VERSION ""

NS_ :

BS_:

BU_: Turbocharger OnBoardDataLogger OffBoardDiagnosticTool2 OffBoardDiagnosticTool1 FileServer ParkingBrakeController SeatControl2 FanDriveController SteeringColumnUnit CommunicationUnitRadio CommunicationUnitSatellite CommunicationUnitCellular PropulsionBatteryCharger ChassisController2 ChassisController1 EngineValveControl AuxiliaryHeater2 AuxiliaryHeater1 ClutchUnit RampControl InformationSystem1 SuspensionSystemController2 OilSensor VehicleDynamicStability ExhaustEmissionController TransmissionDisplay2 TransmissionDisplay1 ClimateControl2 WaterPumpController RearAxleSteeringController LightingOperatorControl SeatController1 IgnitionController2 IgnitionController1 TirePressureController CabController2 CabController1 PneumaticSystemController SuspensionSystemController1 HydraulicPumpController EnduranceBrakingSystem RetarderExhaustEngine2 OnBoardDiagnosticUnit HeadwayController RetarderExhaustEngine1 CabDisplay1 ManagementComputer VirtualTerminal OffVehicleGateway PowerTakeOffFront HitchControl AuxiliaryValveControl BodyController TractorTrailerBridge1 StarterSystem ElectricalSystem VehicleSecurity VehicleNavigation AerodynamicControl ElectricalChargingSystem ClimateControl1 TripRecorder InstrumentCluster SuspensionDriveAxle2 SuspensionDriveAxle1 SuspensionSteerAxle SteeringController FuelSystem CruiseControl RetarderDriveline RetarderEngine BrakesDriveAxle2 BrakesDriveAxle1 BrakesSystemController BrakesSteerAxle AxleDrive2 AxleDrive1 AxleSteering PowerTakeOff ShiftConsoleSecondary ShiftConsolePrimary Transmission2 Transmission1 Engine2 Engine1

BO_ 2365473278 LC: 8 Vector__XXX
 SG_ ImplementRearWorkLightCmd : 62|2@1+ (1,0) [0|3] "" Vector__XXX
 SG_ ImplementLeftForwardWorkLightCmd : 60|2@1+ (1,0) [0|3] "" Vector__XXX
 SG_ ImplmentRightForwardWorkLightCmd : 58|2@1+ (1,0) [0|3] "" Vector__XXX
 SG_ LightingDataRqCmd : 56|2@1+ (1,0) [0|3] "" Vector__XXX
 SG_ ImplementLeftFacingWorkLightCmd : 54|2@1+ (1,0) [0|3] "" Vector__XXX
 SG_ ImplementRightFacingWorkLightCmd : 52|2@1+ (1,0) [0|3] "" Vector__XXX
 SG_ ImplementOEMOption1LightCmd : 50|2@1+ (1,0) [0|3] "" Vector__XXX
 SG_ ImplementOEMOption2LightCmd : 48|2@1+ (1,0) [0|3] "" Vector__XXX
 SG_ TrctrFrntHghMountedWorkLightsCmd : 46|2@1+ (1,0) [0|3] "" Vector__XXX
 SG_ TrctrFrntLowMountedWorkLightsCmd : 44|2@1+ (1,0) [0|3] "" Vector__XXX
 SG_ TrctrSdeHighMountedWorkLightsCmd : 42|2@1+ (1,0) [0|3] "" Vector__XXX
 SG_ TrctrSideLowMountedWorkLightsCmd : 40|2@1+ (1,0) [0|3] "" Vector__XXX
 SG_ TrctrRarHighMountedWorkLightsCmd : 38|2@1+ (1,0) [0|3] "" Vector__XXX
 SG_ TrctrRearLowMountedWorkLightsCmd : 36|2@1+ (1,0) [0|3] "" Vector__XXX
 SG_ TrctrUndrsdeMountedWorkLightsCmd : 34|2@1+ (1,0) [0|3] "" Vector__XXX
 SG_ RearFogLightCmd : 32|2@1+ (1,0) [0|3] "" Vector__XXX
 SG_ TractorMarkerLightCmd : 30|2@1+ (1,0) [0|3] "" Vector__XXX
 SG_ ImplementMarkerLightCmd : 28|2@1+ (1,0) [0|3] "" Vector__XXX
 SG_ TractorClearanceLightCmd : 26|2@1+ (1,0) [0|3] "" Vector__XXX
 SG_ ImplementClearanceLightCmd : 24|2@1+ (1,0) [0|3] "" Vector__XXX
 SG_ LeftStopLightCmd : 22|2@1+ (1,0) [0|3] "" Vector__XXX
 SG_ RightStopLightCmd : 20|2@1+ (1,0) [0|3] "" Vector__XXX
 SG_ CenterStopLightCmd : 18|2@1+ (1,0) [0|3] "" Vector__XXX
 SG_ BackUpLightAndAlarmHornCmd : 16|2@1+ (1,0) [0|3] "" Vector__XXX
 SG_ LeftTurnSignalLightsCmd : 14|2@1+ (1,0) [0|3] "" Vector__XXX
 SG_ RightTurnSignalLightsCmd : 12|2@1+ (1,0) [0|3] "" Vector__XXX
 SG_ RotatingBeaconLightCmd : 10|2@1+ (1,0) [0|3] "" Vector__XXX
 SG_ TractorFrontFogLightsCmd : 8|2@1+ (1,0) [0|3] "" Vector__XXX
 SG_ HighBeamHeadLightCmd : 6|2@1+ (1,0) [0|3] "" Vector__XXX
 SG_ LowBeamHeadLightCmd : 4|2@1+ (1,0) [0|3] "" Vector__XXX
 SG_ AltBeamHeadLightCmd : 2|2@1+ (1,0) [0|3] "" Vector__XXX
 SG_ RunningLightCmd : 0|2@1+ (1,0) [0|3] "" Vector__XXX

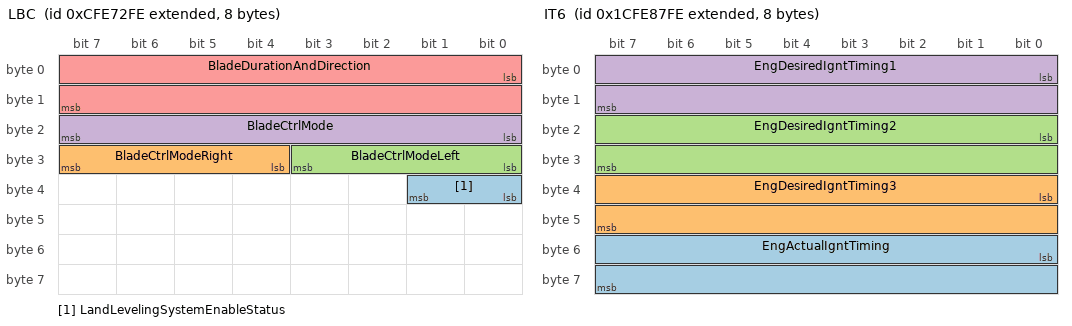
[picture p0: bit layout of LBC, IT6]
BO_ 2365485822 LBC: 8 Vector__XXX
 SG_ LandLevelingSystemEnableStatus : 32|2@1+ (1,0) [0|3] "" Vector__XXX
 SG_ BladeCtrlModeRight : 28|4@1+ (1,0) [0|15] "" Vector__XXX
 SG_ BladeCtrlModeLeft : 24|4@1+ (1,0) [0|15] "" Vector__XXX
 SG_ BladeCtrlMode : 16|8@1+ (1,0) [0|255] "" Vector__XXX
 SG_ BladeDurationAndDirection : 0|16@1+ (1,-3276.8) [-3276.8|3148.7] "sec" Vector__XXX

BO_ 2633926654 IT6: 8 Vector__XXX
 SG_ EngActualIgntTiming : 48|16@1+ (1,-200) [-200|301.99] "deg" Vector__XXX
 SG_ EngDesiredIgntTiming3 : 32|16@1+ (1,-200) [-200|301.99] "deg" Vector__XXX
 SG_ EngDesiredIgntTiming2 : 16|16@1+ (1,-200) [-200|301.99] "deg" Vector__XXX
 SG_ EngDesiredIgntTiming1 : 0|16@1+ (1,-200) [-200|301.99] "deg" Vector__XXX

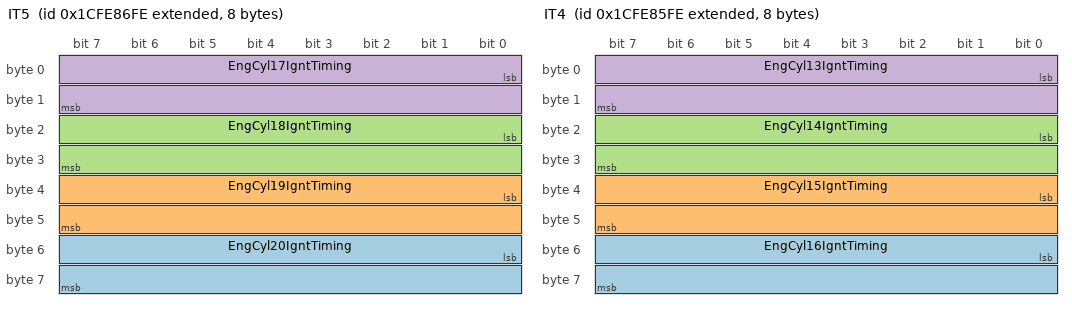
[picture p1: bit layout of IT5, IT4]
BO_ 2633926398 IT5: 8 Vector__XXX
 SG_ EngCyl20IgntTiming : 48|16@1+ (1,-200) [-200|301.99] "deg" Vector__XXX
 SG_ EngCyl19IgntTiming : 32|16@1+ (1,-200) [-200|301.99] "deg" Vector__XXX
 SG_ EngCyl18IgntTiming : 16|16@1+ (1,-200) [-200|301.99] "deg" Vector__XXX
 SG_ EngCyl17IgntTiming : 0|16@1+ (1,-200) [-200|301.99] "deg" Vector__XXX

BO_ 2633926142 IT4: 8 Vector__XXX
 SG_ EngCyl16IgntTiming : 48|16@1+ (1,-200) [-200|301.99] "deg" Vector__XXX
 SG_ EngCyl15IgntTiming : 32|16@1+ (1,-200) [-200|301.99] "deg" Vector__XXX
 SG_ EngCyl14IgntTiming : 16|16@1+ (1,-200) [-200|301.99] "deg" Vector__XXX
 SG_ EngCyl13IgntTiming : 0|16@1+ (1,-200) [-200|301.99] "deg" Vector__XXX

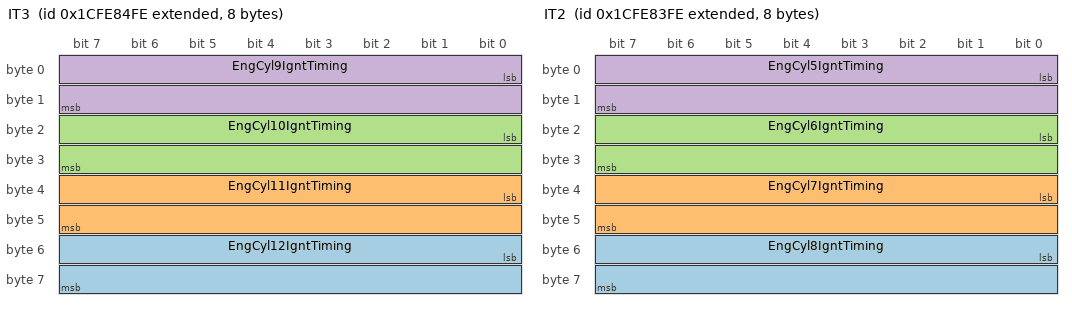
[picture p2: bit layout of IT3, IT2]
BO_ 2633925886 IT3: 8 Vector__XXX
 SG_ EngCyl12IgntTiming : 48|16@1+ (1,-200) [-200|301.99] "deg" Vector__XXX
 SG_ EngCyl11IgntTiming : 32|16@1+ (1,-200) [-200|301.99] "deg" Vector__XXX
 SG_ EngCyl10IgntTiming : 16|16@1+ (1,-200) [-200|301.99] "deg" Vector__XXX
 SG_ EngCyl9IgntTiming : 0|16@1+ (1,-200) [-200|301.99] "deg" Vector__XXX

BO_ 2633925630 IT2: 8 Vector__XXX
 SG_ EngCyl8IgntTiming : 48|16@1+ (1,-200) [-200|301.99] "deg" Vector__XXX
 SG_ EngCyl7IgntTiming : 32|16@1+ (1,-200) [-200|301.99] "deg" Vector__XXX
 SG_ EngCyl6IgntTiming : 16|16@1+ (1,-200) [-200|301.99] "deg" Vector__XXX
 SG_ EngCyl5IgntTiming : 0|16@1+ (1,-200) [-200|301.99] "deg" Vector__XXX

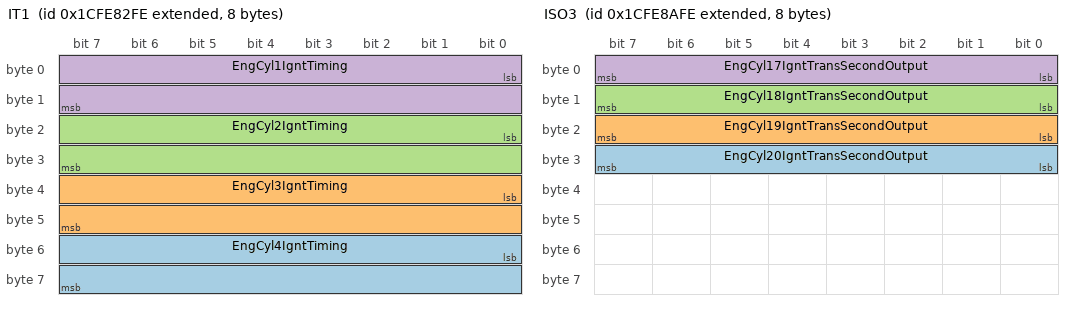
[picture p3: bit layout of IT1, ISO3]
BO_ 2633925374 IT1: 8 Vector__XXX
 SG_ EngCyl4IgntTiming : 48|16@1+ (1,-200) [-200|301.99] "deg" Vector__XXX
 SG_ EngCyl3IgntTiming : 32|16@1+ (1,-200) [-200|301.99] "deg" Vector__XXX
 SG_ EngCyl2IgntTiming : 16|16@1+ (1,-200) [-200|301.99] "deg" Vector__XXX
 SG_ EngCyl1IgntTiming : 0|16@1+ (1,-200) [-200|301.99] "deg" Vector__XXX

BO_ 2633927422 ISO3: 8 Vector__XXX
 SG_ EngCyl20IgntTransSecondOutput : 24|8@1+ (1,-125) [-125|125] "%" Vector__XXX
 SG_ EngCyl19IgntTransSecondOutput : 16|8@1+ (1,-125) [-125|125] "%" Vector__XXX
 SG_ EngCyl18IgntTransSecondOutput : 8|8@1+ (1,-125) [-125|125] "%" Vector__XXX
 SG_ EngCyl17IgntTransSecondOutput : 0|8@1+ (1,-125) [-125|125] "%" Vector__XXX

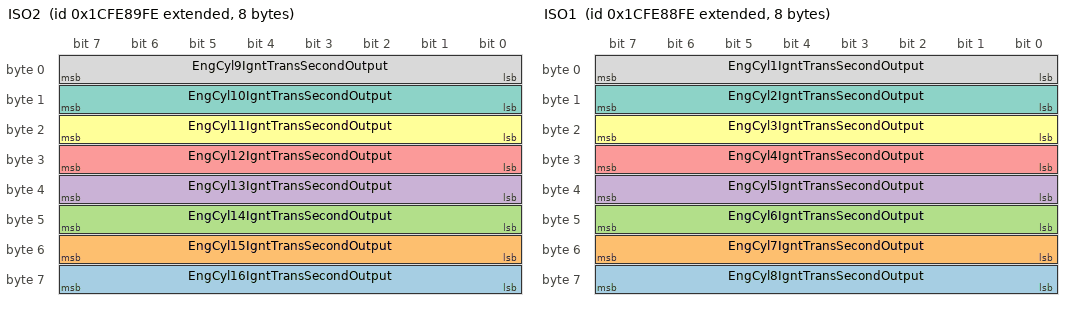
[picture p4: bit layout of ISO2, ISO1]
BO_ 2633927166 ISO2: 8 Vector__XXX
 SG_ EngCyl16IgntTransSecondOutput : 56|8@1+ (1,-125) [-125|125] "%" Vector__XXX
 SG_ EngCyl15IgntTransSecondOutput : 48|8@1+ (1,-125) [-125|125] "%" Vector__XXX
 SG_ EngCyl14IgntTransSecondOutput : 40|8@1+ (1,-125) [-125|125] "%" Vector__XXX
 SG_ EngCyl13IgntTransSecondOutput : 32|8@1+ (1,-125) [-125|125] "%" Vector__XXX
 SG_ EngCyl12IgntTransSecondOutput : 24|8@1+ (1,-125) [-125|125] "%" Vector__XXX
 SG_ EngCyl11IgntTransSecondOutput : 16|8@1+ (1,-125) [-125|125] "%" Vector__XXX
 SG_ EngCyl10IgntTransSecondOutput : 8|8@1+ (1,-125) [-125|125] "%" Vector__XXX
 SG_ EngCyl9IgntTransSecondOutput : 0|8@1+ (1,-125) [-125|125] "%" Vector__XXX

BO_ 2633926910 ISO1: 8 Vector__XXX
 SG_ EngCyl8IgntTransSecondOutput : 56|8@1+ (1,-125) [-125|125] "%" Vector__XXX
 SG_ EngCyl7IgntTransSecondOutput : 48|8@1+ (1,-125) [-125|125] "%" Vector__XXX
 SG_ EngCyl6IgntTransSecondOutput : 40|8@1+ (1,-125) [-125|125] "%" Vector__XXX
 SG_ EngCyl5IgntTransSecondOutput : 32|8@1+ (1,-125) [-125|125] "%" Vector__XXX
 SG_ EngCyl4IgntTransSecondOutput : 24|8@1+ (1,-125) [-125|125] "%" Vector__XXX
 SG_ EngCyl3IgntTransSecondOutput : 16|8@1+ (1,-125) [-125|125] "%" Vector__XXX
 SG_ EngCyl2IgntTransSecondOutput : 8|8@1+ (1,-125) [-125|125] "%" Vector__XXX
 SG_ EngCyl1IgntTransSecondOutput : 0|8@1+ (1,-125) [-125|125] "%" Vector__XXX

BO_ 2566768894 ISCS: 8 Vector__XXX
 SG_ EngOprtrPrmryIntrmdtSpdSlctState : 0|4@1+ (1,0) [0|15] "" Vector__XXX

BO_ 2566769406 ISC: 8 Vector__XXX
 SG_ EngOprtrPrmryIntrmdteSpeedSelect : 0|4@1+ (1,0) [0|15] "" Vector__XXX

BO_ 2566839550 IO: 8 Vector__XXX
 SG_ EngTotalIdleHours : 32|32@1+ (0.05,0) [0|210554060.75] "hr" Vector__XXX
 SG_ EngTotalIdleFuelUsed : 0|32@1+ (0.5,0) [0|2105540607.5] "L" Vector__XXX

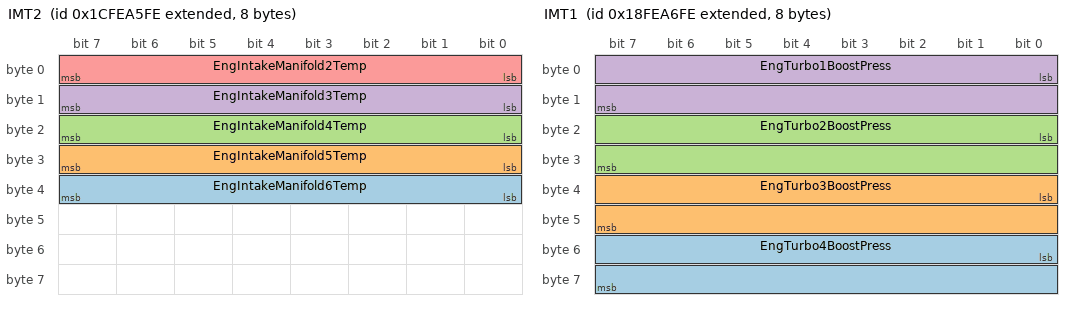
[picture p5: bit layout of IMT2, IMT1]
BO_ 2633934334 IMT2: 8 Vector__XXX
 SG_ EngIntakeManifold6Temp : 32|8@1+ (1,-40) [-40|210] "deg C" Vector__XXX
 SG_ EngIntakeManifold5Temp : 24|8@1+ (1,-40) [-40|210] "deg C" Vector__XXX
 SG_ EngIntakeManifold4Temp : 16|8@1+ (1,-40) [-40|210] "deg C" Vector__XXX
 SG_ EngIntakeManifold3Temp : 8|8@1+ (1,-40) [-40|210] "deg C" Vector__XXX
 SG_ EngIntakeManifold2Temp : 0|8@1+ (1,-40) [-40|210] "deg C" Vector__XXX

BO_ 2566825726 IMT1: 8 Vector__XXX
 SG_ EngTurbo4BoostPress : 48|16@1+ (0.125,0) [0|8031.875] "kPa" Vector__XXX
 SG_ EngTurbo3BoostPress : 32|16@1+ (0.125,0) [0|8031.875] "kPa" Vector__XXX
 SG_ EngTurbo2BoostPress : 16|16@1+ (0.125,0) [0|8031.875] "kPa" Vector__XXX
 SG_ EngTurbo1BoostPress : 0|16@1+ (0.125,0) [0|8031.875] "kPa" Vector__XXX

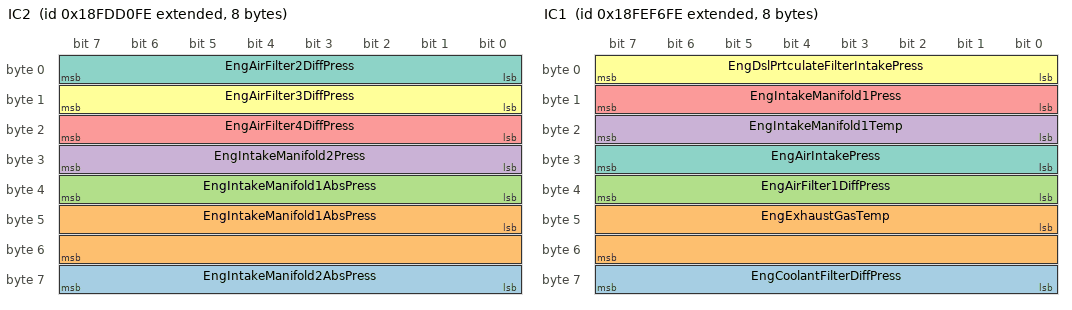
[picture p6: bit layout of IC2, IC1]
BO_ 2566770942 IC2: 8 Vector__XXX
 SG_ EngIntakeManifold2AbsPress : 56|8@1+ (2,0) [0|500] "kPa" Vector__XXX
 SG_ EngIntakeManifold1AbsPress : 40|16@1+ (0.1,0) [0|6425.5] "kPa" Vector__XXX
 SG_ EngIntakeManifold1AbsPress : 32|8@1+ (2,0) [0|500] "kPa" Vector__XXX
 SG_ EngIntakeManifold2Press : 24|8@1+ (2,0) [0|500] "kPa" Vector__XXX
 SG_ EngAirFilter4DiffPress : 16|8@1+ (0.05,0) [0|12.5] "kPa" Vector__XXX
 SG_ EngAirFilter3DiffPress : 8|8@1+ (0.05,0) [0|12.5] "kPa" Vector__XXX
 SG_ EngAirFilter2DiffPress : 0|8@1+ (0.05,0) [0|12.5] "kPa" Vector__XXX

BO_ 2566846206 IC1: 8 Vector__XXX
 SG_ EngCoolantFilterDiffPress : 56|8@1+ (0.5,0) [0|125] "kPa" Vector__XXX
 SG_ EngExhaustGasTemp : 40|16@1+ (0.03125,-273) [-273|1734.96875] "deg C" Vector__XXX
 SG_ EngAirFilter1DiffPress : 32|8@1+ (0.05,0) [0|12.5] "kPa" Vector__XXX
 SG_ EngIntakeManifold1Temp : 16|8@1+ (1,-40) [-40|210] "deg C" Vector__XXX
 SG_ EngIntakeManifold1Press : 8|8@1+ (2,0) [0|500] "kPa" Vector__XXX
 SG_ EngDslPrtculateFilterIntakePress : 0|8@1+ (0.5,0) [0|125] "kPa" Vector__XXX
 SG_ EngAirIntakePress : 24|8@1+ (2,0) [0|500] "kPa" Vector__XXX

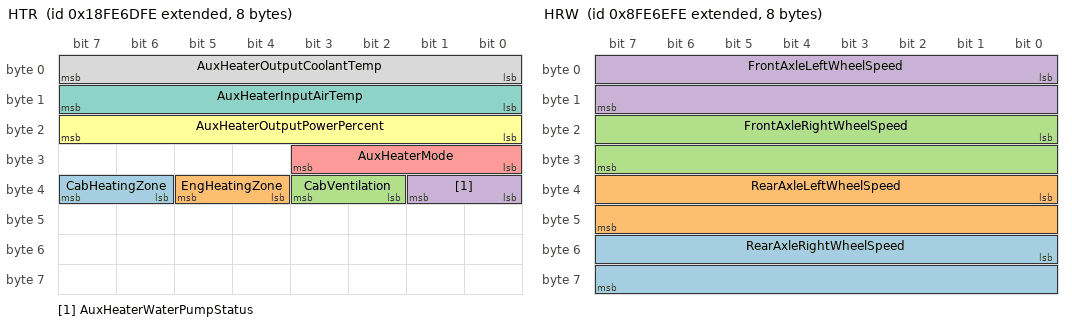
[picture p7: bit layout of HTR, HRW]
BO_ 2566811134 HTR: 8 Vector__XXX
 SG_ CabHeatingZone : 38|2@1+ (1,0) [0|3] "" Vector__XXX
 SG_ EngHeatingZone : 36|2@1+ (1,0) [0|3] "" Vector__XXX
 SG_ CabVentilation : 34|2@1+ (1,0) [0|3] "" Vector__XXX
 SG_ AuxHeaterWaterPumpStatus : 32|2@1+ (1,0) [0|3] "" Vector__XXX
 SG_ AuxHeaterMode : 24|4@1+ (1,0) [0|15] "" Vector__XXX
 SG_ AuxHeaterOutputPowerPercent : 16|8@1+ (0.4,0) [0|100] "%" Vector__XXX
 SG_ AuxHeaterInputAirTemp : 8|8@1+ (1,-40) [-40|210] "deg C" Vector__XXX
 SG_ AuxHeaterOutputCoolantTemp : 0|8@1+ (1,-40) [-40|210] "deg C" Vector__XXX

BO_ 2298375934 HRW: 8 Vector__XXX
 SG_ RearAxleRightWheelSpeed : 48|16@1+ (0.0039062485409696,0) [0|250.996] "km/h" Vector__XXX
 SG_ RearAxleLeftWheelSpeed : 32|16@1+ (0.0039062485409696,0) [0|250.996] "km/h" Vector__XXX
 SG_ FrontAxleRightWheelSpeed : 16|16@1+ (0.0039062485409696,0) [0|250.996] "km/h" Vector__XXX
 SG_ FrontAxleLeftWheelSpeed : 0|16@1+ (0.0039062485409696,0) [0|250.996] "km/h" Vector__XXX

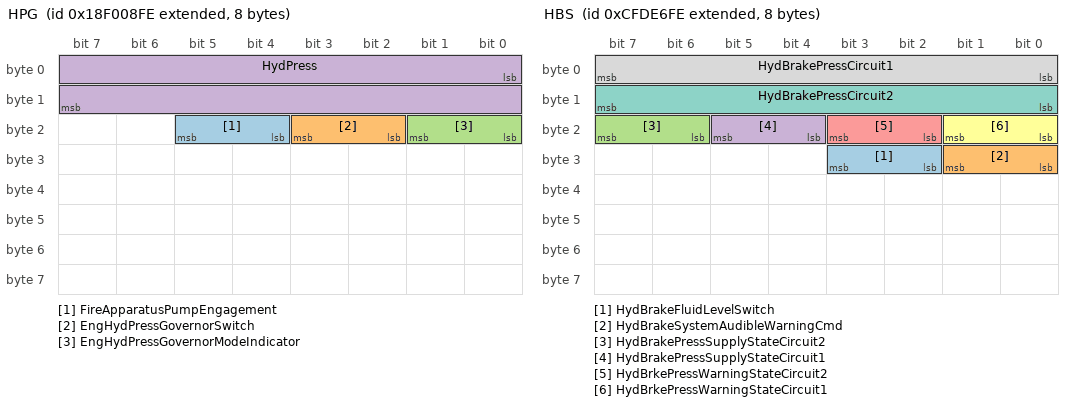
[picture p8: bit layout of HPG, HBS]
BO_ 2565867774 HPG: 8 Vector__XXX
 SG_ FireApparatusPumpEngagement : 20|2@1+ (1,0) [0|3] "" Vector__XXX
 SG_ EngHydPressGovernorSwitch : 18|2@1+ (1,0) [0|3] "" Vector__XXX
 SG_ EngHydPressGovernorModeIndicator : 16|2@1+ (1,0) [0|3] "" Vector__XXX
 SG_ HydPress : 0|16@1+ (2,0) [0|128510] "kPa" Vector__XXX

BO_ 2566841854 HOURS: 8 Vector__XXX
 SG_ EngTotalRevolutions : 32|32@1+ (1000,0) [0|4211081215000] "r" Vector__XXX
 SG_ EngTotalHoursOfOperation : 0|32@1+ (0.05,0) [0|210554060.75] "hr" Vector__XXX

BO_ 2365449982 HBS: 8 Vector__XXX
 SG_ HydBrakeFluidLevelSwitch : 26|2@1+ (1,0) [0|3] "" Vector__XXX
 SG_ HydBrakeSystemAudibleWarningCmd : 24|2@1+ (1,0) [0|3] "" Vector__XXX
 SG_ HydBrakePressSupplyStateCircuit2 : 22|2@1+ (1,0) [0|3] "" Vector__XXX
 SG_ HydBrakePressSupplyStateCircuit1 : 20|2@1+ (1,0) [0|3] "" Vector__XXX
 SG_ HydBrkePressWarningStateCircuit2 : 18|2@1+ (1,0) [0|3] "" Vector__XXX
 SG_ HydBrkePressWarningStateCircuit1 : 16|2@1+ (1,0) [0|3] "" Vector__XXX
 SG_ HydBrakePressCircuit2 : 8|8@1+ (0.1,0) [0|25] "MPa" Vector__XXX
 SG_ HydBrakePressCircuit1 : 0|8@1+ (0.1,0) [0|25] "MPa" Vector__XXX

BO_ 2633939198 GTFI: 22 Vector__XXX
 SG_ TripDriveFuelEconomy : 160|16@1+ (0.0019531553964672,0) [0|125.5] "km/kg" Vector__XXX
 SG_ TripCruiseFuelUsed : 128|32@1+ (0.5,0) [0|2105540607.5] "kg" Vector__XXX
 SG_ TripVehicleIdleFuelUsed : 96|32@1+ (0.5,0) [0|2105540607.5] "kg" Vector__XXX
 SG_ TripPTOGovernorNonmovingFuelUsed : 64|32@1+ (0.5,0) [0|2105540607.5] "kg" Vector__XXX
 SG_ TripPTOGovernorMovingFuelUsed : 32|32@1+ (0.5,0) [0|2105540607.5] "kg" Vector__XXX
 SG_ TripDriveFuelUsed : 0|32@1+ (0.5,0) [0|2105540607.5] "kg" Vector__XXX

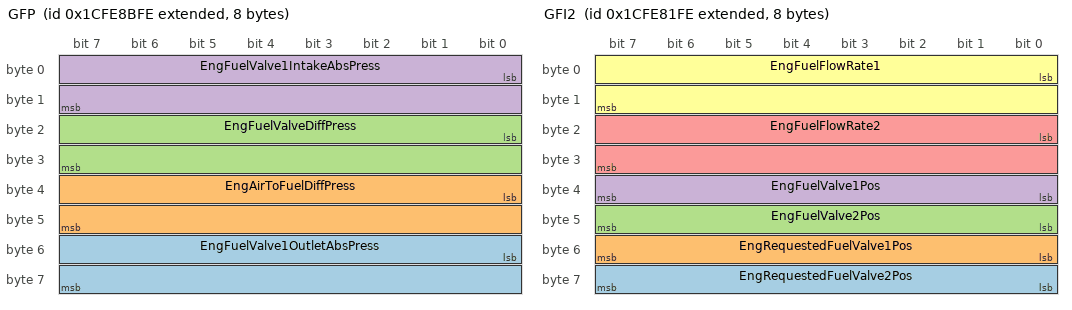
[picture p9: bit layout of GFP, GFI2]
BO_ 2633927678 GFP: 8 Vector__XXX
 SG_ EngFuelValve1OutletAbsPress : 48|16@1+ (0.1,0) [0|6425.5] "kPa" Vector__XXX
 SG_ EngAirToFuelDiffPress : 32|16@1+ (0.1,0) [0|6425.5] "kPa" Vector__XXX
 SG_ EngFuelValveDiffPress : 16|16@1+ (0.1,0) [0|6425.5] "kPa" Vector__XXX
 SG_ EngFuelValve1IntakeAbsPress : 0|16@1+ (0.1,0) [0|6425.5] "kPa" Vector__XXX

BO_ 2633925118 GFI2: 8 Vector__XXX
 SG_ EngRequestedFuelValve2Pos : 56|8@1+ (1,0) [0|100] "%" Vector__XXX
 SG_ EngRequestedFuelValve1Pos : 48|8@1+ (1,0) [0|100] "%" Vector__XXX
 SG_ EngFuelValve2Pos : 40|8@1+ (0.4,0) [0|100] "%" Vector__XXX
 SG_ EngFuelValve1Pos : 32|8@1+ (0.4,0) [0|100] "%" Vector__XXX
 SG_ EngFuelFlowRate2 : 16|16@1+ (0.1,0) [0|6425.5] "m^3/h" Vector__XXX
 SG_ EngFuelFlowRate1 : 0|16@1+ (0.1,0) [0|6425.5] "m^3/h" Vector__XXX

BO_ 2633937662 GFI1: 8 Vector__XXX
 SG_ EngFuelSpecificGravity : 48|16@1+ (1,0) [0|6.4255] "" Vector__XXX
 SG_ TripAverageFuelRate : 32|16@1+ (0.05,0) [0|3212.75] "kg/h" Vector__XXX
 SG_ TotalEngPTOGovernorFuelUsed : 0|32@1+ (0.5,0) [0|2105540607.5] "kg" Vector__XXX

BO_ 2566804990 GFD: 8 Vector__XXX
 SG_ SpecificHeatRatio : 0|16@1+ (1,0) [0|64.255] "" Vector__XXX

BO_ 2633936894 GFC: 8 Vector__XXX
 SG_ TotalFuelUsed : 32|32@1+ (0.5,0) [0|2105540607.5] "kg" Vector__XXX
 SG_ TripFuel : 0|32@1+ (0.5,0) [0|2105540607.5] "kg" Vector__XXX

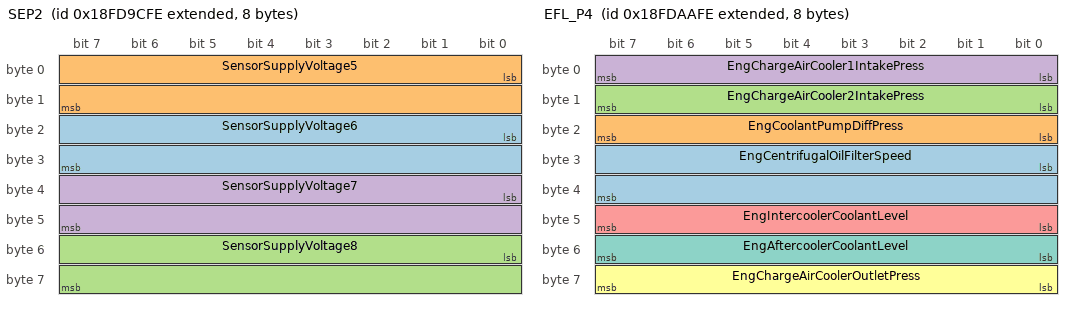
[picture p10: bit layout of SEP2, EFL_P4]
BO_ 2566757630 SEP2: 8 Vector__XXX
 SG_ SensorSupplyVoltage6 : 16|16@1+ (0.05,0) [0|3212.75] "V" Vector__XXX
 SG_ SensorSupplyVoltage5 : 0|16@1+ (0.05,0) [0|3212.75] "V" Vector__XXX
 SG_ SensorSupplyVoltage8 : 48|16@1+ (0.05,0) [0|3212.75] "V" Vector__XXX
 SG_ SensorSupplyVoltage7 : 32|16@1+ (0.05,0) [0|3212.75] "V" Vector__XXX

BO_ 2566757886 SEP1: 8 Vector__XXX
 SG_ SensorSupplyVoltage4 : 48|16@1+ (0.05,0) [0|3212.75] "V" Vector__XXX
 SG_ SensorSupplyVoltage3 : 32|16@1+ (0.05,0) [0|3212.75] "V" Vector__XXX
 SG_ SensorSupplyVoltage2 : 16|16@1+ (0.05,0) [0|3212.75] "V" Vector__XXX
 SG_ SensorSupplyVoltage1 : 0|16@1+ (0.05,0) [0|3212.75] "V" Vector__XXX

BO_ 2566759678 PTODE: 8 Vector__XXX
 SG_ AtLeastOnePTOEngaged : 48|2@1+ (1,0) [0|3] "" Vector__XXX
 SG_ EnggmntSttsPTOEngAccessoryDrive2 : 44|2@1+ (1,0) [0|3] "" Vector__XXX
 SG_ EnggmntSttsPTOEngAccessoryDrive1 : 42|2@1+ (1,0) [0|3] "" Vector__XXX
 SG_ EngagementStatusPTOEngFlywheel : 40|2@1+ (1,0) [0|3] "" Vector__XXX
 SG_ EnggmntStatusTransInputShaftPTO1 : 38|2@1+ (1,0) [0|3] "" Vector__XXX
 SG_ EnggmntStatusTransInputShaftPTO2 : 36|2@1+ (1,0) [0|3] "" Vector__XXX
 SG_ EnggmntStatusTransOutputShaftPTO : 34|2@1+ (1,0) [0|3] "" Vector__XXX
 SG_ EnggmntSttsTrnsfrCsOtputShaftPTO : 32|2@1+ (1,0) [0|3] "" Vector__XXX
 SG_ EnggmntCnsntPTOEngAccssoryDrive2 : 28|2@1+ (1,0) [0|3] "" Vector__XXX
 SG_ EnggmntCnsntPTOEngAccssoryDrive1 : 26|2@1+ (1,0) [0|3] "" Vector__XXX
 SG_ EngagementConsentPTOEngFlywheel : 24|2@1+ (1,0) [0|3] "" Vector__XXX
 SG_ EnggmntCnsentTransInputShaftPTO1 : 22|2@1+ (1,0) [0|3] "" Vector__XXX
 SG_ EnggmntCnsentTransInputShaftPTO2 : 20|2@1+ (1,0) [0|3] "" Vector__XXX
 SG_ EnggmntCnsentTransOutputShaftPTO : 18|2@1+ (1,0) [0|3] "" Vector__XXX
 SG_ EnggmntCnsntTrnsfrCsOtptShaftPTO : 16|2@1+ (1,0) [0|3] "" Vector__XXX
 SG_ EnbleSwitchPTOEngAccessoryDrive2 : 12|2@1+ (1,0) [0|3] "" Vector__XXX
 SG_ EnbleSwitchPTOEngAccessoryDrive1 : 10|2@1+ (1,0) [0|3] "" Vector__XXX
 SG_ EnableSwitchPTOEngFlywheel : 8|2@1+ (1,0) [0|3] "" Vector__XXX
 SG_ EnableSwitchTransInputShaftPTO1 : 6|2@1+ (1,0) [0|3] "" Vector__XXX
 SG_ EnableSwitchTransInputShaftPTO2 : 4|2@1+ (1,0) [0|3] "" Vector__XXX
 SG_ EnableSwitchTransOutputShaftPTO : 2|2@1+ (1,0) [0|3] "" Vector__XXX
 SG_ EnblSwtchTrnsfrCseOutputShaftPTO : 0|2@1+ (1,0) [0|3] "" Vector__XXX

BO_ 2432541438 GFI3: 8 Vector__XXX
 SG_ EngFuelValve2OutletAbsPress : 48|16@1+ (0.1,0) [0|6425.5] "kPa" Vector__XXX
 SG_ EngFuelTemp2 : 32|8@1+ (1,-40) [-40|210] "deg C" Vector__XXX
 SG_ EngGas2MassFlowRate : 16|16@1+ (0.05,0) [0|3212.75] "kg/h" Vector__XXX
 SG_ EngFuelValve2IntakeAbsPress : 0|16@1+ (0.1,0) [0|6425.5] "kPa" Vector__XXX

BO_ 2566761214 EFL_P4: 8 Vector__XXX
 SG_ EngCentrifugalOilFilterSpeed : 24|16@1+ (4,0) [0|257020] "rpm" Vector__XXX
 SG_ EngCoolantPumpDiffPress : 16|8@1+ (1.64,-7) [-7|403] "kPa" Vector__XXX
 SG_ EngChargeAirCooler2IntakePress : 8|8@1+ (2,0) [0|500] "kPa" Vector__XXX
 SG_ EngChargeAirCooler1IntakePress : 0|8@1+ (2,0) [0|500] "kPa" Vector__XXX
 SG_ EngIntercoolerCoolantLevel : 40|8@1+ (0.4,0) [0|100] "%" Vector__XXX
 SG_ EngChargeAirCoolerOutletPress : 56|8@1+ (2,0) [0|500] "kPa" Vector__XXX
 SG_ EngAftercoolerCoolantLevel : 48|8@1+ (0.4,0) [0|100] "%" Vector__XXX

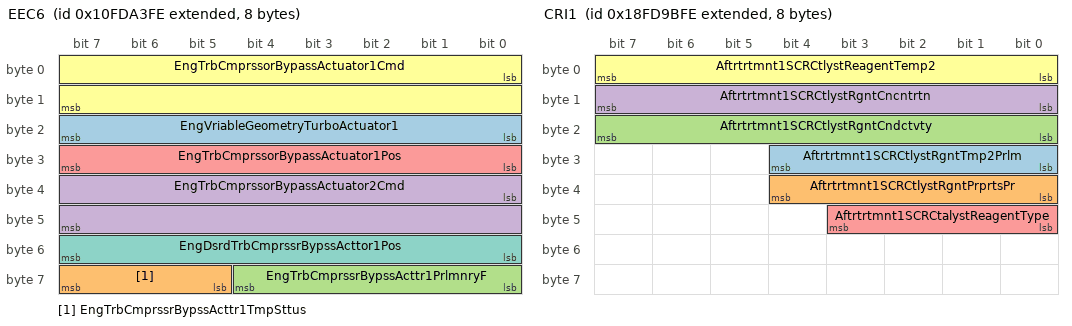
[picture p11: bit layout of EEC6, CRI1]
BO_ 2432541694 EEC6: 8 Vector__XXX
 SG_ EngVriableGeometryTurboActuator1 : 16|8@1+ (1,0) [0|100] "%" Vector__XXX
 SG_ EngTrbCmprssrBypssActtr1TmpSttus : 61|3@1+ (1,0) [0|7] "" Vector__XXX
 SG_ EngTrbCmprssrBypssActtr1PrlmnryF : 56|5@1+ (1,0) [0|31] "" Vector__XXX
 SG_ EngTrbCmprssorBypassActuator2Cmd : 32|16@1+ (1,0) [0|160.6375] "%" Vector__XXX
 SG_ EngTrbCmprssorBypassActuator1Pos : 24|8@1+ (0.4,0) [0|100] "%" Vector__XXX
 SG_ EngTrbCmprssorBypassActuator1Cmd : 0|16@1+ (1,0) [0|160.6375] "%" Vector__XXX
 SG_ EngDsrdTrbCmprssrBypssActtor1Pos : 48|8@1+ (0.4,0) [0|100] "%" Vector__XXX

BO_ 2566759934 DC2: 8 Vector__XXX
 SG_ EnableStatusOfDoor10 : 58|2@1+ (1,0) [0|3] "" Vector__XXX
 SG_ OpenStatusOfDoor10 : 56|2@1+ (1,0) [0|3] "" Vector__XXX
 SG_ LockStatusOfDoor10 : 54|2@1+ (1,0) [0|3] "" Vector__XXX
 SG_ EnableStatusOfDoor9 : 52|2@1+ (1,0) [0|3] "" Vector__XXX
 SG_ OpenStatusOfDoor9 : 50|2@1+ (1,0) [0|3] "" Vector__XXX
 SG_ LockStatusOfDoor9 : 48|2@1+ (1,0) [0|3] "" Vector__XXX
 SG_ EnableStatusOfDoor8 : 46|2@1+ (1,0) [0|3] "" Vector__XXX
 SG_ OpenStatusOfDoor8 : 44|2@1+ (1,0) [0|3] "" Vector__XXX
 SG_ LockStatusOfDoor8 : 42|2@1+ (1,0) [0|3] "" Vector__XXX
 SG_ EnableStatusOfDoor7 : 40|2@1+ (1,0) [0|3] "" Vector__XXX
 SG_ OpenStatusOfDoor7 : 38|2@1+ (1,0) [0|3] "" Vector__XXX
 SG_ LockStatusOfDoor7 : 36|2@1+ (1,0) [0|3] "" Vector__XXX
 SG_ EnableStatusOfDoor6 : 34|2@1+ (1,0) [0|3] "" Vector__XXX
 SG_ OpenStatusOfDoor6 : 32|2@1+ (1,0) [0|3] "" Vector__XXX
 SG_ LockStatusOfDoor6 : 30|2@1+ (1,0) [0|3] "" Vector__XXX
 SG_ EnableStatusOfDoor5 : 28|2@1+ (1,0) [0|3] "" Vector__XXX
 SG_ OpenStatusOfDoor5 : 26|2@1+ (1,0) [0|3] "" Vector__XXX
 SG_ LockStatusOfDoor5 : 24|2@1+ (1,0) [0|3] "" Vector__XXX
 SG_ EnableStatusOfDoor4 : 22|2@1+ (1,0) [0|3] "" Vector__XXX
 SG_ OpenStatusOfDoor4 : 20|2@1+ (1,0) [0|3] "" Vector__XXX
 SG_ LockStatusOfDoor4 : 18|2@1+ (1,0) [0|3] "" Vector__XXX
 SG_ EnableStatusOfDoor3 : 16|2@1+ (1,0) [0|3] "" Vector__XXX
 SG_ OpenStatusOfDoor3 : 14|2@1+ (1,0) [0|3] "" Vector__XXX
 SG_ LockStatusOfDoor3 : 12|2@1+ (1,0) [0|3] "" Vector__XXX
 SG_ EnableStatusOfDoor2 : 10|2@1+ (1,0) [0|3] "" Vector__XXX
 SG_ OpenStatusOfDoor2 : 8|2@1+ (1,0) [0|3] "" Vector__XXX
 SG_ LockStatusOfDoor2 : 6|2@1+ (1,0) [0|3] "" Vector__XXX
 SG_ EnableStatusOfDoor1 : 4|2@1+ (1,0) [0|3] "" Vector__XXX
 SG_ OpenStatusOfDoor1 : 2|2@1+ (1,0) [0|3] "" Vector__XXX
 SG_ LockStatusOfDoor1 : 0|2@1+ (1,0) [0|3] "" Vector__XXX

BO_ 2566757374 CRI1: 8 Vector__XXX
 SG_ Aftrtrtmnt1SCRCtlystRgntTmp2Prlm : 24|5@1+ (1,0) [0|31] "" Vector__XXX
 SG_ Aftrtrtmnt1SCRCtlystRgntPrprtsPr : 32|5@1+ (1,0) [0|31] "" Vector__XXX
 SG_ Aftrtrtmnt1SCRCtlystRgntCndctvty : 16|8@1+ (5,0) [0|1250] "microSiemens/mm" Vector__XXX
 SG_ Aftrtrtmnt1SCRCtlystRgntCncntrtn : 8|8@1+ (0.25,0) [0|62.5] "%" Vector__XXX
 SG_ Aftrtrtmnt1SCRCtalystReagentType : 40|4@1+ (1,0) [0|15] "" Vector__XXX
 SG_ Aftrtrtmnt1SCRCtlystReagentTemp2 : 0|8@1+ (1,-40) [-40|210] "deg C" Vector__XXX

BO_ 2364546302 RGAAQ: 8 Vector__XXX
 SG_ RqdGnrtrAvrgLneLineACRMSVoltage : 0|32@1+ (0.0078125,0) [0|32899071] "V" Vector__XXX

BO_ 2431654654 TFAC: 8 Vector__XXX
 SG_ EngFuelActuator2CtrlCmd : 48|16@1+ (1,0) [0|160.6375] "%" Vector__XXX
 SG_ EngFuelActuator1CtrlCmd : 32|16@1+ (1,0) [0|160.6375] "%" Vector__XXX
 SG_ EngThrottleActuator2CtrlCmd : 16|16@1+ (1,0) [0|160.6375] "%" Vector__XXX
 SG_ EngThrottleActuator1CtrlCmd : 0|16@1+ (1,0) [0|160.6375] "%" Vector__XXX

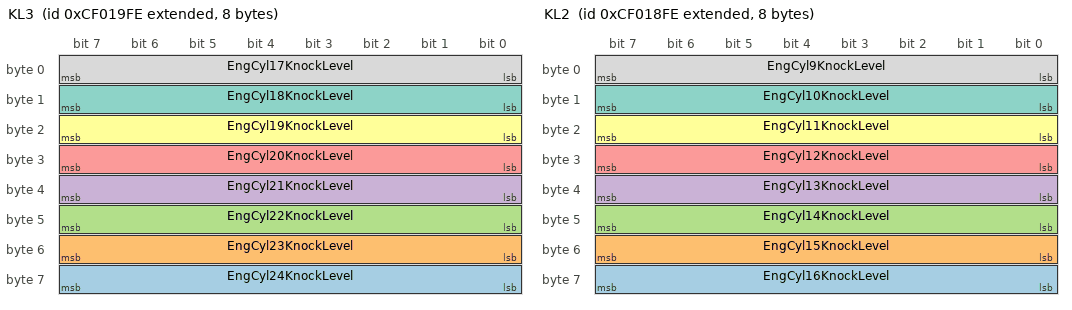
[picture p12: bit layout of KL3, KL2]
BO_ 2364545534 KL3: 8 Vector__XXX
 SG_ EngCyl24KnockLevel : 56|8@1+ (1,0) [0|250] "%" Vector__XXX
 SG_ EngCyl23KnockLevel : 48|8@1+ (1,0) [0|250] "%" Vector__XXX
 SG_ EngCyl22KnockLevel : 40|8@1+ (1,0) [0|250] "%" Vector__XXX
 SG_ EngCyl21KnockLevel : 32|8@1+ (1,0) [0|250] "%" Vector__XXX
 SG_ EngCyl20KnockLevel : 24|8@1+ (1,0) [0|250] "%" Vector__XXX
 SG_ EngCyl19KnockLevel : 16|8@1+ (1,0) [0|250] "%" Vector__XXX
 SG_ EngCyl18KnockLevel : 8|8@1+ (1,0) [0|250] "%" Vector__XXX
 SG_ EngCyl17KnockLevel : 0|8@1+ (1,0) [0|250] "%" Vector__XXX

BO_ 2364545278 KL2: 8 Vector__XXX
 SG_ EngCyl16KnockLevel : 56|8@1+ (1,0) [0|250] "%" Vector__XXX
 SG_ EngCyl15KnockLevel : 48|8@1+ (1,0) [0|250] "%" Vector__XXX
 SG_ EngCyl14KnockLevel : 40|8@1+ (1,0) [0|250] "%" Vector__XXX
 SG_ EngCyl13KnockLevel : 32|8@1+ (1,0) [0|250] "%" Vector__XXX
 SG_ EngCyl12KnockLevel : 24|8@1+ (1,0) [0|250] "%" Vector__XXX
 SG_ EngCyl11KnockLevel : 16|8@1+ (1,0) [0|250] "%" Vector__XXX
 SG_ EngCyl10KnockLevel : 8|8@1+ (1,0) [0|250] "%" Vector__XXX
 SG_ EngCyl9KnockLevel : 0|8@1+ (1,0) [0|250] "%" Vector__XXX

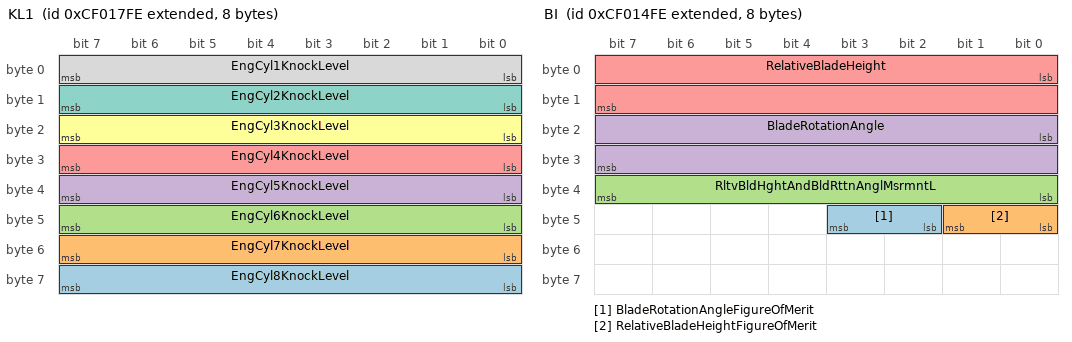
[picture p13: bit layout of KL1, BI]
BO_ 2364545022 KL1: 8 Vector__XXX
 SG_ EngCyl8KnockLevel : 56|8@1+ (1,0) [0|250] "%" Vector__XXX
 SG_ EngCyl7KnockLevel : 48|8@1+ (1,0) [0|250] "%" Vector__XXX
 SG_ EngCyl6KnockLevel : 40|8@1+ (1,0) [0|250] "%" Vector__XXX
 SG_ EngCyl5KnockLevel : 32|8@1+ (1,0) [0|250] "%" Vector__XXX
 SG_ EngCyl4KnockLevel : 24|8@1+ (1,0) [0|250] "%" Vector__XXX
 SG_ EngCyl3KnockLevel : 16|8@1+ (1,0) [0|250] "%" Vector__XXX
 SG_ EngCyl2KnockLevel : 8|8@1+ (1,0) [0|250] "%" Vector__XXX
 SG_ EngCyl1KnockLevel : 0|8@1+ (1,0) [0|250] "%" Vector__XXX

BO_ 2364544766 CCS: 8 Vector__XXX
 SG_ EngCyl24CombustionStatus : 46|2@1+ (1,0) [0|3] "" Vector__XXX
 SG_ EngCyl23CombustionStatus : 44|2@1+ (1,0) [0|3] "" Vector__XXX
 SG_ EngCyl22CombustionStatus : 42|2@1+ (1,0) [0|3] "" Vector__XXX
 SG_ EngCyl21CombustionStatus : 40|2@1+ (1,0) [0|3] "" Vector__XXX
 SG_ EngCyl20CombustionStatus : 38|2@1+ (1,0) [0|3] "" Vector__XXX
 SG_ EngCyl19CombustionStatus : 36|2@1+ (1,0) [0|3] "" Vector__XXX
 SG_ EngCyl18CombustionStatus : 34|2@1+ (1,0) [0|3] "" Vector__XXX
 SG_ EngCyl17CombustionStatus : 32|2@1+ (1,0) [0|3] "" Vector__XXX
 SG_ EngCyl16CombustionStatus : 30|2@1+ (1,0) [0|3] "" Vector__XXX
 SG_ EngCyl15CombustionStatus : 28|2@1+ (1,0) [0|3] "" Vector__XXX
 SG_ EngCyl14CombustionStatus : 26|2@1+ (1,0) [0|3] "" Vector__XXX
 SG_ EngCyl13CombustionStatus : 24|2@1+ (1,0) [0|3] "" Vector__XXX
 SG_ EngCyl12CombustionStatus : 22|2@1+ (1,0) [0|3] "" Vector__XXX
 SG_ EngCyl11CombustionStatus : 20|2@1+ (1,0) [0|3] "" Vector__XXX
 SG_ EngCyl10CombustionStatus : 18|2@1+ (1,0) [0|3] "" Vector__XXX
 SG_ EngCyl9CombustionStatus : 16|2@1+ (1,0) [0|3] "" Vector__XXX
 SG_ EngCyl8CombustionStatus : 14|2@1+ (1,0) [0|3] "" Vector__XXX
 SG_ EngCyl7CombustionStatus : 12|2@1+ (1,0) [0|3] "" Vector__XXX
 SG_ EngCyl6CombustionStatus : 10|2@1+ (1,0) [0|3] "" Vector__XXX
 SG_ EngCyl5CombustionStatus : 8|2@1+ (1,0) [0|3] "" Vector__XXX
 SG_ EngCyl4CombustionStatus : 6|2@1+ (1,0) [0|3] "" Vector__XXX
 SG_ EngCyl3CombustionStatus : 4|2@1+ (1,0) [0|3] "" Vector__XXX
 SG_ EngCyl2CombustionStatus : 2|2@1+ (1,0) [0|3] "" Vector__XXX
 SG_ EngCyl1CombustionStatus : 0|2@1+ (1,0) [0|3] "" Vector__XXX

BO_ 2364544510 RGTARP: 8 Vector__XXX
 SG_ RqGenOverallPowerFactorLagging : 48|2@1+ (1,0) [0|4] "" Vector__XXX
 SG_ RqGeneratorOverallPowerFactor : 32|16@1+ (6.103515625E-005,-1) [-1|2.921814] "" Vector__XXX
 SG_ RqGeneratorTotalACReactivePower : 0|32@1+ (1,-2000000000) [-2000000000|2000000000] "VA" Vector__XXX

BO_ 2364544254 BI: 8 Vector__XXX
 SG_ BladeRotationAngleFigureOfMerit : 42|2@1+ (1,0) [0|3] "" Vector__XXX
 SG_ RelativeBladeHeightFigureOfMerit : 40|2@1+ (1,0) [0|3] "" Vector__XXX
 SG_ RltvBldHghtAndBldRttnAnglMsrmntL : 32|8@1+ (0.5,0) [0|125] "ms" Vector__XXX
 SG_ BladeRotationAngle : 16|16@1+ (0.0078124659559567,-200) [-200|301.99] "deg" Vector__XXX
 SG_ RelativeBladeHeight : 0|16@1+ (0.1,-3200) [-3200|3225.5] "mm" Vector__XXX

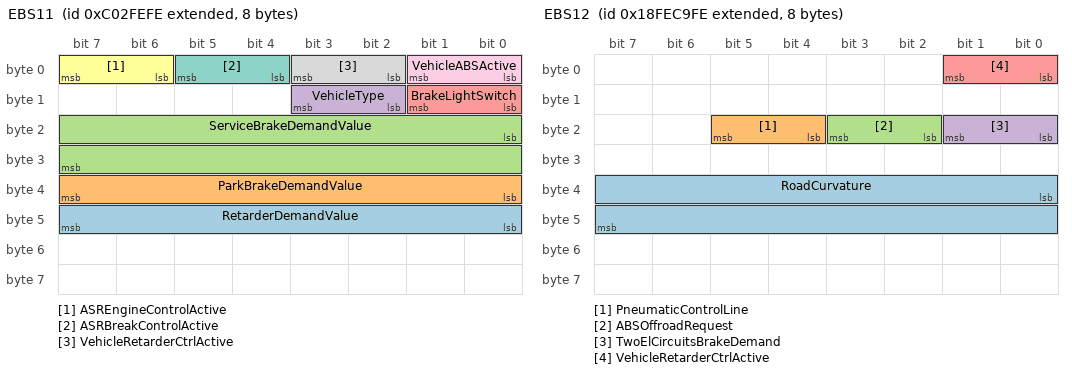
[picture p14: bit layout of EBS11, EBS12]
BO_ 2349006590 EBS11: 8 Vector__XXX
 SG_ RetarderDemandValue : 40|8@1+ (1,-125) [-125|125] "%" Vector__XXX
 SG_ ParkBrakeDemandValue : 32|8@1+ (0.4,0) [0|100] "%" Vector__XXX
 SG_ ServiceBrakeDemandValue : 16|16@1+ (0.01953125,0) [0|1255] "kPa" Vector__XXX
 SG_ VehicleType : 10|2@1+ (1,0) [0|3] "" Vector__XXX
 SG_ BrakeLightSwitch : 8|2@1+ (1,0) [0|3] "" Vector__XXX
 SG_ ASREngineControlActive : 6|2@1+ (1,0) [0|3] "" Vector__XXX
 SG_ ASRBreakControlActive : 4|2@1+ (1,0) [0|3] "" Vector__XXX
 SG_ VehicleRetarderCtrlActive : 2|2@1+ (1,0) [0|3] "" Vector__XXX
 SG_ VehicleABSActive : 0|2@1+ (1,0) [0|1] "" Vector__XXX

BO_ 2566834686 EBS12: 8 Vector__XXX
 SG_ RoadCurvature : 32|16@1+ (1,-250) [-250|251.992] "1/km" Vector__XXX
 SG_ PneumaticControlLine : 20|2@1+ (1,0) [0|1] "" Vector__XXX
 SG_ ABSOffroadRequest : 18|2@1+ (1,0) [0|1] "" Vector__XXX
 SG_ TwoElCircuitsBrakeDemand : 16|2@1+ (1,0) [0|1] "" Vector__XXX
 SG_ VehicleRetarderCtrlActive : 0|2@1+ (1,0) [0|3] "" Vector__XXX

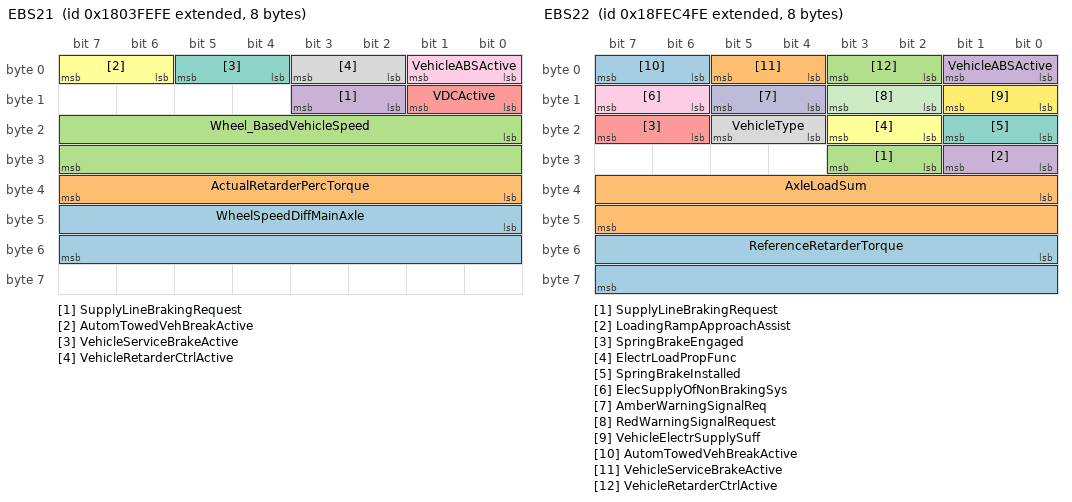
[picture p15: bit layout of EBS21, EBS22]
BO_ 2550398718 EBS21: 8 Vector__XXX
 SG_ WheelSpeedDiffMainAxle : 40|16@1+ (0.00390625,-125) [-125|125] "km/hr" Vector__XXX
 SG_ ActualRetarderPercTorque : 32|8@1+ (1,-125) [-125|125] "%" Vector__XXX
 SG_ Wheel_BasedVehicleSpeed : 16|16@1+ (0.00390625,0) [0|251] "km/hr" Vector__XXX
 SG_ SupplyLineBrakingRequest : 10|2@1+ (1,0) [0|1] "" Vector__XXX
 SG_ VDCActive : 8|2@1+ (1,0) [0|1] "" Vector__XXX
 SG_ AutomTowedVehBreakActive : 6|2@1+ (1,0) [0|1] "" Vector__XXX
 SG_ VehicleServiceBrakeActive : 4|2@1+ (1,0) [0|1] "" Vector__XXX
 SG_ VehicleRetarderCtrlActive : 2|2@1+ (1,0) [0|3] "" Vector__XXX
 SG_ VehicleABSActive : 0|2@1+ (1,0) [0|1] "" Vector__XXX

BO_ 2566833406 EBS22: 8 Vector__XXX
 SG_ ReferenceRetarderTorque : 48|16@1+ (1,0) [0|64255] "Nm" Vector__XXX
 SG_ AxleLoadSum : 32|16@1+ (2,0) [0|128510] "kg" Vector__XXX
 SG_ SupplyLineBrakingRequest : 26|2@1+ (1,0) [0|1] "" Vector__XXX
 SG_ LoadingRampApproachAssist : 24|2@1+ (1,0) [0|1] "" Vector__XXX
 SG_ SpringBrakeEngaged : 22|2@1+ (1,0) [0|1] "" Vector__XXX
 SG_ ElectrLoadPropFunc : 18|2@1+ (1,0) [0|1] "" Vector__XXX
 SG_ SpringBrakeInstalled : 16|2@1+ (1,0) [0|1] "" Vector__XXX
 SG_ VehicleType : 20|2@1+ (1,0) [0|3] "" Vector__XXX
 SG_ ElecSupplyOfNonBrakingSys : 14|2@1+ (1,0) [0|1] "" Vector__XXX
 SG_ AmberWarningSignalReq : 12|2@1+ (1,0) [0|1] "" Vector__XXX
 SG_ RedWarningSignalRequest : 10|2@1+ (1,0) [0|1] "" Vector__XXX
 SG_ VehicleElectrSupplySuff : 8|2@1+ (1,0) [0|1] "" Vector__XXX
 SG_ AutomTowedVehBreakActive : 6|2@1+ (1,0) [0|1] "" Vector__XXX
 SG_ VehicleServiceBrakeActive : 4|2@1+ (1,0) [0|1] "" Vector__XXX
 SG_ VehicleRetarderCtrlActive : 2|2@1+ (1,0) [0|3] "" Vector__XXX
 SG_ VehicleABSActive : 0|2@1+ (1,0) [0|1] "" Vector__XXX

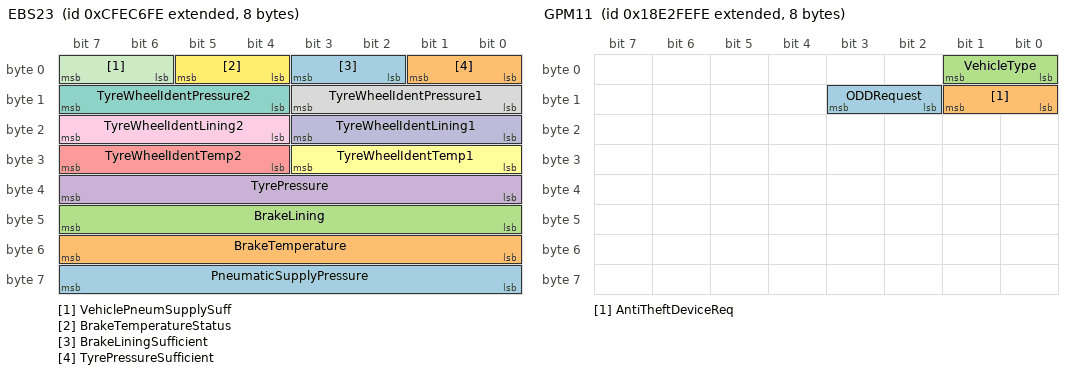
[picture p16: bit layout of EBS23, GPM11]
BO_ 2365507326 EBS23: 8 Vector__XXX
 SG_ PneumaticSupplyPressure : 56|8@1+ (5,0) [0|1250] "kPa" Vector__XXX
 SG_ BrakeTemperature : 48|8@1+ (10,0) [0|2500] "°C" Vector__XXX
 SG_ BrakeLining : 40|8@1+ (0.4,0) [0|100] "%" Vector__XXX
 SG_ TyrePressure : 32|8@1+ (10,0) [0|2500] "kPa" Vector__XXX
 SG_ TyreWheelIdentTemp2 : 28|4@1+ (1,0) [0|15] "" Vector__XXX
 SG_ TyreWheelIdentTemp1 : 24|4@1+ (1,0) [0|15] "" Vector__XXX
 SG_ TyreWheelIdentPressure2 : 12|4@1+ (1,0) [0|15] "" Vector__XXX
 SG_ TyreWheelIdentPressure1 : 8|4@1+ (1,0) [0|15] "" Vector__XXX
 SG_ TyreWheelIdentLining2 : 20|4@1+ (1,0) [0|15] "" Vector__XXX
 SG_ TyreWheelIdentLining1 : 16|4@1+ (1,0) [0|15] "" Vector__XXX
 SG_ VehiclePneumSupplySuff : 6|2@1+ (1,0) [0|1] "" Vector__XXX
 SG_ BrakeTemperatureStatus : 4|2@1+ (1,0) [0|1] "" Vector__XXX
 SG_ BrakeLiningSufficient : 2|2@1+ (1,0) [0|1] "" Vector__XXX
 SG_ TyrePressureSufficient : 0|2@1+ (1,0) [0|1] "" Vector__XXX

BO_ 2565013246 GPM11: 8 Vector__XXX
 SG_ ODDRequest : 10|2@1+ (1,0) [0|3] "" Vector__XXX
 SG_ AntiTheftDeviceReq : 8|2@1+ (1,0) [0|3] "" Vector__XXX
 SG_ VehicleType : 0|2@1+ (1,0) [0|3] "" Vector__XXX

BO_ 2566807038 GPM12: 8 Vector__XXX
 SG_ MaxVehicleSpeedLimit : 32|8@1+ (1,0) [0|250] "km/h" Vector__XXX
 SG_ EngineSpeedUpperLimit : 0|16@1+ (0.125,0) [0|8031.875] "rpm" Vector__XXX
 SG_ EngineSpeedLowerLimit : 16|16@1+ (0.125,0) [0|8191.875] "rpm" Vector__XXX

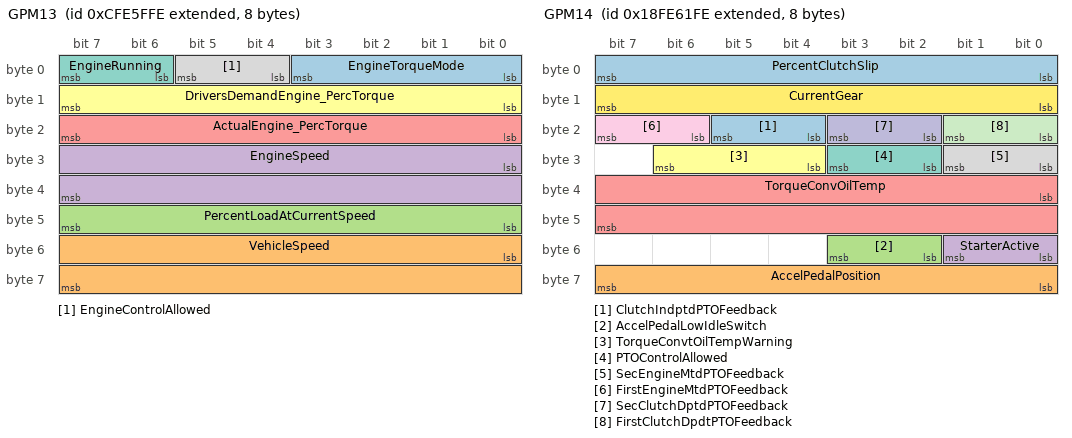
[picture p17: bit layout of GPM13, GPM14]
BO_ 2365480958 GPM13: 8 Vector__XXX
 SG_ EngineTorqueMode : 0|4@1+ (1,0) [0|15] "" Vector__XXX
 SG_ VehicleSpeed : 48|16@1+ (0.00390625,0) [0|250.996] "km/hr" Vector__XXX
 SG_ PercentLoadAtCurrentSpeed : 40|8@1+ (1,0) [0|125] "%" Vector__XXX
 SG_ EngineSpeed : 24|16@1+ (0.125,0) [0|8031.88] "rpm" Vector__XXX
 SG_ ActualEngine_PercTorque : 16|8@1+ (1,-125) [-125|125] "%" Vector__XXX
 SG_ DriversDemandEngine_PercTorque : 8|8@1+ (1,-125) [-125|125] "%" Vector__XXX
 SG_ EngineRunning : 6|2@1+ (1,0) [0|1] "" Vector__XXX
 SG_ EngineControlAllowed : 4|2@1+ (1,0) [0|1] "" Vector__XXX

BO_ 2566808062 GPM14: 8 Vector__XXX
 SG_ ClutchIndptdPTOFeedback : 20|2@1+ (1,0) [0|1] "" Vector__XXX
 SG_ AccelPedalPosition : 56|8@1+ (0.4,0) [0|100] "%" Vector__XXX
 SG_ AccelPedalLowIdleSwitch : 50|2@1+ (1,0) [0|1] "" Vector__XXX
 SG_ StarterActive : 48|2@1+ (1,0) [0|1] "" Vector__XXX
 SG_ TorqueConvOilTemp : 32|16@1+ (0.03125,-273) [-273|1735] "°C" Vector__XXX
 SG_ TorqueConvtOilTempWarning : 28|3@1+ (1,0) [0|2] "" Vector__XXX
 SG_ PTOControlAllowed : 26|2@1+ (1,0) [0|1] "" Vector__XXX
 SG_ SecEngineMtdPTOFeedback : 24|2@1+ (1,0) [0|1] "" Vector__XXX
 SG_ FirstEngineMtdPTOFeedback : 22|2@1+ (1,0) [0|1] "" Vector__XXX
 SG_ SecClutchDptdPTOFeedback : 18|2@1+ (1,0) [0|1] "" Vector__XXX
 SG_ FirstClutchDpdtPTOFeedback : 16|2@1+ (1,0) [0|1] "" Vector__XXX
 SG_ CurrentGear : 8|8@1+ (1,-125) [-125|125] "" Vector__XXX
 SG_ PercentClutchSlip : 0|8@1+ (0.4,0) [0|100] "%" Vector__XXX

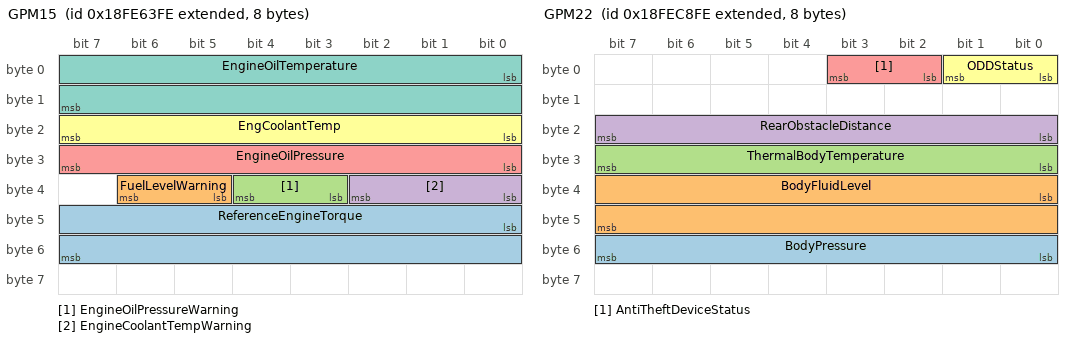
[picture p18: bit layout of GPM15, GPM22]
BO_ 2566808574 GPM15: 8 Vector__XXX
 SG_ ReferenceEngineTorque : 40|16@1+ (1,0) [0|64255] "Nm" Vector__XXX
 SG_ FuelLevelWarning : 37|2@1+ (1,0) [0|1] "" Vector__XXX
 SG_ EngineOilPressureWarning : 35|2@1+ (1,0) [0|1] "" Vector__XXX
 SG_ EngineCoolantTempWarning : 32|3@1+ (1,0) [0|2] "" Vector__XXX
 SG_ EngineOilPressure : 24|8@1+ (4,0) [0|1000] "kPa" Vector__XXX
 SG_ EngCoolantTemp : 16|8@1+ (1,-40) [-40|210] "deg C" Vector__XXX
 SG_ EngineOilTemperature : 0|16@1+ (0.03125,-273) [-273|1735] "°C" Vector__XXX

BO_ 2566809086 GPM16: 8 Vector__XXX
 SG_ AmbientAirTemperature : 0|16@1+ (0.03125,-273) [-273|1735] "°C" Vector__XXX

BO_ 2564947710 GPM21: 8 Vector__XXX
 SG_ VehicleType : 0|2@1+ (1,0) [0|3] "" Vector__XXX

BO_ 2566834430 GPM22: 8 Vector__XXX
 SG_ BodyPressure : 48|8@1+ (0.1,0) [0|25] "bar" Vector__XXX
 SG_ BodyFluidLevel : 32|16@1+ (2,0) [0|128510] "L" Vector__XXX
 SG_ ThermalBodyTemperature : 24|8@1+ (1,-125) [-125|125] "°C" Vector__XXX
 SG_ RearObstacleDistance : 16|8@1+ (2,0) [0|500] "cm" Vector__XXX
 SG_ AntiTheftDeviceStatus : 2|2@1+ (1,0) [0|1] "" Vector__XXX
 SG_ ODDStatus : 0|2@1+ (1,0) [0|1] "" Vector__XXX

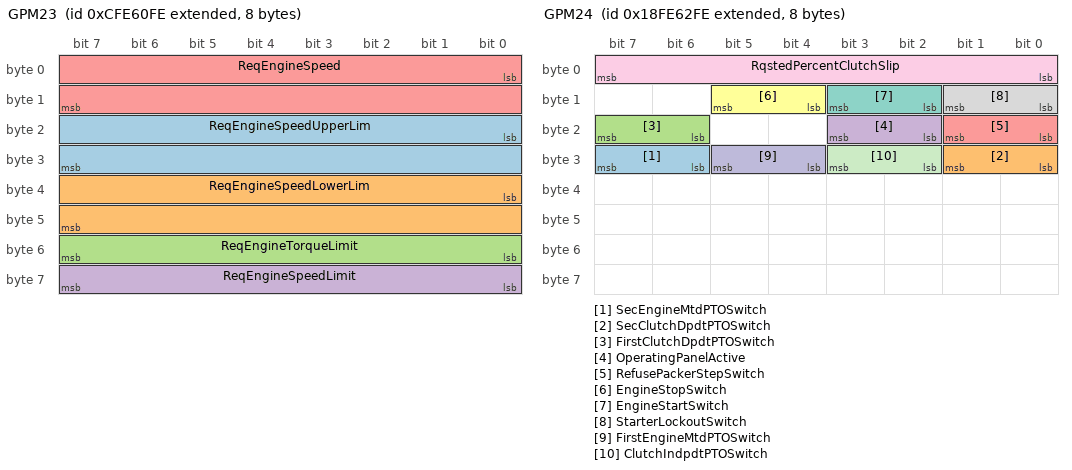
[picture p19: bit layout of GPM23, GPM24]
BO_ 2365481214 GPM23: 8 Vector__XXX
 SG_ ReqEngineSpeedUpperLim : 16|16@1+ (0.125,0) [0|8031.875] "rpm" Vector__XXX
 SG_ ReqEngineSpeedLowerLim : 32|16@1+ (0.125,0) [0|8031.875] "rpm" Vector__XXX
 SG_ ReqEngineTorqueLimit : 48|8@1+ (1,-125) [-125|125] "%" Vector__XXX
 SG_ ReqEngineSpeedLimit : 56|8@1+ (1,0) [0|250] "km/hr" Vector__XXX
 SG_ ReqEngineSpeed : 0|16@1+ (0.125,0) [0|8031.875] "rpm" Vector__XXX

BO_ 2566808318 GPM24: 8 Vector__XXX
 SG_ SecEngineMtdPTOSwitch : 30|2@1+ (1,0) [0|1] "" Vector__XXX
 SG_ SecClutchDpdtPTOSwitch : 24|2@1+ (1,0) [0|1] "" Vector__XXX
 SG_ FirstClutchDpdtPTOSwitch : 22|2@1+ (1,0) [0|1] "" Vector__XXX
 SG_ OperatingPanelActive : 18|2@1+ (1,0) [0|1] "" Vector__XXX
 SG_ RefusePackerStepSwitch : 16|2@1+ (1,0) [0|1] "" Vector__XXX
 SG_ EngineStopSwitch : 12|2@1+ (1,0) [0|1] "" Vector__XXX
 SG_ EngineStartSwitch : 10|2@1+ (1,0) [0|3] "" Vector__XXX
 SG_ StarterLockoutSwitch : 8|2@1+ (1,0) [0|1] "" Vector__XXX
 SG_ RqstedPercentClutchSlip : 0|8@1+ (0.4,0) [0|100] "%" Vector__XXX
 SG_ FirstEngineMtdPTOSwitch : 28|2@1+ (1,0) [0|1] "" Vector__XXX
 SG_ ClutchIndpdtPTOSwitch : 26|2@1+ (1,0) [0|1] "" Vector__XXX

BO_ 2566808830 GPM25: 8 Vector__XXX
 SG_ TrailerLeftSideMarkerLight : 20|2@1+ (1,0) [0|3] "" Vector__XXX
 SG_ TrailerLeftReversingLight : 16|2@1+ (1,0) [0|3] "" Vector__XXX
 SG_ TrailerLeftRearWidIndLight : 24|2@1+ (1,0) [0|3] "" Vector__XXX
 SG_ TrailerLeftRearRegPltLight : 32|2@1+ (1,0) [0|3] "" Vector__XXX
 SG_ TrailerLeftRearLight : 8|2@1+ (1,0) [0|3] "" Vector__XXX
 SG_ TrailerLeftRearFogLight : 12|2@1+ (1,0) [0|3] "" Vector__XXX
 SG_ TrailerLeftDirIndLight : 4|2@1+ (1,0) [0|3] "" Vector__XXX
 SG_ TrailerLeftCrnMarkerLight : 28|2@1+ (1,0) [0|3] "" Vector__XXX
 SG_ TrailerInteriorLight : 40|2@1+ (1,0) [0|3] "" Vector__XXX
 SG_ TrailerWorkLamp : 42|2@1+ (1,0) [0|3] "" Vector__XXX
 SG_ TrailerRotatingIdentLight : 38|2@1+ (1,0) [0|3] "" Vector__XXX
 SG_ TrailerRightStopLight : 2|2@1+ (1,0) [0|3] "" Vector__XXX
 SG_ TrailerRightSideMrkLight : 22|2@1+ (1,0) [0|3] "" Vector__XXX
 SG_ TrailerRightReversingLight : 18|2@1+ (1,0) [0|3] "" Vector__XXX
 SG_ TrailRightRearWidIndLight : 26|2@1+ (1,0) [0|3] "" Vector__XXX
 SG_ TrailerRightRearRegPltLight : 34|2@1+ (1,0) [0|3] "" Vector__XXX
 SG_ TrailerRightRearLight : 10|2@1+ (1,0) [0|3] "" Vector__XXX
 SG_ TrailerRightRearFogLight : 14|2@1+ (1,0) [0|3] "" Vector__XXX
 SG_ TrailerRightDirIndLight : 6|2@1+ (1,0) [0|3] "" Vector__XXX
 SG_ TrailerRightCrnMarkerLight : 30|2@1+ (1,0) [0|3] "" Vector__XXX
 SG_ TrailerRearWarningLight : 36|2@1+ (1,0) [0|3] "" Vector__XXX
 SG_ TrailerLeftStopLight : 0|2@1+ (1,0) [0|3] "" Vector__XXX

BO_ 2564554494 ISO15765_Funct: 8 Vector__XXX
 SG_ SN m2 : 0|4@1+ (1,0) [0|15] "" Vector__XXX
 SG_ SeparationTime m3 : 16|8@1+ (1,0) [0|255] "ms" Vector__XXX
 SG_ BlockSize m3 : 8|8@1+ (1,0) [0|255] "" Vector__XXX
 SG_ FlowStatus m3 : 0|4@1+ (1,0) [0|3] "" Vector__XXX
 SG_ FirstFrameDataLength m1 : 3|12@0+ (1,0) [0|4095] "Byte" Vector__XXX
 SG_ SingleFrameDataLength m0 : 0|4@1+ (1,0) [0|7] "Byte" Vector__XXX
 SG_ ProtocolCtrlInformation M : 4|4@1+ (1,0) [0|3] "" Vector__XXX

BO_ 2564488958 ISO15765_Phys: 8 Vector__XXX
 SG_ SN m2 : 0|4@1+ (1,0) [0|15] "" Vector__XXX
 SG_ SeparationTime m3 : 16|8@1+ (1,0) [0|255] "ms" Vector__XXX
 SG_ BlockSize m3 : 8|8@1+ (1,0) [0|255] "" Vector__XXX
 SG_ FlowStatus m3 : 0|4@1+ (1,0) [0|3] "" Vector__XXX
 SG_ FirstFrameDataLength m1 : 3|12@0+ (1,0) [0|4095] "Byte" Vector__XXX
 SG_ SingleFrameDataLength m0 : 0|4@1+ (1,0) [0|7] "Byte" Vector__XXX
 SG_ ProtocolCtrlInformation M : 4|4@1+ (1,0) [0|3] "" Vector__XXX

CM_ BO_ 2365473278 "The lighting command message has been defined as a global message from the tractor to all lighting controllers on the";
CM_ SG_ 2365473278 ImplementRearWorkLightCmd "Command to activate or de-activate implement rear work lights. (This is also the same as Reversing Lights for truck";
CM_ SG_ 2365473278 ImplementLeftForwardWorkLightCmd "Command to activate or de-activate the forward facing work lights toward the left end of the implement.";
CM_ SG_ 2365473278 ImplmentRightForwardWorkLightCmd "Command to activate or de-activate the forward facing work lights toward the right end of the implement.";
CM_ SG_ 2365473278 LightingDataRqCmd "Command to provide a response of the light state";
CM_ SG_ 2365473278 ImplementLeftFacingWorkLightCmd "Command to activate or de-activate work lights mounted on an implement to illuminate beyond left end of the implement.";
CM_ SG_ 2365473278 ImplementRightFacingWorkLightCmd "Command to activate or de-activate work lights mounted on an implement to illuminate beyond right end of the implement.";
CM_ SG_ 2365473278 ImplementOEMOption1LightCmd "Command to activate or de-activate an implement OEM option 1 light. This is provided to meet special needs on";
CM_ SG_ 2365473278 ImplementOEMOption2LightCmd "Command to activate or de-activate an implement OEM option 2 light. This is provided to meet special needs on";
CM_ SG_ 2365473278 TrctrFrntHghMountedWorkLightsCmd "Command to activate or de-activate the tractor front high mounted work lights.";
CM_ SG_ 2365473278 TrctrFrntLowMountedWorkLightsCmd "Command to activate or de-activate the tractor front low mounted work lights.";
CM_ SG_ 2365473278 TrctrSdeHighMountedWorkLightsCmd "Command to activate or de-activate the tractor side high mounted work lights.";
CM_ SG_ 2365473278 TrctrSideLowMountedWorkLightsCmd "Command to activate or de-activate the tractor side low mounted work lights.";
CM_ SG_ 2365473278 TrctrRarHighMountedWorkLightsCmd "Command to activate or de-activate the tractor rear high mounted work lights.";
CM_ SG_ 2365473278 TrctrRearLowMountedWorkLightsCmd "Command to activate or de-activate the tractor rear low mounted work lights.";
CM_ SG_ 2365473278 TrctrUndrsdeMountedWorkLightsCmd "Command to activate or de-activate the tractor underside mounted work lights.";
CM_ SG_ 2365473278 RearFogLightCmd "Command to activate or de-activate tractor or implement rear fog lights.";
CM_ SG_ 2365473278 TractorMarkerLightCmd "Command to activate or de-activate tractor and implement front position lights, rear red tail lights, side amber running";
CM_ SG_ 2365473278 ImplementMarkerLightCmd "Command to activate or de-activate implement front position lights, rear red tail lights, side amber running lights, license";
CM_ SG_ 2365473278 TractorClearanceLightCmd "Command to activate or de-activate the tractor high mounted clearance and center ID lights";
CM_ SG_ 2365473278 ImplementClearanceLightCmd "Command to activate or de-activate the implement high mounted clearance and lights.";
CM_ SG_ 2365473278 LeftStopLightCmd "Command to activate or de-activate the tractor and implement left stop lights";
CM_ SG_ 2365473278 RightStopLightCmd "Command to activate or de-activate the tractor and implement right stop light";
CM_ SG_ 2365473278 CenterStopLightCmd "Command to activate or de-activate the tractor and implement center stop light";
CM_ SG_ 2365473278 BackUpLightAndAlarmHornCmd "Command to activate or de-activate the back up lights and/ or associated alarm if required";
CM_ SG_ 2365473278 LeftTurnSignalLightsCmd "Command to activate or de-activate left turn signal lights on the tractor and all connected implements";
CM_ SG_ 2365473278 RightTurnSignalLightsCmd "Command to activate or de-activate right turn signal lights on the tractor and all connected implements";
CM_ SG_ 2365473278 RotatingBeaconLightCmd "Command to activate or de-activate slow moving vehicle indicator lights on tractor and/or implements. Activation of the";
CM_ SG_ 2365473278 TractorFrontFogLightsCmd "Command to activate or de-activate tractor front fog lights.";
CM_ SG_ 2365473278 HighBeamHeadLightCmd "Command to activate or de-activate the tractor high beam head light lamps.";
CM_ SG_ 2365473278 LowBeamHeadLightCmd "Command to activate or de-activate the tractor low beam head light lamps.";
CM_ SG_ 2365473278 AltBeamHeadLightCmd "Command to activate or de-activate the tractor alternate head lights (only low beam is available on alternate head lights).";
CM_ SG_ 2365473278 RunningLightCmd "Command to activate or de-activate the tractor or powered vehicle running lights. Usually only used for on road vehicles.";
CM_ SG_ 2365485822 LandLevelingSystemEnableStatus "Communicate the enable/disable status of the Land Leveling System.";
CM_ SG_ 2365485822 BladeCtrlModeRight "Indicate if the land leveling system's automatic control is active or inactive for the elevation sensor on the right side of the";
CM_ SG_ 2365485822 BladeCtrlModeLeft "Indicate if the land leveling system's automatic control is active or inactive for the elevation sensor on the left side of the";
CM_ SG_ 2365485822 BladeCtrlMode "Allows the user to select the type of blade control for the land leveling system.";
CM_ SG_ 2365485822 BladeDurationAndDirection "Used to indicate the duration and direction that the land leveling system blade moves.";
CM_ BO_ 2633926654 "Ignition Timing 6";
CM_ SG_ 2633926654 EngActualIgntTiming "The actual ignition timing at the current engine conditions. This parameter may or may not be equal to one of the desired";
CM_ SG_ 2633926654 EngDesiredIgntTiming3 "A programmable timing value specific to the engine’s application. Factors affecting this value include both fuel type and";
CM_ SG_ 2633926654 EngDesiredIgntTiming2 "A programmable timing value specific to the engine’s application. Factors affecting this value include both fuel type and";
CM_ SG_ 2633926654 EngDesiredIgntTiming1 "A programmable timing value specific to the engine’s application. Factors affecting this value include both fuel type and";
CM_ BO_ 2633926398 "Ignition Timing 5";
CM_ SG_ 2633926398 EngCyl20IgntTiming "The ignition timing of the cylinder.";
CM_ SG_ 2633926398 EngCyl19IgntTiming "The ignition timing of the cylinder.";
CM_ SG_ 2633926398 EngCyl18IgntTiming "The ignition timing of the cylinder.";
CM_ SG_ 2633926398 EngCyl17IgntTiming "The ignition timing of the cylinder.";
CM_ BO_ 2633926142 "Ignition Timing 4";
CM_ SG_ 2633926142 EngCyl16IgntTiming "The ignition timing of the cylinder.";
CM_ SG_ 2633926142 EngCyl15IgntTiming "The ignition timing of the cylinder.";
CM_ SG_ 2633926142 EngCyl14IgntTiming "The ignition timing of the cylinder.";
CM_ SG_ 2633926142 EngCyl13IgntTiming "The ignition timing of the cylinder.";
CM_ BO_ 2633925886 "Ignition Timing 3";
CM_ SG_ 2633925886 EngCyl12IgntTiming "The ignition timing of the cylinder.";
CM_ SG_ 2633925886 EngCyl11IgntTiming "The ignition timing of the cylinder.";
CM_ SG_ 2633925886 EngCyl10IgntTiming "The ignition timing of the cylinder.";
CM_ SG_ 2633925886 EngCyl9IgntTiming "The ignition timing of the cylinder.";
CM_ BO_ 2633925630 "Ignition Timing 2";
CM_ SG_ 2633925630 EngCyl8IgntTiming "The ignition timing of the cylinder.";
CM_ SG_ 2633925630 EngCyl7IgntTiming "The ignition timing of the cylinder.";
CM_ SG_ 2633925630 EngCyl6IgntTiming "The ignition timing of the cylinder.";
CM_ SG_ 2633925630 EngCyl5IgntTiming "The ignition timing of the cylinder.";
CM_ SG_ 2633925374 EngCyl4IgntTiming "The ignition timing of the cylinder.";
CM_ SG_ 2633925374 EngCyl3IgntTiming "The ignition timing of the cylinder.";
CM_ SG_ 2633925374 EngCyl2IgntTiming "The ignition timing of the cylinder.";
CM_ SG_ 2633925374 EngCyl1IgntTiming "The ignition timing of the cylinder.";
CM_ SG_ 2633927422 EngCyl20IgntTransSecondOutput "This parameter indicates the relative intensity of the secondary output voltage of the ignition transformer.";
CM_ SG_ 2633927422 EngCyl19IgntTransSecondOutput "This parameter indicates the relative intensity of the secondary output voltage of the ignition transformer.";
CM_ SG_ 2633927422 EngCyl18IgntTransSecondOutput "This parameter indicates the relative intensity of the secondary output voltage of the ignition transformer.";
CM_ SG_ 2633927422 EngCyl17IgntTransSecondOutput "This parameter indicates the relative intensity of the secondary output voltage of the ignition transformer.";
CM_ SG_ 2633927166 EngCyl16IgntTransSecondOutput "This parameter indicates the relative intensity of the secondary output voltage of the ignition transformer.";
CM_ SG_ 2633927166 EngCyl15IgntTransSecondOutput "This parameter indicates the relative intensity of the secondary output voltage of the ignition transformer.";
CM_ SG_ 2633927166 EngCyl14IgntTransSecondOutput "This parameter indicates the relative intensity of the secondary output voltage of the ignition transformer.";
CM_ SG_ 2633927166 EngCyl13IgntTransSecondOutput "This parameter indicates the relative intensity of the secondary output voltage of the ignition transformer.";
CM_ SG_ 2633927166 EngCyl12IgntTransSecondOutput "This parameter indicates the relative intensity of the secondary output voltage of the ignition transformer.";
CM_ SG_ 2633927166 EngCyl11IgntTransSecondOutput "This parameter indicates the relative intensity of the secondary output voltage of the ignition transformer.";
CM_ SG_ 2633927166 EngCyl10IgntTransSecondOutput "This parameter indicates the relative intensity of the secondary output voltage of the ignition transformer.";
CM_ SG_ 2633927166 EngCyl9IgntTransSecondOutput "This parameter indicates the relative intensity of the secondary output voltage of the ignition transformer.";
CM_ BO_ 2633926910 "Ignition Transformer Secondary Output 1";
CM_ SG_ 2633926910 EngCyl8IgntTransSecondOutput "This parameter indicates the relative intensity of the secondary output voltage of the ignition transformer.";
CM_ SG_ 2633926910 EngCyl7IgntTransSecondOutput "This parameter indicates the relative intensity of the secondary output voltage of the ignition transformer.";
CM_ SG_ 2633926910 EngCyl6IgntTransSecondOutput "This parameter indicates the relative intensity of the secondary output voltage of the ignition transformer.";
CM_ SG_ 2633926910 EngCyl5IgntTransSecondOutput "This parameter indicates the relative intensity of the secondary output voltage of the ignition transformer.";
CM_ SG_ 2633926910 EngCyl4IgntTransSecondOutput "This parameter indicates the relative intensity of the secondary output voltage of the ignition transformer.";
CM_ SG_ 2633926910 EngCyl3IgntTransSecondOutput "This parameter indicates the relative intensity of the secondary output voltage of the ignition transformer.";
CM_ SG_ 2633926910 EngCyl2IgntTransSecondOutput "This parameter indicates the relative intensity of the secondary output voltage of the ignition transformer.";
CM_ SG_ 2633926910 EngCyl1IgntTransSecondOutput "This parameter indicates the relative intensity of the secondary output voltage of the ignition transformer.";
CM_ BO_ 2566768894 "Operator Primary Intermediate Speed Control state";
CM_ SG_ 2566768894 EngOprtrPrmryIntrmdtSpdSlctState "13 preprogrammed intermediate speed control settings are available for the controlling ECM to select. If no speed setting";
CM_ BO_ 2566769406 "The Intermediate Speed Control is widely used in the Industrial application to control the engine to an intermediate speed";
CM_ SG_ 2566769406 EngOprtrPrmryIntrmdteSpeedSelect "Allows the operator to select one of 13 preprogrammed Intermediate Speed Control settings. If no speed setting is";
CM_ BO_ 2566839550 "Idle Operation";
CM_ SG_ 2566839550 EngTotalIdleHours "Accumulated time of operation of the engine while under idle conditions.";
CM_ SG_ 2566839550 EngTotalIdleFuelUsed "Accumulated amount of fuel used during vehicle operation while under idle conditions.";
CM_ BO_ 2633934334 "Intake Manifold Information 2";
CM_ SG_ 2633934334 EngIntakeManifold6Temp "Temperature of pre-combustion air found in intake manifold number 6 of engine air supply system.";
CM_ SG_ 2633934334 EngIntakeManifold5Temp "Temperature of pre-combustion air found in intake manifold number 5 of engine air supply system.";
CM_ SG_ 2633934334 EngIntakeManifold4Temp "Temperature of pre-combustion air found in intake manifold of engine air supply system.";
CM_ SG_ 2633934334 EngIntakeManifold3Temp "Temperature of pre-combustion air found in intake manifold of engine air supply system.";
CM_ SG_ 2633934334 EngIntakeManifold2Temp "Temperature of pre-combustion air found in intake manifold of engine air supply system.";
CM_ BO_ 2566825726 "Intake Manifold Information 1";
CM_ SG_ 2566825726 EngTurbo4BoostPress "Gage pressure of air measured downstream of the compressor discharge side of the turbocharger. See also SPN 102";
CM_ SG_ 2566825726 EngTurbo3BoostPress "Gage pressure of air measured downstream of the compressor discharge side of the turbocharger. See also SPN 102";
CM_ SG_ 2566825726 EngTurbo2BoostPress "Gage pressure of air measured downstream of the compressor discharge side of the turbocharger. See also SPN 102";
CM_ SG_ 2566825726 EngTurbo1BoostPress "Gage pressure of air measured downstream of the compressor discharge side of the turbocharger. See also SPN 102";
CM_ BO_ 2566770942 "Intake/Exhaust Conditions 2 is a second PGN conveying this type of engine information. Also see PGN 65270.";
CM_ SG_ 2566770942 EngIntakeManifold2AbsPress "The absolute pressure measurement of the air intake manifold for bank 2 or the second air intake manifold. If there are";
CM_ SG_ 2566770942 EngIntakeManifold1AbsPress "The absolute pressure measurement of the air intake manifold. If there are multiple air pressure sensors in the intakeThe absolute pressure measurement of the air intake manifold. If there are multiple air pressure sensors in the intake";
CM_ SG_ 2566770942 EngIntakeManifold2Press "The gage pressure measurement of the air intake manifold for bank #2 or the second air intake manifold. If there are";
CM_ SG_ 2566770942 EngAirFilter4DiffPress "Change in engine air system pressure, measured across the fourth air filter, due to the filter and any accumulation of solid";
CM_ SG_ 2566770942 EngAirFilter3DiffPress "Change in engine air system pressure, measured across the third air filter, due to the filter and any accumulation of solid";
CM_ SG_ 2566770942 EngAirFilter2DiffPress "Change in engine air system pressure, measured across the second air filter, due to the filter and any accumulation of";
CM_ SG_ 2566846206 EngCoolantFilterDiffPress "Change in coolant pressure, measured across the filter, due to the filter and any accumulation of solid or semisolid matter";
CM_ SG_ 2566846206 EngExhaustGasTemp "Temperature of combustion byproducts leaving the engine. See SPNs 2433 and 2434 for engines with more than one";
CM_ SG_ 2566846206 EngAirFilter1DiffPress "Change in engine air system pressure, measured across the filter, due to the filter and any accumulation of solid foreign";
CM_ SG_ 2566846206 EngIntakeManifold1Temp "Temperature of pre-combustion air found in intake manifold of engine air supply system.";
CM_ SG_ 2566846206 EngIntakeManifold1Press "The gage pressure measurement of the air intake manifold. If there are multiple air pressure sensors in the intake stream,";
CM_ SG_ 2566846206 EngDslPrtculateFilterIntakePress "Exhaust back pressure as a result of particle accumulation on filter media placed in the exhaust stream. See SPN 3609";
CM_ SG_ 2566846206 EngAirIntakePress "Absolute air pressure at input port to intake manifold or air box.";
CM_ SG_ 2566811134 CabHeatingZone "Parameter indicating whether the cab zone is being heated.";
CM_ SG_ 2566811134 EngHeatingZone "Parameter indicating whether the engine zone is being heated.";
CM_ SG_ 2566811134 CabVentilation "Indicates whether the cab is being ventilated or not.";
CM_ SG_ 2566811134 AuxHeaterWaterPumpStatus "Parameter indicating whether the auxiliary heater water pump is running";
CM_ SG_ 2566811134 AuxHeaterMode "State of the auxiliary heater";
CM_ SG_ 2566811134 AuxHeaterOutputPowerPercent "Current auxiliary heater output power, relative to the auxiliary heater maximum output power.";
CM_ SG_ 2566811134 AuxHeaterInputAirTemp "Temperature of the input air in an auxiliary heater system.";
CM_ SG_ 2566811134 AuxHeaterOutputCoolantTemp "Temperature of the auxiliary heater output coolant (I.e. water in a water heater system.)";
CM_ SG_ 2298375934 RearAxleRightWheelSpeed "High resolution measurement of the speed of the right wheel on the rear axle.";
CM_ SG_ 2298375934 RearAxleLeftWheelSpeed "High resolution measurement of the speed of the left wheel on the rear axle.";
CM_ SG_ 2298375934 FrontAxleRightWheelSpeed "High resolution measurement of the speed of the right wheel on the front axle.";
CM_ SG_ 2298375934 FrontAxleLeftWheelSpeed "High resolution measurement of the speed of the left wheel on the front axle.";
CM_ BO_ 2565867774 "Information to be used for a hydraulic pressure governing control system";
CM_ SG_ 2565867774 FireApparatusPumpEngagement "The measured status of the pump used to provide water in fire fighting apparatus for distribution of water through water";
CM_ SG_ 2565867774 EngHydPressGovernorSwitch "Switch that sets the mode of hydraulic governor";
CM_ SG_ 2565867774 EngHydPressGovernorModeIndicator "Mode for governor operation is hydraulic pressure control.";
CM_ SG_ 2565867774 HydPress "Hydraulic pressure measured at the output of the hydraulic pump.";
CM_ SG_ 2566841854 EngTotalRevolutions "Accumulated number of revolutions of engine crankshaft during its operation.";
CM_ SG_ 2566841854 EngTotalHoursOfOperation "Accumulated time of operation of engine.";
CM_ BO_ 2365449982 "Used for information on a hydraulic brake system";
CM_ SG_ 2365449982 HydBrakeFluidLevelSwitch "Signal which indicates whether the hydraulic fluid level in the reservoir(s) is sufficient.";
CM_ SG_ 2365449982 HydBrakeSystemAudibleWarningCmd "Signal which commands an audible warning by the hydraulic braking system.";
CM_ SG_ 2365449982 HydBrakePressSupplyStateCircuit2 "Signal which indicates whether the hydraulic brake pressure supply of circuit 2 is reliable; that is, able to support";
CM_ SG_ 2365449982 HydBrakePressSupplyStateCircuit1 "Signal which indicates whether the hydraulic brake pressure supply of circuit 1 is reliable; that is, able to support";
CM_ SG_ 2365449982 HydBrkePressWarningStateCircuit2 "Signal which indicates whether the hydraulic brake pressure of circuit 2 is below the warning level";
CM_ SG_ 2365449982 HydBrkePressWarningStateCircuit1 "Signal which indicates whether the hydraulic brake pressure of circuit 1 is below the warning level";
CM_ SG_ 2365449982 HydBrakePressCircuit2 "Gage hydraulic pressure in circuit 2 of the hydraulic brake system";
CM_ SG_ 2365449982 HydBrakePressCircuit1 "Gage hydraulic pressure in circuit 1 of the hydraulic brake system";
CM_ SG_ 2633939198 TripDriveFuelEconomy "Trip drive fuel economy is equal to the distance traveled by vehicle in the drive state (engine speed greater than zero,";
CM_ SG_ 2633939198 TripCruiseFuelUsed "Total fuel consumed while the engine is in the cruise hold state since the last trip reset. If both cruise control and VSL";
CM_ SG_ 2633939198 TripVehicleIdleFuelUsed "Total fuel consumed while neither the PTO or remote PTO governors are active, the engine speed is greater than zero,";
CM_ SG_ 2633939198 TripPTOGovernorNonmovingFuelUsed "Total fuel consumed while the PTO or remote PTO governors are in the hold state, the engine speed is greater than zero,";
CM_ SG_ 2633939198 TripPTOGovernorMovingFuelUsed "Total fuel consumed while the PTO or remote PTO governors are in the hold state, the engine speed is greater than zero,";
CM_ SG_ 2633939198 TripDriveFuelUsed "Total fuel consumed while the engine speed is greater than zero, vehicle speed is greater than or equal to 2 km/h, and";
CM_ SG_ 2633927678 EngFuelValve1OutletAbsPress "Absolute Pressure of gas on outlet side of the first or only fuel system control valve. See SPN 3469 for the second fuel";
CM_ SG_ 2633927678 EngAirToFuelDiffPress "The differential pressure between the gaseous fuel and the air intake manifold.";
CM_ SG_ 2633927678 EngFuelValveDiffPress "The differential pressure between the intake and the outlet of a gaseous fuel valve.";
CM_ SG_ 2633927678 EngFuelValve1IntakeAbsPress "The absolute pressure of gas on the intake side of the first system control valve. See SPN 3466 for Engine Fuel Valve 2.";
CM_ BO_ 2633925118 "Gaseous fuel information 2";
CM_ SG_ 2633925118 EngRequestedFuelValve2Pos "The requested position of a gaseous fuel valve 2 that is metering the fuel flow to the engine, as requested by the Engine";
CM_ SG_ 2633925118 EngRequestedFuelValve1Pos "The requested position of a gaseous fuel valve 1 that is metering the fuel flow to the engine.";
CM_ SG_ 2633925118 EngFuelValve2Pos "The position of a gaseous fuel valve that is metering the fuel flow to the engine. 0% indicates no fuel flow through valve";
CM_ SG_ 2633925118 EngFuelValve1Pos "The position of a gaseous fuel valve that is metering the fuel flow to the engine. 0% indicates no fuel flow through valve";
CM_ SG_ 2633925118 EngFuelFlowRate2 "The rate at which the fuel is flowing through a fuel valve.";
CM_ SG_ 2633925118 EngFuelFlowRate1 "The rate at which the fuel is flowing through a fuel valve.";
CM_ SG_ 2633937662 EngFuelSpecificGravity "This parameter conveys the specific gravity of the gaseous fuel being used by the engine. The specific gravity of the fuel";
CM_ SG_ 2633937662 TripAverageFuelRate "Average fuel rate, equal to trip fuel divided by trip time while the engine speed is above zero, since the last trip reset. This";
CM_ SG_ 2633937662 TotalEngPTOGovernorFuelUsed "Total fuel used while the PTO or remote PTO governors are in the hold state and engine speed is above zero, over the";
CM_ SG_ 2566804990 SpecificHeatRatio "The specific heat ratio of the fuel.";
CM_ SG_ 2633936894 TotalFuelUsed "Total fuel consumed (trip drive fuel + trip PTO governor moving fuel + trip PTO governor non-moving fuel + trip idle fuel)";
CM_ SG_ 2633936894 TripFuel "Total fuel consumed (trip drive fuel + trip PTO governor moving fuel + trip PTO governor non-moving fuel + trip idle fuel)";
CM_ BO_ 2566757630 "Sensor Electrical Power #2";
CM_ SG_ 2566757630 SensorSupplyVoltage6 "Sensor ECU supply voltage 6";
CM_ SG_ 2566757630 SensorSupplyVoltage5 "Sensor ECU supply voltage 5";
CM_ SG_ 2566757630 SensorSupplyVoltage8 "Sensor ECU supply voltage 8";
CM_ SG_ 2566757630 SensorSupplyVoltage7 "Sensor ECU supply voltage 7";
CM_ BO_ 2566757886 "Sensor Electrical Power #1";
CM_ SG_ 2566757886 SensorSupplyVoltage4 "Sensor ECU supply voltage 4";
CM_ SG_ 2566757886 SensorSupplyVoltage3 "Sensor ECU supply voltage 3";
CM_ SG_ 2566757886 SensorSupplyVoltage2 "Sensor ECU supply voltage 2";
CM_ SG_ 2566757886 SensorSupplyVoltage1 "Sensor ECU supply voltage 1";
CM_ BO_ 2566759678 "Information relating to the request for engagement, consent for engagement, and status of engagement of various";
CM_ SG_ 2566759678 AtLeastOnePTOEngaged "Indicates that at least one PTO is engaged";
CM_ SG_ 2566759678 EnggmntSttsPTOEngAccessoryDrive2 "Engagement status of the PTO engine accessory drive 2";
CM_ SG_ 2566759678 EnggmntSttsPTOEngAccessoryDrive1 "Engagement status of the PTO engine accessory drive 1";
CM_ SG_ 2566759678 EngagementStatusPTOEngFlywheel "Engagement status of the PTO Engine Flywheel";
CM_ SG_ 2566759678 EnggmntStatusTransInputShaftPTO1 "Reports if this specific PTO drive is engaged. This parameter should be broadcast only by the controller(s) receiving";
CM_ SG_ 2566759678 EnggmntStatusTransInputShaftPTO2 "Reports if this specific PTO drive is engaged. This parameter should be broadcast only by the controller(s) receiving";
CM_ SG_ 2566759678 EnggmntStatusTransOutputShaftPTO "Reports if this specific PTO drive is engaged. This parameter should be broadcast only by the controller(s) receiving";
CM_ SG_ 2566759678 EnggmntSttsTrnsfrCsOtputShaftPTO "Reports if this specific PTO drive is engaged. This parameter should be broadcast only by the controller(s) receiving";
CM_ SG_ 2566759678 EnggmntCnsntPTOEngAccssoryDrive2 "Engagement Consent status for the PTO engine accessory drive 2";
CM_ SG_ 2566759678 EnggmntCnsntPTOEngAccssoryDrive1 "Engagement consent status for the PTO engine accessory drive 1";
CM_ SG_ 2566759678 EngagementConsentPTOEngFlywheel "Engagement Consent status for the PTO Engine Flywheel";
CM_ SG_ 2566759678 EnggmntCnsentTransInputShaftPTO1 "Status of the transmission controller’s consent to engage the first or sole PTO drive mounted on the transmission case.";
CM_ SG_ 2566759678 EnggmntCnsentTransInputShaftPTO2 "Status of the transmission controller’s consent to engage the second PTO drive mounted on the transmission case. The";
CM_ SG_ 2566759678 EnggmntCnsentTransOutputShaftPTO "Status of the transmission controller’s consent to engage the PTO drive connected to the transmission output shaft. The";
CM_ SG_ 2566759678 EnggmntCnsntTrnsfrCsOtptShaftPTO "Status of the transmission controller’s consent to engage the PTO drive connected to the transfer case output shaft. The";
CM_ SG_ 2566759678 EnbleSwitchPTOEngAccessoryDrive2 "Status of the PTO engine accessory drive 2 enable switch";
CM_ SG_ 2566759678 EnbleSwitchPTOEngAccessoryDrive1 "Status of the PTO engine accessory drive 1 enable switch";
CM_ SG_ 2566759678 EnableSwitchPTOEngFlywheel "Status of the PTO Engine Flywheel enable switch";
CM_ SG_ 2566759678 EnableSwitchTransInputShaftPTO1 "Status of the operator’s switch or other input which indicates the desire for engaging the first PTO drive mounted on the";
CM_ SG_ 2566759678 EnableSwitchTransInputShaftPTO2 "Status of the operator’s switch or other input which indicates the desire for engaging the second PTO drive mounted on";
CM_ SG_ 2566759678 EnableSwitchTransOutputShaftPTO "Status of the operator’s switch or other input which indicates the desire for engaging the PTO drive mounted on the";
CM_ SG_ 2566759678 EnblSwtchTrnsfrCseOutputShaftPTO "Status of the operator’s switch or other input which indicates the desire for engaging the PTO drive mounted on the output";
CM_ BO_ 2432541438 "Fuel Information 3 (Gaseous)";
CM_ SG_ 2432541438 EngFuelValve2OutletAbsPress "Absolute pressure of gas on outlet side of the second fuel system control valve. See SPN 2980 for the first or only fuel";
CM_ SG_ 2432541438 EngFuelTemp2 "Temperature 2 of fuel (or gas). See SPN 174 for fuel temperature 1.";
CM_ SG_ 2432541438 EngGas2MassFlowRate "Gas mass flow rate delivered to an engine through its second fuel control system, using standard convention for";
CM_ SG_ 2432541438 EngFuelValve2IntakeAbsPress "Absolute pressure of gas on intake side of the second fuel system control valve, using standard convention for";
CM_ BO_ 2566761214 "4th PGN which identifies parameters that are either measuring various pressures within the engine or identifying engine";
CM_ SG_ 2566761214 EngCentrifugalOilFilterSpeed "The speed of a rotating (centrifugal) engine oil filter.";
CM_ SG_ 2566761214 EngCoolantPumpDiffPress "The differential pressure measured across the input and output of the engine coolant pump.";
CM_ SG_ 2566761214 EngChargeAirCooler2IntakePress "Pressure of air at intake to 2nd charge air cooler, from multiple first stage turbochargers being cooled and feeding multiple";
CM_ SG_ 2566761214 EngChargeAirCooler1IntakePress "Pressure of air at intake to 1st or only charge air cooler, from multiple first stage turbochargers being cooled and feeding";
CM_ SG_ 2566761214 EngIntercoolerCoolantLevel "Ratio of volume of liquid found in an engine intercooler cooling system to total engine intercooler cooling system volume.";
CM_ SG_ 2566761214 EngChargeAirCoolerOutletPress "Measures pressure of air at outlet from charge air cooler";
CM_ SG_ 2566761214 EngAftercoolerCoolantLevel "Ratio of aftercooler coolant system volume of liquid to total cooling system volume. The engine aftercooler coolant level";
CM_ BO_ 2432541694 "Electronic Engine Controller 6";
CM_ SG_ 2432541694 EngVriableGeometryTurboActuator1 "Actuator that controls the variable geometry turbocharger geometry.The control command to the actuator, normalized to";
CM_ SG_ 2432541694 EngTrbCmprssrBypssActtr1TmpSttus "Used to identify the status of the Engine Turbocharger Compresssor Bypass Actuator 1 drive circuitry temperature.";
CM_ SG_ 2432541694 EngTrbCmprssrBypssActtr1PrlmnryF "Used to identify the appplicable J1939-73 FMI detected in the Engine Turbocharger Compressor Bypass Actuator 1 by";
CM_ SG_ 2432541694 EngTrbCmprssorBypassActuator2Cmd "The command to a compressor bypass actuator 2, normalized to percent, where 0% nominally represents fully closed and";
CM_ SG_ 2432541694 EngTrbCmprssorBypassActuator1Pos "Measures the position of the turbocharger compressor bypass actuator, where 0% represents bypass fully closed and";
CM_ SG_ 2432541694 EngTrbCmprssorBypassActuator1Cmd "The command to a compressor bypass actuator, normalized to percent, where 0% nominally represents fully closed and";
CM_ SG_ 2432541694 EngDsrdTrbCmprssrBypssActtor1Pos "The requested position of the Engine Turbocharger Compressor Bypass actuator by the engine ECM, where 0%";
CM_ BO_ 2566759934 "Used for door information.";
CM_ SG_ 2566759934 EnableStatusOfDoor10 "Enable status of bus door 10. Enabled means the bus doors are able to be automatically opened or closed.";
CM_ SG_ 2566759934 OpenStatusOfDoor10 "Open status of bus door 10";
CM_ SG_ 2566759934 LockStatusOfDoor10 "Lock status of bus door 10";
CM_ SG_ 2566759934 EnableStatusOfDoor9 "Enable status of bus door 9. Enabled means the bus doors are able to be automatically opened or closed.";
CM_ SG_ 2566759934 OpenStatusOfDoor9 "Open status of bus door 9";
CM_ SG_ 2566759934 LockStatusOfDoor9 "Lock status of bus door 9";
CM_ SG_ 2566759934 EnableStatusOfDoor8 "Enable status of bus door 8. Enabled means the bus doors are able to be automatically opened or closed.";
CM_ SG_ 2566759934 OpenStatusOfDoor8 "Open status of bus door 8";
CM_ SG_ 2566759934 LockStatusOfDoor8 "Lock status of bus door 8";
CM_ SG_ 2566759934 EnableStatusOfDoor7 "Enable status of bus door 7. Enabled means the bus doors are able to be automatically opened or closed.";
CM_ SG_ 2566759934 OpenStatusOfDoor7 "Open status of bus door 7";
CM_ SG_ 2566759934 LockStatusOfDoor7 "Lock status of bus door 7";
CM_ SG_ 2566759934 EnableStatusOfDoor6 "Enable status of bus door 6. Enabled means the bus doors are able to be automatically opened or closed.";
CM_ SG_ 2566759934 OpenStatusOfDoor6 "Open status of bus door 6";
CM_ SG_ 2566759934 LockStatusOfDoor6 "Lock status of bus door 6";
CM_ SG_ 2566759934 EnableStatusOfDoor5 "Enable status of bus door 5. Enabled means the bus doors are able to be automatically opened or closed.";
CM_ SG_ 2566759934 OpenStatusOfDoor5 "Open status of bus door 5";
CM_ SG_ 2566759934 LockStatusOfDoor5 "Lock status of bus door 5";
CM_ SG_ 2566759934 EnableStatusOfDoor4 "Enable status of bus door 4. Enabled means the bus doors are able to be automatically opened or closed.";
CM_ SG_ 2566759934 OpenStatusOfDoor4 "Open status of bus door 4";
CM_ SG_ 2566759934 LockStatusOfDoor4 "Lock status of bus door 4";
CM_ SG_ 2566759934 EnableStatusOfDoor3 "Enable status of bus door 3. Enabled means the bus doors are able to be automatically opened or closed.";
CM_ SG_ 2566759934 OpenStatusOfDoor3 "Open status of bus door 3";
CM_ SG_ 2566759934 LockStatusOfDoor3 "Lock status of bus door 3";
CM_ SG_ 2566759934 EnableStatusOfDoor2 "Enable status of bus door 2. Enabled means the bus doors are able to be automatically opened or closed.";
CM_ SG_ 2566759934 OpenStatusOfDoor2 "Open status of bus door 2";
CM_ SG_ 2566759934 LockStatusOfDoor2 "Lock status of bus door 2";
CM_ SG_ 2566759934 EnableStatusOfDoor1 "Enable status of bus door 1. Enabled means the bus doors are able to be automatically opened or closed.";
CM_ SG_ 2566759934 OpenStatusOfDoor1 "Open status of bus door 1";
CM_ SG_ 2566759934 LockStatusOfDoor1 "Lock status of bus door 1";
CM_ BO_ 2566757374 "Aftertreatment 1 SCR Reagent Information";
CM_ SG_ 2566757374 Aftrtrtmnt1SCRCtlystRgntTmp2Prlm "Used to identify the applicable J1939-73 FMI that applies to the most significant failure of the catalyst temperature sensor.";
CM_ SG_ 2566757374 Aftrtrtmnt1SCRCtlystRgntPrprtsPr "Used to identify the applicable J1939-73 FMI that applies to the most significant failure of the catalyst reagent properties";
CM_ SG_ 2566757374 Aftrtrtmnt1SCRCtlystRgntCndctvty "A measure of the conductivity of the reagent or fluid at the sensor. The conductivity is an indication of the reagent's";
CM_ SG_ 2566757374 Aftrtrtmnt1SCRCtlystRgntCncntrtn "A measure of the concentration of urea in water. Zero percent means that the tank contains no urea. A 32.5% value";
CM_ SG_ 2566757374 Aftrtrtmnt1SCRCtalystReagentType "This parameter indicates what reagent is in the tank. A value of 0011 indicates uncontaminated Diesel Exhaust Fluid.";
CM_ SG_ 2566757374 Aftrtrtmnt1SCRCtlystReagentTemp2 "Temperature of the catalyst reagent at the device measuring reagent quality";
CM_ BO_ 2364546302 "Requested Generator Average Basic AC Quantities";
CM_ SG_ 2364546302 RqdGnrtrAvrgLneLineACRMSVoltage "The requested average AC RMS voltage to be delivered by the generator.";
CM_ BO_ 2431654654 "Used to control networked electronic throttle control actuator and/or fuel control actuator valves. Otherwise, this PGN can";
CM_ SG_ 2431654654 EngFuelActuator2CtrlCmd "The control command to fuel actuator 2, normalized to percent, where 0% represents fully closed and 100% represents";
CM_ SG_ 2431654654 EngFuelActuator1CtrlCmd "The control command to fuel actuator 1, normalized to percent, where 0% represents fully closed and 100% represents";
CM_ SG_ 2431654654 EngThrottleActuator2CtrlCmd "The control command to throttle actuator 2, normalized to percent, where 0% represents fully closed and 100%";
CM_ SG_ 2431654654 EngThrottleActuator1CtrlCmd "The control command to throttle actuator 1, normalized to percent, where 0% represents fully closed and 100%";
CM_ BO_ 2364545534 "Used to send the SPNs containing information relating to the level of knock for 8 cylinders. When knock is detected on";
CM_ SG_ 2364545534 EngCyl24KnockLevel "Used to indicate the level of knock for engine cylinder 24. The level of knock is reported using a relative scale where 0%";
CM_ SG_ 2364545534 EngCyl23KnockLevel "Used to indicate the level of knock for engine cylinder 23. The level of knock is reported using a relative scale where 0%";
CM_ SG_ 2364545534 EngCyl22KnockLevel "Used to indicate the level of knock for engine cylinder 22. The level of knock is reported using a relative scale where 0%";
CM_ SG_ 2364545534 EngCyl21KnockLevel "Used to indicate the level of knock for engine cylinder 21. The level of knock is reported using a relative scale where 0%";
CM_ SG_ 2364545534 EngCyl20KnockLevel "Used to indicate the level of knock for engine cylinder 20. The level of knock is reported using a relative scale where 0%";
CM_ SG_ 2364545534 EngCyl19KnockLevel "Used to indicate the level of knock for engine cylinder 19. The level of knock is reported using a relative scale where 0%";
CM_ SG_ 2364545534 EngCyl18KnockLevel "Used to indicate the level of knock for engine cylinder 18. The level of knock is reported using a relative scale where 0%";
CM_ SG_ 2364545534 EngCyl17KnockLevel "Used to indicate the level of knock for engine cylinder 17. The level of knock is reported using a relative scale where 0%";
CM_ BO_ 2364545278 "Used to send the SPNs containing information relating to the level of knock for 8 cylinders. When knock is detected on";
CM_ SG_ 2364545278 EngCyl16KnockLevel "Used to indicate the level of knock for engine cylinder 16. The level of knock is reported using a relative scale where 0%";
CM_ SG_ 2364545278 EngCyl15KnockLevel "Used to indicate the level of knock for engine cylinder 15. The level of knock is reported using a relative scale where 0%";
CM_ SG_ 2364545278 EngCyl14KnockLevel "Used to indicate the level of knock for engine cylinder 14. The level of knock is reported using a relative scale where 0%";
CM_ SG_ 2364545278 EngCyl13KnockLevel "Used to indicate the level of knock for engine cylinder 13. The level of knock is reported using a relative scale where 0%";
CM_ SG_ 2364545278 EngCyl12KnockLevel "Used to indicate the level of knock for engine cylinder 12. The level of knock is reported using a relative scale where 0%";
CM_ SG_ 2364545278 EngCyl11KnockLevel "Used to indicate the level of knock for engine cylinder 11. The level of knock is reported using a relative scale where 0%";
CM_ SG_ 2364545278 EngCyl10KnockLevel "Used to indicate the level of knock for engine cylinder 10. The level of knock is reported using a relative scale where 0%";
CM_ SG_ 2364545278 EngCyl9KnockLevel "Used to indicate the level of knock for engine cylinder 9. The level of knock is reported using a relative scale where 0% is";
CM_ BO_ 2364545022 "Used to send the SPNs containing information relating to the level of knock for 8 cylinders. When knock is detected on";
CM_ SG_ 2364545022 EngCyl8KnockLevel "Used to indicate the level of knock for engine cylinder 8. The level of knock is reported using a relative scale where 0% is";
CM_ SG_ 2364545022 EngCyl7KnockLevel "Used to indicate the level of knock for engine cylinder 7. The level of knock is reported using a relative scale where 0% is";
CM_ SG_ 2364545022 EngCyl6KnockLevel "Used to indicate the level of knock for engine cylinder 6. The level of knock is reported using a relative scale where 0% is";
CM_ SG_ 2364545022 EngCyl5KnockLevel "Used to indicate the level of knock for engine cylinder 5. The level of knock is reported using a relative scale where 0% is";
CM_ SG_ 2364545022 EngCyl4KnockLevel "Used to indicate the level of knock for engine cylinder 4. The level of knock is reported using a relative scale where 0% is";
CM_ SG_ 2364545022 EngCyl3KnockLevel "Used to indicate the level of knock for engine cylinder 3. The level of knock is reported using a relative scale where 0% is";
CM_ SG_ 2364545022 EngCyl2KnockLevel "Used to indicate the level of knock for engine cylinder 2. The level of knock is reported using a relative scale where 0% is";
CM_ SG_ 2364545022 EngCyl1KnockLevel "Used to indicate the level of knock for engine cylinder 1. The level of knock is reported using a relative scale where 0% is";
CM_ BO_ 2364544766 "Used to send the SPNs containing information relating to the state of combustion for 24 cylinders. When there is no";
CM_ SG_ 2364544766 EngCyl24CombustionStatus "This parameter is used to indicate state of combustion in engine cylinder #24";
CM_ SG_ 2364544766 EngCyl23CombustionStatus "This parameter is used to indicate state of combustion in engine cylinder #23";
CM_ SG_ 2364544766 EngCyl22CombustionStatus "This parameter is used to indicate state of combustion in engine cylinder #22";
CM_ SG_ 2364544766 EngCyl21CombustionStatus "This parameter is used to indicate state of combustion in engine cylinder #21";
CM_ SG_ 2364544766 EngCyl20CombustionStatus "This parameter is used to indicate state of combustion in engine cylinder #20";
CM_ SG_ 2364544766 EngCyl19CombustionStatus "This parameter is used to indicate state of combustion in engine cylinder #19";
CM_ SG_ 2364544766 EngCyl18CombustionStatus "This parameter is used to indicate state of combustion in engine cylinder #18";
CM_ SG_ 2364544766 EngCyl17CombustionStatus "This parameter is used to indicate state of combustion in engine cylinder #17";
CM_ SG_ 2364544766 EngCyl16CombustionStatus "This parameter is used to indicate state of combustion in engine cylinder #16";
CM_ SG_ 2364544766 EngCyl15CombustionStatus "This parameter is used to indicate state of combustion in engine cylinder #15";
CM_ SG_ 2364544766 EngCyl14CombustionStatus "This parameter is used to indicate state of combustion in engine cylinder #14";
CM_ SG_ 2364544766 EngCyl13CombustionStatus "This parameter is used to indicate state of combustion in engine cylinder #13";
CM_ SG_ 2364544766 EngCyl12CombustionStatus "This parameter is used to indicate state of combustion in engine cylinder #12";
CM_ SG_ 2364544766 EngCyl11CombustionStatus "This parameter is used to indicate state of combustion in engine cylinder #11";
CM_ SG_ 2364544766 EngCyl10CombustionStatus "This parameter is used to indicate state of combustion in engine cylinder #10";
CM_ SG_ 2364544766 EngCyl9CombustionStatus "This parameter is used to indicate state of combustion in engine cylinder #9";
CM_ SG_ 2364544766 EngCyl8CombustionStatus "This parameter is used to indicate state of combustion in engine cylinder #8";
CM_ SG_ 2364544766 EngCyl7CombustionStatus "This parameter is used to indicate state of combustion in engine cylinder #7";
CM_ SG_ 2364544766 EngCyl6CombustionStatus "This parameter is used to indicate state of combustion in engine cylinder #6";
CM_ SG_ 2364544766 EngCyl5CombustionStatus "This parameter is used to indicate state of combustion in engine cylinder #5";
CM_ SG_ 2364544766 EngCyl4CombustionStatus "This parameter is used to indicate state of combustion in engine cylinder #4";
CM_ SG_ 2364544766 EngCyl3CombustionStatus "This parameter is used to indicate state of combustion in engine cylinder #3";
CM_ SG_ 2364544766 EngCyl2CombustionStatus "This parameter is used to indicate state of combustion in engine cylinder #2";
CM_ SG_ 2364544766 EngCyl1CombustionStatus "This parameter is used to indicate state of combustion in engine cylinder #1";
CM_ BO_ 2364544510 "Requested Generator Total AC Reactive Power";
CM_ SG_ 2364544510 RqGenOverallPowerFactorLagging "The requested lead/lag status for the generator average AC power factor";
CM_ SG_ 2364544510 RqGeneratorOverallPowerFactor "The requested average power factor of the generator.";
CM_ SG_ 2364544510 RqGeneratorTotalACReactivePower "The total reactive power requested to be delivered by the generator";
CM_ BO_ 2364544254 "A measurement of the machine's relative blade height and a rotational angle measurement of the machine blade yaw";
CM_ SG_ 2364544254 BladeRotationAngleFigureOfMerit "Figure of merit for blade rotation measurement.";
CM_ SG_ 2364544254 RelativeBladeHeightFigureOfMerit "Figure of merit for blade height measurement.";
CM_ SG_ 2364544254 RltvBldHghtAndBldRttnAnglMsrmntL "The estimated measurement latency of the measurement.";
CM_ SG_ 2364544254 BladeRotationAngle "The blade rotation angle measurement around the yaw (z-axis).";
CM_ SG_ 2364544254 RelativeBladeHeight "The measured vertical distance from a fixed location on the machine blade to a ground-based reference (i.e. relative";
CM_ BO_ 2349006590 "ISO 11992: Towing vehicle message, electronic brake system #1/1";
CM_ SG_ 2349006590 RetarderDemandValue "The demanded value of the retarder on the towed vehicle(s) as a percentage of the absolute peak torque of retarder.";
CM_ SG_ 2349006590 ParkBrakeDemandValue "The requested brake pressure value of the parking brake as a percentage of maximum.";
CM_ SG_ 2349006590 ServiceBrakeDemandValue "The requested brake pressure value of the service brake demanded by the driver.";
CM_ SG_ 2349006590 VehicleType "Information to identify a dolly axle within the road train.";
CM_ SG_ 2349006590 BrakeLightSwitch "Signal which indicates that the brake pedal is being pressed.";
CM_ SG_ 2349006590 ASREngineControlActive "Signal which indicates that ASR engine control is active/passive.";
CM_ SG_ 2349006590 ASRBreakControlActive "Signal which indicates that ASR brake control is active/passive.";
CM_ SG_ 2349006590 VehicleRetarderCtrlActive "This signal indicates the active/passive state in all cases when the installed retarder is applied by the driver’s demand or by other systems (brakes).";
CM_ SG_ 2349006590 VehicleABSActive "Signal indicating the ABS is active/passive.";
CM_ BO_ 2566834686 "ISO 11992: Towing vehicle message, electronic brake system #1/2";
CM_ SG_ 2566834686 RoadCurvature "Estimated value of the current road curvature for use by the adaptive cruise control system. Positive values are used for";
CM_ SG_ 2566834686 PneumaticControlLine "Signal which indicates that the towing vehicle has a pneumatic control line for the towed vehicle service braking system";
CM_ SG_ 2566834686 ABSOffroadRequest "Request to activate the ABS off-road function. The switch signal is independent of an actual ABS control situation.";
CM_ SG_ 2566834686 TwoElCircuitsBrakeDemand "Signal which indicates that the service brake demand value sent by the towing vehicle can be generated by one or two independent electrical braking circuit(s).";
CM_ SG_ 2566834686 VehicleRetarderCtrlActive "This signal indicates the active/passive state in all cases when the installed retarder is applied by the driver’s demand or by other systems (brakes).";
CM_ BO_ 2550398718 "ISO 11992: Towed vehicle message, electronic brake system #2/1";
CM_ SG_ 2550398718 WheelSpeedDiffMainAxle "Difference between the wheel speed at the right side and and the left side of the main axle.";
CM_ SG_ 2550398718 ActualRetarderPercTorque "Actual torque of the retarder as negative percentage of maximum.";
CM_ SG_ 2550398718 Wheel_BasedVehicleSpeed "Actual speed of the vehicle (positive value for forward and backward speed) calculated as the average of the wheel speeds of one axle influenced by slip and filtered by a frequency range of 5 Hz to 20 Hz.";
CM_ SG_ 2550398718 SupplyLineBrakingRequest "Signal indicating the trailer is requesting to be braked by the commercial vehicle by means of bleeding the pneumatic supply line.";
CM_ SG_ 2550398718 VDCActive "Signal which indicates that Vehicle Dynamic Control (VDC) is active/passive.";
CM_ SG_ 2550398718 AutomTowedVehBreakActive "Signal indicating the automatic towed vehicle braking is active/passive.";
CM_ SG_ 2550398718 VehicleServiceBrakeActive "Signal indicating the service brake of the towed vehicle is active/passive, by observing the brake pressure.";
CM_ SG_ 2550398718 VehicleRetarderCtrlActive "This signal indicates the active/passive state in all cases when the installed retarder is applied by the driver’s demand or by other systems (brakes).";
CM_ SG_ 2550398718 VehicleABSActive "Signal indicating the ABS is active/passive.";
CM_ BO_ 2566833406 "ISO 11992: Towed vehicle message, electronic brake system #2/2";
CM_ SG_ 2566833406 ReferenceRetarderTorque "This parameter is the 100% reference value for all defined indicated retarder torque parameters. It is only defined once";
CM_ SG_ 2566833406 AxleLoadSum "Sum of the static vertical loads of the vehicle axles.";
CM_ SG_ 2566833406 SupplyLineBrakingRequest "Signal indicating the trailer is requesting to be braked by the commercial vehicle by means of bleeding the pneumatic supply line.";
CM_ SG_ 2566833406 LoadingRampApproachAssist "The parameter indicates whether the loading ramp approach assistance is activated.";
CM_ SG_ 2566833406 SpringBrakeEngaged "Signal indicating the vehicle spring brake is engaged.";
CM_ SG_ 2566833406 ElectrLoadPropFunc "Signal indicating the vehicle is equipped with an electrical load proportional function.";
CM_ SG_ 2566833406 SpringBrakeInstalled "Signal indicating the vehicle has one or more axle(s) fitted with spring brakes.";
CM_ SG_ 2566833406 VehicleType "Information to identify a dolly axle within the road train.";
CM_ SG_ 2566833406 ElecSupplyOfNonBrakingSys "Signal which indicates the status of the supply of non-braking systems.";
CM_ SG_ 2566833406 AmberWarningSignalReq "Request from the towed vehicle to the commercial vehicle to activate the amber warning signal on the commercial vehicle.";
CM_ SG_ 2566833406 RedWarningSignalRequest "Request from the towed vehicle to the commercial vehicle to activate the red warning signal on the commercial vehicle, which indicates certain specified failures within the braking equipment of the towed vehicles.";
CM_ SG_ 2566833406 VehicleElectrSupplySuff "Signal indicating the actual supply voltage is sufficient/insufficient for proper brake function (including over voltage).";
CM_ SG_ 2566833406 AutomTowedVehBreakActive "Signal indicating the automatic towed vehicle braking is active/passive.";
CM_ SG_ 2566833406 VehicleServiceBrakeActive "Signal indicating the service brake of the towed vehicle is active/passive, by observing the brake pressure.";
CM_ SG_ 2566833406 VehicleRetarderCtrlActive "This signal indicates the active/passive state in all cases when the installed retarder is applied by the driver’s demand or by other systems (brakes).";
CM_ SG_ 2566833406 VehicleABSActive "Signal indicating the ABS is active/passive.";
CM_ BO_ 2365507326 "ISO 11992: Towed vehicle message, electronic brake system #2/3";
CM_ SG_ 2365507326 PneumaticSupplyPressure "Actual supply pressure of the reservoir of the braking system.";
CM_ SG_ 2365507326 BrakeTemperature "Actual brake temperature.";
CM_ SG_ 2365507326 BrakeLining "Actual relative value of brake lining of a specific brake.";
CM_ SG_ 2365507326 TyrePressure "Actual tyre pressure without corrections.";
CM_ SG_ 2365507326 TyreWheelIdentTemp2 "Second part of identification number of the tyre or wheel (the number of axles).";
CM_ SG_ 2365507326 TyreWheelIdentTemp1 "First part of identification number of the tyre or wheel (position on each axle).";
CM_ SG_ 2365507326 TyreWheelIdentPressure2 "Second part of identification number of the tyre or wheel (the number of axles).";
CM_ SG_ 2365507326 TyreWheelIdentPressure1 "First part of identification number of the tyre or wheel (position on each axle).";
CM_ SG_ 2365507326 TyreWheelIdentLining2 "Second part of identification number of the tyre or wheel (the number of axles).";
CM_ SG_ 2365507326 TyreWheelIdentLining1 "First part of identification number of the tyre or wheel (position on each axle).";
CM_ SG_ 2365507326 VehiclePneumSupplySuff "Signal indicating the actual supply pressure of the reservoir of the braking system is insufficient or sufficient.";
CM_ SG_ 2365507326 BrakeTemperatureStatus "Signal which indicates that the brake temperature is higher than a specific level.";
CM_ SG_ 2365507326 BrakeLiningSufficient "Signal which indicates that the brake lining is sufficient/insufficient.";
CM_ SG_ 2365507326 TyrePressureSufficient "Signal which indicates that the tyre pressure is insufficient";
CM_ BO_ 2565013246 "ISO 11992: Towing vehicle message, general purpose message #1/1

GPM 11 replaces GFM 11 in ISO 11992:1998 part 3";
CM_ SG_ 2565013246 ODDRequest "Command signal to switch on or off the obstacle detection device (ODD).";
CM_ SG_ 2565013246 AntiTheftDeviceReq "Command signal to activate the anti-theft device.";
CM_ SG_ 2565013246 VehicleType "Information to identify a dolly axle within the road train.";
CM_ BO_ 2566807038 "ISO 11992: Towing vehicle message, general purpose message #1/2";
CM_ SG_ 2566807038 MaxVehicleSpeedLimit "Maximum vehicle velocity allowed.";
CM_ SG_ 2566807038 EngineSpeedUpperLimit "The engine speed which cannot be exceeded.";
CM_ SG_ 2566807038 EngineSpeedLowerLimit "The minimum engine speed which the engine is allowed to reach.";
CM_ BO_ 2365480958 "ISO 11992: Towing vehicle message, general purpose message #1/3";
CM_ SG_ 2365480958 EngineTorqueMode "State signal which indicates which engine torque mode is currently generating, limiting, or controlling the torque";
CM_ SG_ 2365480958 PercentLoadAtCurrentSpeed "The ratio of actual engine percent torque to maximum indicated torque available at the current engine speed, clipped to zero torque during engine braking.";
CM_ SG_ 2365480958 EngineSpeed "Actual engine speed which is calculated over a minimum crankshaft angle of 720 degrees divided by
the number of cylinders.";
CM_ SG_ 2365480958 ActualEngine_PercTorque "The calculated output torque of the engine.";
CM_ SG_ 2365480958 DriversDemandEngine_PercTorque "The torque output of the engine requested by the driver.";
CM_ SG_ 2365480958 EngineRunning "Signal which indicates whether the engine is running.";
CM_ SG_ 2365480958 EngineControlAllowed "Switch signal which indicates that engine control is allowed.";
CM_ BO_ 2566808062 "ISO 11992: Towing vehicle message, general purpose message #1/4";
CM_ SG_ 2566808062 ClutchIndptdPTOFeedback "Signal which indicates the current state of the clutch independent power take off.";
CM_ SG_ 2566808062 AccelPedalPosition "The ratio of actual accelerator pedal position to maximum pedal position.";
CM_ SG_ 2566808062 AccelPedalLowIdleSwitch "Switch signal which indicates whether the accelerator pedal low idle switch is opened or closed.";
CM_ SG_ 2566808062 StarterActive "Signal which indicates whether the starter is in use.";
CM_ SG_ 2566808062 TorqueConvOilTemp "Temperature of the torque converter lubricant.";
CM_ SG_ 2566808062 TorqueConvtOilTempWarning "Signal which indicates that the torque converter oil temperature has reached its warning level.";
CM_ SG_ 2566808062 PTOControlAllowed "Switch signal which indicates that PTO control is allowed.";
CM_ SG_ 2566808062 SecEngineMtdPTOFeedback "Signal which indicates the current state of the second engine mounted power take off.";
CM_ SG_ 2566808062 FirstEngineMtdPTOFeedback "Signal which indicates the current state of the first engine mounted power take off.";
CM_ SG_ 2566808062 SecClutchDptdPTOFeedback "Signal which indicates the current state of the second clutch dependent power take off.";
CM_ SG_ 2566808062 FirstClutchDpdtPTOFeedback "Signal which indicates the current state of the first clutch dependent power take off.";
CM_ SG_ 2566808062 CurrentGear "The gear currently engaged in the transmission or the last gear engaged while the transmission is in process of shifting to the new or selected gear.";
CM_ SG_ 2566808062 PercentClutchSlip "Parameter which represents the ratio of input shaft speed to current engine speed (in percent).";
CM_ BO_ 2566808574 "ISO 11992: Towing vehicle message, general purpose message #1/5";
CM_ SG_ 2566808574 ReferenceEngineTorque "The 100 % reference value for all defined indicated engine torque parameters.";
CM_ SG_ 2566808574 FuelLevelWarning "This signal indicates the decrease of the fuel level to a certain minimum.";
CM_ SG_ 2566808574 EngineOilPressureWarning "Signal which indicates that the engine oil pressure has reached its warning level.";
CM_ SG_ 2566808574 EngineCoolantTempWarning "Signal which indicates that the engine coolant temperature has reached its warning level.";
CM_ SG_ 2566808574 EngineOilPressure "Gauge pressure of the oil in the engine lubrication system as provided by the oil pump.";
CM_ SG_ 2566808574 EngCoolantTemp "Temperature of liquid found in engine cooling system.";
CM_ SG_ 2566808574 EngineOilTemperature "Temperature of the engine lubricant.";
CM_ BO_ 2566809086 "ISO 11992: Towing vehicle message, general purpose message #1/6";
CM_ SG_ 2566809086 AmbientAirTemperature "Temperature of air surrounding vehicle.";
CM_ BO_ 2564947710 "ISO 11992: Towed vehicle message, general purpose message #2/1

GPM 21 replaces GFM 21 in ISO 11992:1998 part 3";
CM_ SG_ 2564947710 VehicleType "Information to identify a dolly axle within the road train.";
CM_ BO_ 2566834430 "ISO 11992: Towed vehicle message, general purpose message #2/2

GPM22 replaces GFM 24 in ISO 11992:1998 part 3";
CM_ SG_ 2566834430 BodyPressure "The actual pressure in a body on the towed vehicle.";
CM_ SG_ 2566834430 BodyFluidLevel "The actual fluid level in a body on the towed vehicle.";
CM_ SG_ 2566834430 ThermalBodyTemperature "The actual temperature in a thermal body on the towed vehicle.";
CM_ SG_ 2566834430 RearObstacleDistance "The actual distance between the back of the towed vehicle and any obstacle.";
CM_ SG_ 2566834430 AntiTheftDeviceStatus "Signal which indicates that the anti-theft device is switched on or off.";
CM_ SG_ 2566834430 ODDStatus "Signal which indicates that an obstacle detection device (ODD) is active/inactive.";
CM_ BO_ 2365481214 "ISO 11992: Towed vehicle message, general purpose message #2/3";
CM_ SG_ 2365481214 ReqEngineSpeedUpperLim "The requested engine speed which is not to be exceeded.";
CM_ SG_ 2365481214 ReqEngineSpeedLowerLim "The requested minimum engine speed which the engine is to allow.";
CM_ SG_ 2365481214 ReqEngineTorqueLimit "The requested engine torque that the engine is not allowed to exceed, indicated as a ratio of the reference engine torque.";
CM_ SG_ 2365481214 ReqEngineSpeedLimit "The requested vehicle speed which the vehicle is not allowed to exceed.";
CM_ SG_ 2365481214 ReqEngineSpeed "This is the engine speed which the engine is expected to operate at.";
CM_ BO_ 2566808318 "ISO 11992: Towed vehicle message, general purpose message #2/4";
CM_ SG_ 2566808318 SecEngineMtdPTOSwitch "Signal which indicates the state of the second engine mounted power take off switch.";
CM_ SG_ 2566808318 SecClutchDpdtPTOSwitch "Signal which indicates the state of the second clutch dependent power take off switch.";
CM_ SG_ 2566808318 FirstClutchDpdtPTOSwitch "Signal which indicates the state of the first clutch dependent power take off switch.";
CM_ SG_ 2566808318 OperatingPanelActive "Signal which indicates that the operating panel is active.";
CM_ SG_ 2566808318 RefusePackerStepSwitch "Signal which indicates the state of the refuse packer step switch.";
CM_ SG_ 2566808318 EngineStopSwitch "Signal which indicates the state of the engine stop switch.";
CM_ SG_ 2566808318 EngineStartSwitch "Signal which indicates the state of the engine start switch.";
CM_ SG_ 2566808318 StarterLockoutSwitch "Signal which indicates the state of the starter lockout switch.";
CM_ SG_ 2566808318 RqstedPercentClutchSlip "Command signal to influence the clutch.";
CM_ SG_ 2566808318 FirstEngineMtdPTOSwitch "Signal which indicates the state of the first engine mounted power take off switch.";
CM_ SG_ 2566808318 ClutchIndpdtPTOSwitch "Signal which indicates the state of the clutch independent power take off switch.";
CM_ BO_ 2566808830 "ISO 11992: Towed vehicle message, general purpose message #2/5";
CM_ SG_ 2566808830 TrailerLeftSideMarkerLight "This signal indicates the state of the trailer left-hand side marker light(s).";
CM_ SG_ 2566808830 TrailerLeftReversingLight "This signal indicates the state of the trailer left-hand reversing light(s).";
CM_ SG_ 2566808830 TrailerLeftRearWidIndLight "This signal indicates the state of the trailer left-hand rear width indicator light(s).";
CM_ SG_ 2566808830 TrailerLeftRearRegPltLight "This signal indicates the state of the trailer left-hand rear registration-plate light(s).";
CM_ SG_ 2566808830 TrailerLeftRearLight "This signal indicates the state of the trailer left-hand rear light(s).";
CM_ SG_ 2566808830 TrailerLeftRearFogLight "This signal indicates the state of the trailer left-hand rear fog light(s).";
CM_ SG_ 2566808830 TrailerLeftDirIndLight "This signal indicates the state of the trailer left-hand direction indicator light(s).";
CM_ SG_ 2566808830 TrailerLeftCrnMarkerLight "This signal indicates the state of the trailer left-hand corner marker light(s).";
CM_ SG_ 2566808830 TrailerInteriorLight "This signal indicates the state of the trailer interior light(s).";
CM_ SG_ 2566808830 TrailerWorkLamp "This signal indicates the state of the trailer work lamp(s).";
CM_ SG_ 2566808830 TrailerRotatingIdentLight "This signal indicates the state of the trailer rotating identification light(s).";
CM_ SG_ 2566808830 TrailerRightStopLight "This signal indicates the state of the trailer right-hand stop light(s).";
CM_ SG_ 2566808830 TrailerRightSideMrkLight "This signal indicates the state of the trailer right-hand side marker light(s).";
CM_ SG_ 2566808830 TrailerRightReversingLight "This signal indicates the state of the trailer right-hand reversing light(s).";
CM_ SG_ 2566808830 TrailRightRearWidIndLight "This signal indicates the state of the trailer right-hand rear width indicator light(s).";
CM_ SG_ 2566808830 TrailerRightRearRegPltLight "This signal indicates the state of the trailer right-hand rear registration-plate light(s).";
CM_ SG_ 2566808830 TrailerRightRearLight "This signal indicates the state of the trailer right-hand rear light(s).";
CM_ SG_ 2566808830 TrailerRightRearFogLight "This signal indicates the state of the trailer right-hand rear fog light(s).";
CM_ SG_ 2566808830 TrailerRightDirIndLight "This signal indicates the state of the trailer right-hand direction indicator light(s).";
CM_ SG_ 2566808830 TrailerRightCrnMarkerLight "This signal indicates the state of the trailer right-hand corner marker light(s).";
CM_ SG_ 2566808830 TrailerRearWarningLight "This signal indicates the state of the trailer rear warning light(s).";
CM_ SG_ 2566808830 TrailerLeftStopLight "This signal indicates the state of the trailer left-hand stop light(s).";
CM_ BO_ 2564554494 "Reserved for ISO 15765";
CM_ SG_ 2564554494 ProtocolCtrlInformation "Part of Network Protocol Control Information (N_PCI) of a ISO 15765 message.";
CM_ BO_ 2564488958 "Reserved for ISO 15765";
CM_ SG_ 2564488958 ProtocolCtrlInformation "Part of Network Protocol Control Information (N_PCI) of a ISO 15765 message.";
BA_DEF_ BO_  "GenMsgCycleTimeFast" INT 0 3600000;
BA_DEF_ SG_  "SigType" ENUM  "Default","Range","RangeSigned","ASCII","Discrete","Control","ReferencePGN","DTC","StringDelimiter","StringLength","StringLengthControl";
BA_DEF_ SG_  "GenSigStartValue" INT 0 10000;
BA_DEF_ SG_  "GenSigSendType" ENUM  "Cyclic","OnWrite","reserved","OnChange","reserved","reserved","reserved","NoSigSendType";
BA_DEF_ SG_  "GenSigILSupport" ENUM  "Yes","No";
BA_DEF_ SG_  "GenSigEVName" STRING ;
BA_DEF_ SG_  "SPN" INT 0 524287;
BA_DEF_ SG_  "DDI" INT 0 65535;
BA_DEF_ SG_  "SAEDocument" STRING ;
BA_DEF_ BO_  "GenMsgStartDelayTime" INT 0 100000;
BA_DEF_ BO_  "GenMsgILSupport" ENUM  "Yes","No";
BA_DEF_ BO_  "GenMsgRequestable" INT 0 1;
BA_DEF_ BO_  "GenMsgSendType" ENUM  "cyclic","reserved","cyclicIfActive","reserved","reserved","reserved","reserved","reserved","noMsgSendType";
BA_DEF_ BO_  "VFrameFormat" ENUM  "StandardCAN","ExtendedCAN","reserved","J1939PG";
BA_DEF_ BO_  "SingleFrame" INT 0 1;
BA_DEF_ BO_  "GenMsgCycleTime" INT 0 3600000;
BA_DEF_ BO_  "SAE_Document" STRING ;
BA_DEF_ SG_  "SystemSignalLongSymbol" STRING ;
BA_DEF_DEF_  "GenMsgCycleTimeFast" 0;
BA_DEF_DEF_  "SigType" "Default";
BA_DEF_DEF_  "GenSigStartValue" 0;
BA_DEF_DEF_  "GenSigSendType" "NoSigSendType";
BA_DEF_DEF_  "GenSigILSupport" "Yes";
BA_DEF_DEF_  "GenSigEVName" "Env@Nodename_@Signame";
BA_DEF_DEF_  "SPN" 0;
BA_DEF_DEF_  "DDI" 0;
BA_DEF_DEF_  "SAEDocument" "";
BA_DEF_DEF_  "GenMsgStartDelayTime" 0;
BA_DEF_DEF_  "GenMsgILSupport" "Yes";
BA_DEF_DEF_  "GenMsgRequestable" 1;
BA_DEF_DEF_  "GenMsgSendType" "noMsgSendType";
BA_DEF_DEF_  "VFrameFormat" "J1939PG";
BA_DEF_DEF_  "SingleFrame" 1;
BA_DEF_DEF_  "GenMsgCycleTime" 0;
BA_DEF_DEF_  "SAE_Document" "";
BA_DEF_DEF_  "SystemSignalLongSymbol" "";
BA_ "GenMsgSendType" BO_ 2365473278 0;
BA_ "GenMsgCycleTime" BO_ 2365473278 1000;
BA_ "SAE_Document" BO_ 2365473278 "J1939-71";
BA_ "GenMsgSendType" BO_ 2365485822 0;
BA_ "GenMsgCycleTime" BO_ 2365485822 50;
BA_ "SAE_Document" BO_ 2365485822 "J1939-71";
BA_ "SAE_Document" BO_ 2633926654 "J1939-71";
BA_ "SAE_Document" BO_ 2633926398 "J1939-71";
BA_ "SAE_Document" BO_ 2633926142 "J1939-71";
BA_ "SAE_Document" BO_ 2633925886 "J1939-71";
BA_ "SAE_Document" BO_ 2633925630 "J1939-71";
BA_ "SAE_Document" BO_ 2633925374 "J1939-71";
BA_ "SAE_Document" BO_ 2633927422 "J1939-71";
BA_ "SAE_Document" BO_ 2633927166 "J1939-71";
BA_ "SAE_Document" BO_ 2633926910 "J1939-71";
BA_ "GenMsgSendType" BO_ 2566768894 0;
BA_ "GenMsgCycleTime" BO_ 2566768894 1000;
BA_ "SAE_Document" BO_ 2566768894 "J1939-71";
BA_ "GenMsgSendType" BO_ 2566769406 0;
BA_ "GenMsgCycleTime" BO_ 2566769406 1000;
BA_ "SAE_Document" BO_ 2566769406 "J1939-71";
BA_ "SAE_Document" BO_ 2566839550 "J1939-71";
BA_ "GenMsgSendType" BO_ 2633934334 0;
BA_ "GenMsgCycleTime" BO_ 2633934334 1000;
BA_ "SAE_Document" BO_ 2633934334 "J1939-71";
BA_ "GenMsgSendType" BO_ 2566825726 0;
BA_ "GenMsgCycleTime" BO_ 2566825726 500;
BA_ "SAE_Document" BO_ 2566825726 "J1939-71";
BA_ "GenMsgSendType" BO_ 2566770942 0;
BA_ "GenMsgCycleTime" BO_ 2566770942 5000;
BA_ "SAE_Document" BO_ 2566770942 "J1939-71";
BA_ "GenMsgSendType" BO_ 2566846206 0;
BA_ "GenMsgCycleTime" BO_ 2566846206 5000;
BA_ "SAE_Document" BO_ 2566846206 "J1939-71";
BA_ "GenMsgSendType" BO_ 2566811134 0;
BA_ "GenMsgCycleTime" BO_ 2566811134 1000;
BA_ "SAE_Document" BO_ 2566811134 "J1939-71";
BA_ "GenMsgSendType" BO_ 2298375934 0;
BA_ "GenMsgCycleTime" BO_ 2298375934 20;
BA_ "SAE_Document" BO_ 2298375934 "J1939-71";
BA_ "GenMsgSendType" BO_ 2565867774 0;
BA_ "GenMsgCycleTime" BO_ 2565867774 50;
BA_ "SAE_Document" BO_ 2565867774 "J1939-71";
BA_ "SAE_Document" BO_ 2566841854 "J1939-71";
BA_ "GenMsgSendType" BO_ 2365449982 0;
BA_ "GenMsgCycleTime" BO_ 2365449982 100;
BA_ "SAE_Document" BO_ 2365449982 "J1939-71";
BA_ "SAE_Document" BO_ 2633939198 "J1939-71";
BA_ "SAE_Document" BO_ 2633927678 "J1939-71";
BA_ "SAE_Document" BO_ 2633925118 "J1939-71";
BA_ "SAE_Document" BO_ 2633937662 "J1939-71";
BA_ "SAE_Document" BO_ 2566804990 "J1939-71";
BA_ "SAE_Document" BO_ 2633936894 "J1939-71";
BA_ "GenMsgSendType" BO_ 2566757630 0;
BA_ "GenMsgCycleTime" BO_ 2566757630 1000;
BA_ "SAE_Document" BO_ 2566757630 "J1939-71";
BA_ "GenMsgSendType" BO_ 2566757886 0;
BA_ "GenMsgCycleTime" BO_ 2566757886 1000;
BA_ "SAE_Document" BO_ 2566757886 "J1939-71";
BA_ "GenMsgSendType" BO_ 2566759678 0;
BA_ "GenMsgCycleTime" BO_ 2566759678 100;
BA_ "SAE_Document" BO_ 2566759678 "J1939-71";
BA_ "GenMsgSendType" BO_ 2432541438 0;
BA_ "GenMsgCycleTime" BO_ 2432541438 500;
BA_ "SAE_Document" BO_ 2432541438 "J1939-71";
BA_ "GenMsgSendType" BO_ 2566761214 0;
BA_ "GenMsgCycleTime" BO_ 2566761214 500;
BA_ "SAE_Document" BO_ 2566761214 "J1939-71";
BA_ "GenMsgSendType" BO_ 2432541694 0;
BA_ "GenMsgCycleTime" BO_ 2432541694 100;
BA_ "SAE_Document" BO_ 2432541694 "J1939-71";
BA_ "GenMsgSendType" BO_ 2566759934 0;
BA_ "GenMsgCycleTime" BO_ 2566759934 100;
BA_ "SAE_Document" BO_ 2566759934 "J1939-71";
BA_ "GenMsgSendType" BO_ 2566757374 0;
BA_ "GenMsgCycleTime" BO_ 2566757374 1000;
BA_ "SAE_Document" BO_ 2566757374 "J1939-71";
BA_ "GenMsgSendType" BO_ 2364546302 0;
BA_ "GenMsgCycleTime" BO_ 2364546302 100;
BA_ "SAE_Document" BO_ 2364546302 "J1939-75";
BA_ "GenMsgSendType" BO_ 2431654654 0;
BA_ "GenMsgCycleTime" BO_ 2431654654 50;
BA_ "SAE_Document" BO_ 2431654654 "J1939-71";
BA_ "GenMsgSendType" BO_ 2364545534 0;
BA_ "GenMsgCycleTime" BO_ 2364545534 5000;
BA_ "SAE_Document" BO_ 2364545534 "J1939-71";
BA_ "GenMsgSendType" BO_ 2364545278 0;
BA_ "GenMsgCycleTime" BO_ 2364545278 5000;
BA_ "SAE_Document" BO_ 2364545278 "J1939-71";
BA_ "GenMsgSendType" BO_ 2364545022 0;
BA_ "GenMsgCycleTime" BO_ 2364545022 5000;
BA_ "SAE_Document" BO_ 2364545022 "J1939-71";
BA_ "GenMsgSendType" BO_ 2364544766 0;
BA_ "GenMsgCycleTime" BO_ 2364544766 5000;
BA_ "SAE_Document" BO_ 2364544766 "J1939-71";
BA_ "GenMsgSendType" BO_ 2364544510 0;
BA_ "GenMsgCycleTime" BO_ 2364544510 100;
BA_ "SAE_Document" BO_ 2364544510 "J1939-75";
BA_ "GenMsgSendType" BO_ 2364544254 0;
BA_ "GenMsgCycleTime" BO_ 2364544254 50;
BA_ "SAE_Document" BO_ 2364544254 "J1939-71";
BA_ "GenMsgSendType" BO_ 2349006590 0;
BA_ "GenMsgCycleTime" BO_ 2349006590 10;
BA_ "SAE_Document" BO_ 2349006590 "ISO11992";
BA_ "GenMsgSendType" BO_ 2566834686 0;
BA_ "GenMsgCycleTime" BO_ 2566834686 100;
BA_ "SAE_Document" BO_ 2566834686 "ISO11992";
BA_ "GenMsgSendType" BO_ 2550398718 0;
BA_ "GenMsgCycleTime" BO_ 2550398718 10;
BA_ "SAE_Document" BO_ 2550398718 "ISO11992";
BA_ "GenMsgSendType" BO_ 2566833406 0;
BA_ "GenMsgCycleTime" BO_ 2566833406 100;
BA_ "SAE_Document" BO_ 2566833406 "ISO11992";
BA_ "GenMsgSendType" BO_ 2365507326 0;
BA_ "GenMsgCycleTime" BO_ 2365507326 100;
BA_ "SAE_Document" BO_ 2365507326 "ISO11992";
BA_ "GenMsgSendType" BO_ 2565013246 0;
BA_ "GenMsgCycleTime" BO_ 2565013246 100;
BA_ "SAE_Document" BO_ 2565013246 "ISO11992";
BA_ "GenMsgSendType" BO_ 2566807038 0;
BA_ "GenMsgCycleTime" BO_ 2566807038 500;
BA_ "SAE_Document" BO_ 2566807038 "ISO11992";
BA_ "GenMsgSendType" BO_ 2365480958 0;
BA_ "GenMsgCycleTime" BO_ 2365480958 50;
BA_ "SAE_Document" BO_ 2365480958 "ISO11992";
BA_ "GenMsgSendType" BO_ 2566808062 0;
BA_ "GenMsgCycleTime" BO_ 2566808062 100;
BA_ "SAE_Document" BO_ 2566808062 "ISO11992";
BA_ "GenMsgSendType" BO_ 2566808574 0;
BA_ "GenMsgCycleTime" BO_ 2566808574 1000;
BA_ "SAE_Document" BO_ 2566808574 "ISO11992";
BA_ "GenMsgSendType" BO_ 2566809086 0;
BA_ "GenMsgCycleTime" BO_ 2566809086 100;
BA_ "SAE_Document" BO_ 2566809086 "ISO11992";
BA_ "GenMsgSendType" BO_ 2564947710 0;
BA_ "GenMsgCycleTime" BO_ 2564947710 100;
BA_ "SAE_Document" BO_ 2564947710 "ISO11992";
BA_ "GenMsgSendType" BO_ 2566834430 0;
BA_ "GenMsgCycleTime" BO_ 2566834430 100;
BA_ "SAE_Document" BO_ 2566834430 "ISO11992";
BA_ "GenMsgSendType" BO_ 2365481214 0;
BA_ "GenMsgCycleTime" BO_ 2365481214 100;
BA_ "SAE_Document" BO_ 2365481214 "ISO11992";
BA_ "GenMsgSendType" BO_ 2566808318 0;
BA_ "GenMsgCycleTime" BO_ 2566808318 100;
BA_ "SAE_Document" BO_ 2566808318 "ISO11992";
BA_ "GenMsgSendType" BO_ 2566808830 0;
BA_ "GenMsgCycleTime" BO_ 2566808830 100;
BA_ "SAE_Document" BO_ 2566808830 "ISO11992";
BA_ "SAE_Document" BO_ 2564554494 "ISO15765";
BA_ "SAE_Document" BO_ 2564488958 "ISO15765";
BA_ "SigType" SG_ 2365473278 ImplementRearWorkLightCmd 5;
BA_ "SPN" SG_ 2365473278 ImplementRearWorkLightCmd 2405;
BA_ "SAEDocument" SG_ 2365473278 ImplementRearWorkLightCmd "J1939-71";
BA_ "SigType" SG_ 2365473278 ImplementLeftForwardWorkLightCmd 5;
BA_ "SPN" SG_ 2365473278 ImplementLeftForwardWorkLightCmd 2399;
BA_ "SAEDocument" SG_ 2365473278 ImplementLeftForwardWorkLightCmd "J1939-71";
BA_ "SigType" SG_ 2365473278 ImplmentRightForwardWorkLightCmd 5;
BA_ "SPN" SG_ 2365473278 ImplmentRightForwardWorkLightCmd 2401;
BA_ "SAEDocument" SG_ 2365473278 ImplmentRightForwardWorkLightCmd "J1939-71";
BA_ "SigType" SG_ 2365473278 LightingDataRqCmd 5;
BA_ "SPN" SG_ 2365473278 LightingDataRqCmd 2393;
BA_ "SAEDocument" SG_ 2365473278 LightingDataRqCmd "J1939-71";
BA_ "SigType" SG_ 2365473278 ImplementLeftFacingWorkLightCmd 5;
BA_ "SPN" SG_ 2365473278 ImplementLeftFacingWorkLightCmd 2597;
BA_ "SAEDocument" SG_ 2365473278 ImplementLeftFacingWorkLightCmd "J1939-71";
BA_ "SigType" SG_ 2365473278 ImplementRightFacingWorkLightCmd 5;
BA_ "SPN" SG_ 2365473278 ImplementRightFacingWorkLightCmd 2406;
BA_ "SAEDocument" SG_ 2365473278 ImplementRightFacingWorkLightCmd "J1939-71";
BA_ "SigType" SG_ 2365473278 ImplementOEMOption1LightCmd 5;
BA_ "SPN" SG_ 2365473278 ImplementOEMOption1LightCmd 2395;
BA_ "SAEDocument" SG_ 2365473278 ImplementOEMOption1LightCmd "J1939-71";
BA_ "SigType" SG_ 2365473278 ImplementOEMOption2LightCmd 5;
BA_ "SPN" SG_ 2365473278 ImplementOEMOption2LightCmd 2397;
BA_ "SAEDocument" SG_ 2365473278 ImplementOEMOption2LightCmd "J1939-71";
BA_ "SigType" SG_ 2365473278 TrctrFrntHghMountedWorkLightsCmd 5;
BA_ "SPN" SG_ 2365473278 TrctrFrntHghMountedWorkLightsCmd 2355;
BA_ "SAEDocument" SG_ 2365473278 TrctrFrntHghMountedWorkLightsCmd "J1939-71";
BA_ "SigType" SG_ 2365473278 TrctrFrntLowMountedWorkLightsCmd 5;
BA_ "SPN" SG_ 2365473278 TrctrFrntLowMountedWorkLightsCmd 2353;
BA_ "SAEDocument" SG_ 2365473278 TrctrFrntLowMountedWorkLightsCmd "J1939-71";
BA_ "SigType" SG_ 2365473278 TrctrSdeHighMountedWorkLightsCmd 5;
BA_ "SPN" SG_ 2365473278 TrctrSdeHighMountedWorkLightsCmd 2365;
BA_ "SAEDocument" SG_ 2365473278 TrctrSdeHighMountedWorkLightsCmd "J1939-71";
BA_ "SigType" SG_ 2365473278 TrctrSideLowMountedWorkLightsCmd 5;
BA_ "SPN" SG_ 2365473278 TrctrSideLowMountedWorkLightsCmd 2363;
BA_ "SAEDocument" SG_ 2365473278 TrctrSideLowMountedWorkLightsCmd "J1939-71";
BA_ "SigType" SG_ 2365473278 TrctrRarHighMountedWorkLightsCmd 5;
BA_ "SPN" SG_ 2365473278 TrctrRarHighMountedWorkLightsCmd 2361;
BA_ "SAEDocument" SG_ 2365473278 TrctrRarHighMountedWorkLightsCmd "J1939-71";
BA_ "SigType" SG_ 2365473278 TrctrRearLowMountedWorkLightsCmd 5;
BA_ "SPN" SG_ 2365473278 TrctrRearLowMountedWorkLightsCmd 2359;
BA_ "SAEDocument" SG_ 2365473278 TrctrRearLowMountedWorkLightsCmd "J1939-71";
BA_ "SigType" SG_ 2365473278 TrctrUndrsdeMountedWorkLightsCmd 5;
BA_ "SPN" SG_ 2365473278 TrctrUndrsdeMountedWorkLightsCmd 2357;
BA_ "SAEDocument" SG_ 2365473278 TrctrUndrsdeMountedWorkLightsCmd "J1939-71";
BA_ "SigType" SG_ 2365473278 RearFogLightCmd 5;
BA_ "SPN" SG_ 2365473278 RearFogLightCmd 2389;
BA_ "SAEDocument" SG_ 2365473278 RearFogLightCmd "J1939-71";
BA_ "SigType" SG_ 2365473278 TractorMarkerLightCmd 5;
BA_ "SPN" SG_ 2365473278 TractorMarkerLightCmd 2377;
BA_ "SAEDocument" SG_ 2365473278 TractorMarkerLightCmd "J1939-71";
BA_ "SigType" SG_ 2365473278 ImplementMarkerLightCmd 5;
BA_ "SPN" SG_ 2365473278 ImplementMarkerLightCmd 2379;
BA_ "SAEDocument" SG_ 2365473278 ImplementMarkerLightCmd "J1939-71";
BA_ "SigType" SG_ 2365473278 TractorClearanceLightCmd 5;
BA_ "SPN" SG_ 2365473278 TractorClearanceLightCmd 2381;
BA_ "SAEDocument" SG_ 2365473278 TractorClearanceLightCmd "J1939-71";
BA_ "SigType" SG_ 2365473278 ImplementClearanceLightCmd 5;
BA_ "SPN" SG_ 2365473278 ImplementClearanceLightCmd 2383;
BA_ "SAEDocument" SG_ 2365473278 ImplementClearanceLightCmd "J1939-71";
BA_ "SigType" SG_ 2365473278 LeftStopLightCmd 5;
BA_ "SPN" SG_ 2365473278 LeftStopLightCmd 2371;
BA_ "SAEDocument" SG_ 2365473278 LeftStopLightCmd "J1939-71";
BA_ "SigType" SG_ 2365473278 RightStopLightCmd 5;
BA_ "SPN" SG_ 2365473278 RightStopLightCmd 2373;
BA_ "SAEDocument" SG_ 2365473278 RightStopLightCmd "J1939-71";
BA_ "SigType" SG_ 2365473278 CenterStopLightCmd 5;
BA_ "SPN" SG_ 2365473278 CenterStopLightCmd 2375;
BA_ "SAEDocument" SG_ 2365473278 CenterStopLightCmd "J1939-71";
BA_ "SigType" SG_ 2365473278 BackUpLightAndAlarmHornCmd 5;
BA_ "SPN" SG_ 2365473278 BackUpLightAndAlarmHornCmd 2391;
BA_ "SAEDocument" SG_ 2365473278 BackUpLightAndAlarmHornCmd "J1939-71";
BA_ "SigType" SG_ 2365473278 LeftTurnSignalLightsCmd 5;
BA_ "SPN" SG_ 2365473278 LeftTurnSignalLightsCmd 2367;
BA_ "SAEDocument" SG_ 2365473278 LeftTurnSignalLightsCmd "J1939-71";
BA_ "SigType" SG_ 2365473278 RightTurnSignalLightsCmd 5;
BA_ "SPN" SG_ 2365473278 RightTurnSignalLightsCmd 2369;
BA_ "SAEDocument" SG_ 2365473278 RightTurnSignalLightsCmd "J1939-71";
BA_ "SigType" SG_ 2365473278 RotatingBeaconLightCmd 5;
BA_ "SPN" SG_ 2365473278 RotatingBeaconLightCmd 2385;
BA_ "SAEDocument" SG_ 2365473278 RotatingBeaconLightCmd "J1939-71";
BA_ "SigType" SG_ 2365473278 TractorFrontFogLightsCmd 5;
BA_ "SPN" SG_ 2365473278 TractorFrontFogLightsCmd 2387;
BA_ "SAEDocument" SG_ 2365473278 TractorFrontFogLightsCmd "J1939-71";
BA_ "SigType" SG_ 2365473278 HighBeamHeadLightCmd 5;
BA_ "SPN" SG_ 2365473278 HighBeamHeadLightCmd 2347;
BA_ "SAEDocument" SG_ 2365473278 HighBeamHeadLightCmd "J1939-71";
BA_ "SigType" SG_ 2365473278 LowBeamHeadLightCmd 5;
BA_ "SPN" SG_ 2365473278 LowBeamHeadLightCmd 2349;
BA_ "SAEDocument" SG_ 2365473278 LowBeamHeadLightCmd "J1939-71";
BA_ "SigType" SG_ 2365473278 AltBeamHeadLightCmd 5;
BA_ "SPN" SG_ 2365473278 AltBeamHeadLightCmd 2351;
BA_ "SAEDocument" SG_ 2365473278 AltBeamHeadLightCmd "J1939-71";
BA_ "SigType" SG_ 2365473278 RunningLightCmd 5;
BA_ "SPN" SG_ 2365473278 RunningLightCmd 2403;
BA_ "SAEDocument" SG_ 2365473278 RunningLightCmd "J1939-71";
BA_ "SigType" SG_ 2365485822 LandLevelingSystemEnableStatus 5;
BA_ "SPN" SG_ 2365485822 LandLevelingSystemEnableStatus 5409;
BA_ "SAEDocument" SG_ 2365485822 LandLevelingSystemEnableStatus "J1939-71";
BA_ "SPN" SG_ 2365485822 BladeCtrlModeRight 5408;
BA_ "SAEDocument" SG_ 2365485822 BladeCtrlModeRight "J1939-71";
BA_ "SPN" SG_ 2365485822 BladeCtrlModeLeft 5407;
BA_ "SAEDocument" SG_ 2365485822 BladeCtrlModeLeft "J1939-71";
BA_ "SPN" SG_ 2365485822 BladeCtrlMode 1578;
BA_ "SAEDocument" SG_ 2365485822 BladeCtrlMode "J1939-71";
BA_ "SPN" SG_ 2365485822 BladeDurationAndDirection 1577;
BA_ "SAEDocument" SG_ 2365485822 BladeDurationAndDirection "J1939-71";
BA_ "SPN" SG_ 2633926654 EngActualIgntTiming 1436;
BA_ "SAEDocument" SG_ 2633926654 EngActualIgntTiming "J1939-71";
BA_ "SPN" SG_ 2633926654 EngDesiredIgntTiming3 1435;
BA_ "SAEDocument" SG_ 2633926654 EngDesiredIgntTiming3 "J1939-71";
BA_ "SPN" SG_ 2633926654 EngDesiredIgntTiming2 1434;
BA_ "SAEDocument" SG_ 2633926654 EngDesiredIgntTiming2 "J1939-71";
BA_ "SPN" SG_ 2633926654 EngDesiredIgntTiming1 1433;
BA_ "SAEDocument" SG_ 2633926654 EngDesiredIgntTiming1 "J1939-71";
BA_ "SPN" SG_ 2633926398 EngCyl20IgntTiming 1432;
BA_ "SAEDocument" SG_ 2633926398 EngCyl20IgntTiming "J1939-71";
BA_ "SPN" SG_ 2633926398 EngCyl19IgntTiming 1431;
BA_ "SAEDocument" SG_ 2633926398 EngCyl19IgntTiming "J1939-71";
BA_ "SPN" SG_ 2633926398 EngCyl18IgntTiming 1430;
BA_ "SAEDocument" SG_ 2633926398 EngCyl18IgntTiming "J1939-71";
BA_ "SPN" SG_ 2633926398 EngCyl17IgntTiming 1429;
BA_ "SAEDocument" SG_ 2633926398 EngCyl17IgntTiming "J1939-71";
BA_ "SPN" SG_ 2633926142 EngCyl16IgntTiming 1428;
BA_ "SAEDocument" SG_ 2633926142 EngCyl16IgntTiming "J1939-71";
BA_ "SPN" SG_ 2633926142 EngCyl15IgntTiming 1427;
BA_ "SAEDocument" SG_ 2633926142 EngCyl15IgntTiming "J1939-71";
BA_ "SPN" SG_ 2633926142 EngCyl14IgntTiming 1426;
BA_ "SAEDocument" SG_ 2633926142 EngCyl14IgntTiming "J1939-71";
BA_ "SPN" SG_ 2633926142 EngCyl13IgntTiming 1425;
BA_ "SAEDocument" SG_ 2633926142 EngCyl13IgntTiming "J1939-71";
BA_ "SPN" SG_ 2633925886 EngCyl12IgntTiming 1424;
BA_ "SAEDocument" SG_ 2633925886 EngCyl12IgntTiming "J1939-71";
BA_ "SPN" SG_ 2633925886 EngCyl11IgntTiming 1423;
BA_ "SAEDocument" SG_ 2633925886 EngCyl11IgntTiming "J1939-71";
BA_ "SPN" SG_ 2633925886 EngCyl10IgntTiming 1422;
BA_ "SAEDocument" SG_ 2633925886 EngCyl10IgntTiming "J1939-71";
BA_ "SPN" SG_ 2633925886 EngCyl9IgntTiming 1421;
BA_ "SAEDocument" SG_ 2633925886 EngCyl9IgntTiming "J1939-71";
BA_ "SPN" SG_ 2633925630 EngCyl8IgntTiming 1420;
BA_ "SAEDocument" SG_ 2633925630 EngCyl8IgntTiming "J1939-71";
BA_ "SPN" SG_ 2633925630 EngCyl7IgntTiming 1419;
BA_ "SAEDocument" SG_ 2633925630 EngCyl7IgntTiming "J1939-71";
BA_ "SPN" SG_ 2633925630 EngCyl6IgntTiming 1418;
BA_ "SAEDocument" SG_ 2633925630 EngCyl6IgntTiming "J1939-71";
BA_ "SPN" SG_ 2633925630 EngCyl5IgntTiming 1417;
BA_ "SAEDocument" SG_ 2633925630 EngCyl5IgntTiming "J1939-71";
BA_ "SPN" SG_ 2633925374 EngCyl4IgntTiming 1416;
BA_ "SAEDocument" SG_ 2633925374 EngCyl4IgntTiming "J1939-71";
BA_ "SPN" SG_ 2633925374 EngCyl3IgntTiming 1415;
BA_ "SAEDocument" SG_ 2633925374 EngCyl3IgntTiming "J1939-71";
BA_ "SPN" SG_ 2633925374 EngCyl2IgntTiming 1414;
BA_ "SAEDocument" SG_ 2633925374 EngCyl2IgntTiming "J1939-71";
BA_ "SPN" SG_ 2633925374 EngCyl1IgntTiming 1413;
BA_ "SAEDocument" SG_ 2633925374 EngCyl1IgntTiming "J1939-71";
BA_ "SigType" SG_ 2633927422 EngCyl20IgntTransSecondOutput 1;
BA_ "SPN" SG_ 2633927422 EngCyl20IgntTransSecondOutput 1412;
BA_ "SAEDocument" SG_ 2633927422 EngCyl20IgntTransSecondOutput "J1939-71";
BA_ "SigType" SG_ 2633927422 EngCyl19IgntTransSecondOutput 1;
BA_ "SPN" SG_ 2633927422 EngCyl19IgntTransSecondOutput 1411;
BA_ "SAEDocument" SG_ 2633927422 EngCyl19IgntTransSecondOutput "J1939-71";
BA_ "SigType" SG_ 2633927422 EngCyl18IgntTransSecondOutput 1;
BA_ "SPN" SG_ 2633927422 EngCyl18IgntTransSecondOutput 1410;
BA_ "SAEDocument" SG_ 2633927422 EngCyl18IgntTransSecondOutput "J1939-71";
BA_ "SigType" SG_ 2633927422 EngCyl17IgntTransSecondOutput 1;
BA_ "SPN" SG_ 2633927422 EngCyl17IgntTransSecondOutput 1409;
BA_ "SAEDocument" SG_ 2633927422 EngCyl17IgntTransSecondOutput "J1939-71";
BA_ "SigType" SG_ 2633927166 EngCyl16IgntTransSecondOutput 1;
BA_ "SPN" SG_ 2633927166 EngCyl16IgntTransSecondOutput 1408;
BA_ "SAEDocument" SG_ 2633927166 EngCyl16IgntTransSecondOutput "J1939-71";
BA_ "SigType" SG_ 2633927166 EngCyl15IgntTransSecondOutput 1;
BA_ "SPN" SG_ 2633927166 EngCyl15IgntTransSecondOutput 1407;
BA_ "SAEDocument" SG_ 2633927166 EngCyl15IgntTransSecondOutput "J1939-71";
BA_ "SigType" SG_ 2633927166 EngCyl14IgntTransSecondOutput 1;
BA_ "SPN" SG_ 2633927166 EngCyl14IgntTransSecondOutput 1406;
BA_ "SAEDocument" SG_ 2633927166 EngCyl14IgntTransSecondOutput "J1939-71";
BA_ "SigType" SG_ 2633927166 EngCyl13IgntTransSecondOutput 1;
BA_ "SPN" SG_ 2633927166 EngCyl13IgntTransSecondOutput 1405;
BA_ "SAEDocument" SG_ 2633927166 EngCyl13IgntTransSecondOutput "J1939-71";
BA_ "SigType" SG_ 2633927166 EngCyl12IgntTransSecondOutput 1;
BA_ "SPN" SG_ 2633927166 EngCyl12IgntTransSecondOutput 1404;
BA_ "SAEDocument" SG_ 2633927166 EngCyl12IgntTransSecondOutput "J1939-71";
BA_ "SigType" SG_ 2633927166 EngCyl11IgntTransSecondOutput 1;
BA_ "SPN" SG_ 2633927166 EngCyl11IgntTransSecondOutput 1403;
BA_ "SAEDocument" SG_ 2633927166 EngCyl11IgntTransSecondOutput "J1939-71";
BA_ "SigType" SG_ 2633927166 EngCyl10IgntTransSecondOutput 1;
BA_ "SPN" SG_ 2633927166 EngCyl10IgntTransSecondOutput 1402;
BA_ "SAEDocument" SG_ 2633927166 EngCyl10IgntTransSecondOutput "J1939-71";
BA_ "SigType" SG_ 2633927166 EngCyl9IgntTransSecondOutput 1;
BA_ "SPN" SG_ 2633927166 EngCyl9IgntTransSecondOutput 1401;
BA_ "SAEDocument" SG_ 2633927166 EngCyl9IgntTransSecondOutput "J1939-71";
BA_ "SigType" SG_ 2633926910 EngCyl8IgntTransSecondOutput 1;
BA_ "SPN" SG_ 2633926910 EngCyl8IgntTransSecondOutput 1400;
BA_ "SAEDocument" SG_ 2633926910 EngCyl8IgntTransSecondOutput "J1939-71";
BA_ "SigType" SG_ 2633926910 EngCyl7IgntTransSecondOutput 1;
BA_ "SPN" SG_ 2633926910 EngCyl7IgntTransSecondOutput 1399;
BA_ "SAEDocument" SG_ 2633926910 EngCyl7IgntTransSecondOutput "J1939-71";
BA_ "SigType" SG_ 2633926910 EngCyl6IgntTransSecondOutput 1;
BA_ "SPN" SG_ 2633926910 EngCyl6IgntTransSecondOutput 1398;
BA_ "SAEDocument" SG_ 2633926910 EngCyl6IgntTransSecondOutput "J1939-71";
BA_ "SigType" SG_ 2633926910 EngCyl5IgntTransSecondOutput 1;
BA_ "SPN" SG_ 2633926910 EngCyl5IgntTransSecondOutput 1397;
BA_ "SAEDocument" SG_ 2633926910 EngCyl5IgntTransSecondOutput "J1939-71";
BA_ "SigType" SG_ 2633926910 EngCyl4IgntTransSecondOutput 1;
BA_ "SPN" SG_ 2633926910 EngCyl4IgntTransSecondOutput 1396;
BA_ "SAEDocument" SG_ 2633926910 EngCyl4IgntTransSecondOutput "J1939-71";
BA_ "SigType" SG_ 2633926910 EngCyl3IgntTransSecondOutput 1;
BA_ "SPN" SG_ 2633926910 EngCyl3IgntTransSecondOutput 1395;
BA_ "SAEDocument" SG_ 2633926910 EngCyl3IgntTransSecondOutput "J1939-71";
BA_ "SigType" SG_ 2633926910 EngCyl2IgntTransSecondOutput 1;
BA_ "SPN" SG_ 2633926910 EngCyl2IgntTransSecondOutput 1394;
BA_ "SAEDocument" SG_ 2633926910 EngCyl2IgntTransSecondOutput "J1939-71";
BA_ "SigType" SG_ 2633926910 EngCyl1IgntTransSecondOutput 1;
BA_ "SPN" SG_ 2633926910 EngCyl1IgntTransSecondOutput 1393;
BA_ "SAEDocument" SG_ 2633926910 EngCyl1IgntTransSecondOutput "J1939-71";
BA_ "SPN" SG_ 2566768894 EngOprtrPrmryIntrmdtSpdSlctState 2892;
BA_ "SAEDocument" SG_ 2566768894 EngOprtrPrmryIntrmdtSpdSlctState "J1939-71";
BA_ "SPN" SG_ 2566769406 EngOprtrPrmryIntrmdteSpeedSelect 2880;
BA_ "SAEDocument" SG_ 2566769406 EngOprtrPrmryIntrmdteSpeedSelect "J1939-71";
BA_ "SigType" SG_ 2566839550 EngTotalIdleHours 1;
BA_ "SPN" SG_ 2566839550 EngTotalIdleHours 235;
BA_ "SAEDocument" SG_ 2566839550 EngTotalIdleHours "J1939-71";
BA_ "SigType" SG_ 2566839550 EngTotalIdleFuelUsed 1;
BA_ "SPN" SG_ 2566839550 EngTotalIdleFuelUsed 236;
BA_ "SAEDocument" SG_ 2566839550 EngTotalIdleFuelUsed "J1939-71";
BA_ "SigType" SG_ 2633934334 EngIntakeManifold6Temp 1;
BA_ "SPN" SG_ 2633934334 EngIntakeManifold6Temp 1803;
BA_ "SAEDocument" SG_ 2633934334 EngIntakeManifold6Temp "J1939-71";
BA_ "SigType" SG_ 2633934334 EngIntakeManifold5Temp 1;
BA_ "SPN" SG_ 2633934334 EngIntakeManifold5Temp 1802;
BA_ "SAEDocument" SG_ 2633934334 EngIntakeManifold5Temp "J1939-71";
BA_ "SigType" SG_ 2633934334 EngIntakeManifold4Temp 1;
BA_ "SPN" SG_ 2633934334 EngIntakeManifold4Temp 1133;
BA_ "SAEDocument" SG_ 2633934334 EngIntakeManifold4Temp "J1939-71";
BA_ "SigType" SG_ 2633934334 EngIntakeManifold3Temp 1;
BA_ "SPN" SG_ 2633934334 EngIntakeManifold3Temp 1132;
BA_ "SAEDocument" SG_ 2633934334 EngIntakeManifold3Temp "J1939-71";
BA_ "SigType" SG_ 2633934334 EngIntakeManifold2Temp 1;
BA_ "SPN" SG_ 2633934334 EngIntakeManifold2Temp 1131;
BA_ "SAEDocument" SG_ 2633934334 EngIntakeManifold2Temp "J1939-71";
BA_ "SigType" SG_ 2566825726 EngTurbo4BoostPress 1;
BA_ "SPN" SG_ 2566825726 EngTurbo4BoostPress 1130;
BA_ "SAEDocument" SG_ 2566825726 EngTurbo4BoostPress "J1939-71";
BA_ "SigType" SG_ 2566825726 EngTurbo3BoostPress 1;
BA_ "SPN" SG_ 2566825726 EngTurbo3BoostPress 1129;
BA_ "SAEDocument" SG_ 2566825726 EngTurbo3BoostPress "J1939-71";
BA_ "SigType" SG_ 2566825726 EngTurbo2BoostPress 1;
BA_ "SPN" SG_ 2566825726 EngTurbo2BoostPress 1128;
BA_ "SAEDocument" SG_ 2566825726 EngTurbo2BoostPress "J1939-71";
BA_ "SigType" SG_ 2566825726 EngTurbo1BoostPress 1;
BA_ "SPN" SG_ 2566825726 EngTurbo1BoostPress 1127;
BA_ "SAEDocument" SG_ 2566825726 EngTurbo1BoostPress "J1939-71";
BA_ "SigType" SG_ 2566770942 EngIntakeManifold2AbsPress 1;
BA_ "SPN" SG_ 2566770942 EngIntakeManifold2AbsPress 5422;
BA_ "SAEDocument" SG_ 2566770942 EngIntakeManifold2AbsPress "J1939-71";
BA_ "SigType" SG_ 2566770942 EngIntakeManifold1AbsPress 1;
BA_ "SPN" SG_ 2566770942 EngIntakeManifold1AbsPress 3563;
BA_ "SAEDocument" SG_ 2566770942 EngIntakeManifold1AbsPress "J1939-71";
BA_ "SigType" SG_ 2566770942 EngIntakeManifold2Press 1;
BA_ "SPN" SG_ 2566770942 EngIntakeManifold2Press 3562;
BA_ "SAEDocument" SG_ 2566770942 EngIntakeManifold2Press "J1939-71";
BA_ "SigType" SG_ 2566770942 EngAirFilter4DiffPress 1;
BA_ "SPN" SG_ 2566770942 EngAirFilter4DiffPress 2811;
BA_ "SAEDocument" SG_ 2566770942 EngAirFilter4DiffPress "J1939-71";
BA_ "SigType" SG_ 2566770942 EngAirFilter3DiffPress 1;
BA_ "SPN" SG_ 2566770942 EngAirFilter3DiffPress 2810;
BA_ "SAEDocument" SG_ 2566770942 EngAirFilter3DiffPress "J1939-71";
BA_ "SigType" SG_ 2566770942 EngAirFilter2DiffPress 1;
BA_ "SPN" SG_ 2566770942 EngAirFilter2DiffPress 2809;
BA_ "SAEDocument" SG_ 2566770942 EngAirFilter2DiffPress "J1939-71";
BA_ "SigType" SG_ 2566846206 EngCoolantFilterDiffPress 1;
BA_ "SPN" SG_ 2566846206 EngCoolantFilterDiffPress 112;
BA_ "SAEDocument" SG_ 2566846206 EngCoolantFilterDiffPress "J1939-71";
BA_ "SigType" SG_ 2566846206 EngExhaustGasTemp 1;
BA_ "SPN" SG_ 2566846206 EngExhaustGasTemp 173;
BA_ "SAEDocument" SG_ 2566846206 EngExhaustGasTemp "J1939-71";
BA_ "SigType" SG_ 2566846206 EngAirFilter1DiffPress 1;
BA_ "SPN" SG_ 2566846206 EngAirFilter1DiffPress 107;
BA_ "SAEDocument" SG_ 2566846206 EngAirFilter1DiffPress "J1939-71";
BA_ "SigType" SG_ 2566846206 EngIntakeManifold1Temp 1;
BA_ "SPN" SG_ 2566846206 EngIntakeManifold1Temp 105;
BA_ "SAEDocument" SG_ 2566846206 EngIntakeManifold1Temp "J1939-71";
BA_ "SigType" SG_ 2566846206 EngIntakeManifold1Press 1;
BA_ "SPN" SG_ 2566846206 EngIntakeManifold1Press 102;
BA_ "SAEDocument" SG_ 2566846206 EngIntakeManifold1Press "J1939-71";
BA_ "SigType" SG_ 2566846206 EngDslPrtculateFilterIntakePress 1;
BA_ "SPN" SG_ 2566846206 EngDslPrtculateFilterIntakePress 81;
BA_ "SAEDocument" SG_ 2566846206 EngDslPrtculateFilterIntakePress "J1939-71";
BA_ "SigType" SG_ 2566846206 EngAirIntakePress 1;
BA_ "SPN" SG_ 2566846206 EngAirIntakePress 106;
BA_ "SAEDocument" SG_ 2566846206 EngAirIntakePress "J1939-71";
BA_ "SigType" SG_ 2566811134 CabHeatingZone 5;
BA_ "SPN" SG_ 2566811134 CabHeatingZone 1680;
BA_ "SAEDocument" SG_ 2566811134 CabHeatingZone "J1939-71";
BA_ "SigType" SG_ 2566811134 EngHeatingZone 5;
BA_ "SPN" SG_ 2566811134 EngHeatingZone 1679;
BA_ "SAEDocument" SG_ 2566811134 EngHeatingZone "J1939-71";
BA_ "SigType" SG_ 2566811134 CabVentilation 5;
BA_ "SPN" SG_ 2566811134 CabVentilation 1678;
BA_ "SAEDocument" SG_ 2566811134 CabVentilation "J1939-71";
BA_ "SigType" SG_ 2566811134 AuxHeaterWaterPumpStatus 5;
BA_ "SPN" SG_ 2566811134 AuxHeaterWaterPumpStatus 1676;
BA_ "SAEDocument" SG_ 2566811134 AuxHeaterWaterPumpStatus "J1939-71";
BA_ "SPN" SG_ 2566811134 AuxHeaterMode 1677;
BA_ "SAEDocument" SG_ 2566811134 AuxHeaterMode "J1939-71";
BA_ "SigType" SG_ 2566811134 AuxHeaterOutputPowerPercent 1;
BA_ "SPN" SG_ 2566811134 AuxHeaterOutputPowerPercent 1689;
BA_ "SAEDocument" SG_ 2566811134 AuxHeaterOutputPowerPercent "J1939-71";
BA_ "SigType" SG_ 2566811134 AuxHeaterInputAirTemp 1;
BA_ "SPN" SG_ 2566811134 AuxHeaterInputAirTemp 1688;
BA_ "SAEDocument" SG_ 2566811134 AuxHeaterInputAirTemp "J1939-71";
BA_ "SigType" SG_ 2566811134 AuxHeaterOutputCoolantTemp 1;
BA_ "SPN" SG_ 2566811134 AuxHeaterOutputCoolantTemp 1687;
BA_ "SAEDocument" SG_ 2566811134 AuxHeaterOutputCoolantTemp "J1939-71";
BA_ "SigType" SG_ 2298375934 RearAxleRightWheelSpeed 1;
BA_ "SPN" SG_ 2298375934 RearAxleRightWheelSpeed 1595;
BA_ "SAEDocument" SG_ 2298375934 RearAxleRightWheelSpeed "J1939-71";
BA_ "SigType" SG_ 2298375934 RearAxleLeftWheelSpeed 1;
BA_ "SPN" SG_ 2298375934 RearAxleLeftWheelSpeed 1594;
BA_ "SAEDocument" SG_ 2298375934 RearAxleLeftWheelSpeed "J1939-71";
BA_ "SigType" SG_ 2298375934 FrontAxleRightWheelSpeed 1;
BA_ "SPN" SG_ 2298375934 FrontAxleRightWheelSpeed 1593;
BA_ "SAEDocument" SG_ 2298375934 FrontAxleRightWheelSpeed "J1939-71";
BA_ "SigType" SG_ 2298375934 FrontAxleLeftWheelSpeed 1;
BA_ "SPN" SG_ 2298375934 FrontAxleLeftWheelSpeed 1592;
BA_ "SAEDocument" SG_ 2298375934 FrontAxleLeftWheelSpeed "J1939-71";
BA_ "SigType" SG_ 2565867774 FireApparatusPumpEngagement 4;
BA_ "SPN" SG_ 2565867774 FireApparatusPumpEngagement 2599;
BA_ "SAEDocument" SG_ 2565867774 FireApparatusPumpEngagement "J1939-71";
BA_ "SigType" SG_ 2565867774 EngHydPressGovernorSwitch 4;
BA_ "SPN" SG_ 2565867774 EngHydPressGovernorSwitch 1764;
BA_ "SAEDocument" SG_ 2565867774 EngHydPressGovernorSwitch "J1939-71";
BA_ "SigType" SG_ 2565867774 EngHydPressGovernorModeIndicator 5;
BA_ "SPN" SG_ 2565867774 EngHydPressGovernorModeIndicator 1763;
BA_ "SAEDocument" SG_ 2565867774 EngHydPressGovernorModeIndicator "J1939-71";
BA_ "SigType" SG_ 2565867774 HydPress 1;
BA_ "SPN" SG_ 2565867774 HydPress 1762;
BA_ "SAEDocument" SG_ 2565867774 HydPress "J1939-71";
BA_ "SigType" SG_ 2566841854 EngTotalRevolutions 1;
BA_ "SPN" SG_ 2566841854 EngTotalRevolutions 249;
BA_ "SAEDocument" SG_ 2566841854 EngTotalRevolutions "J1939-71";
BA_ "SigType" SG_ 2566841854 EngTotalHoursOfOperation 1;
BA_ "SPN" SG_ 2566841854 EngTotalHoursOfOperation 247;
BA_ "SAEDocument" SG_ 2566841854 EngTotalHoursOfOperation "J1939-71";
BA_ "SigType" SG_ 2365449982 HydBrakeFluidLevelSwitch 4;
BA_ "SPN" SG_ 2365449982 HydBrakeFluidLevelSwitch 2931;
BA_ "SAEDocument" SG_ 2365449982 HydBrakeFluidLevelSwitch "J1939-71";
BA_ "SigType" SG_ 2365449982 HydBrakeSystemAudibleWarningCmd 5;
BA_ "SPN" SG_ 2365449982 HydBrakeSystemAudibleWarningCmd 2930;
BA_ "SAEDocument" SG_ 2365449982 HydBrakeSystemAudibleWarningCmd "J1939-71";
BA_ "SigType" SG_ 2365449982 HydBrakePressSupplyStateCircuit2 4;
BA_ "SPN" SG_ 2365449982 HydBrakePressSupplyStateCircuit2 2583;
BA_ "SAEDocument" SG_ 2365449982 HydBrakePressSupplyStateCircuit2 "J1939-71";
BA_ "SigType" SG_ 2365449982 HydBrakePressSupplyStateCircuit1 4;
BA_ "SPN" SG_ 2365449982 HydBrakePressSupplyStateCircuit1 2582;
BA_ "SAEDocument" SG_ 2365449982 HydBrakePressSupplyStateCircuit1 "J1939-71";
BA_ "SigType" SG_ 2365449982 HydBrkePressWarningStateCircuit2 4;
BA_ "SPN" SG_ 2365449982 HydBrkePressWarningStateCircuit2 2585;
BA_ "SAEDocument" SG_ 2365449982 HydBrkePressWarningStateCircuit2 "J1939-71";
BA_ "SigType" SG_ 2365449982 HydBrkePressWarningStateCircuit1 4;
BA_ "SPN" SG_ 2365449982 HydBrkePressWarningStateCircuit1 2584;
BA_ "SAEDocument" SG_ 2365449982 HydBrkePressWarningStateCircuit1 "J1939-71";
BA_ "SigType" SG_ 2365449982 HydBrakePressCircuit2 1;
BA_ "SPN" SG_ 2365449982 HydBrakePressCircuit2 2581;
BA_ "SAEDocument" SG_ 2365449982 HydBrakePressCircuit2 "J1939-71";
BA_ "SigType" SG_ 2365449982 HydBrakePressCircuit1 1;
BA_ "SPN" SG_ 2365449982 HydBrakePressCircuit1 2580;
BA_ "SAEDocument" SG_ 2365449982 HydBrakePressCircuit1 "J1939-71";
BA_ "SigType" SG_ 2633939198 TripDriveFuelEconomy 1;
BA_ "SPN" SG_ 2633939198 TripDriveFuelEconomy 1012;
BA_ "SAEDocument" SG_ 2633939198 TripDriveFuelEconomy "J1939-71";
BA_ "SigType" SG_ 2633939198 TripCruiseFuelUsed 1;
BA_ "SPN" SG_ 2633939198 TripCruiseFuelUsed 1011;
BA_ "SAEDocument" SG_ 2633939198 TripCruiseFuelUsed "J1939-71";
BA_ "SigType" SG_ 2633939198 TripVehicleIdleFuelUsed 1;
BA_ "SPN" SG_ 2633939198 TripVehicleIdleFuelUsed 1010;
BA_ "SAEDocument" SG_ 2633939198 TripVehicleIdleFuelUsed "J1939-71";
BA_ "SigType" SG_ 2633939198 TripPTOGovernorNonmovingFuelUsed 1;
BA_ "SPN" SG_ 2633939198 TripPTOGovernorNonmovingFuelUsed 1009;
BA_ "SAEDocument" SG_ 2633939198 TripPTOGovernorNonmovingFuelUsed "J1939-71";
BA_ "SigType" SG_ 2633939198 TripPTOGovernorMovingFuelUsed 1;
BA_ "SPN" SG_ 2633939198 TripPTOGovernorMovingFuelUsed 1008;
BA_ "SAEDocument" SG_ 2633939198 TripPTOGovernorMovingFuelUsed "J1939-71";
BA_ "SigType" SG_ 2633939198 TripDriveFuelUsed 1;
BA_ "SPN" SG_ 2633939198 TripDriveFuelUsed 1007;
BA_ "SAEDocument" SG_ 2633939198 TripDriveFuelUsed "J1939-71";
BA_ "SigType" SG_ 2633927678 EngFuelValve1OutletAbsPress 1;
BA_ "SPN" SG_ 2633927678 EngFuelValve1OutletAbsPress 2980;
BA_ "SAEDocument" SG_ 2633927678 EngFuelValve1OutletAbsPress "J1939-71";
BA_ "SigType" SG_ 2633927678 EngAirToFuelDiffPress 1;
BA_ "SPN" SG_ 2633927678 EngAirToFuelDiffPress 1392;
BA_ "SAEDocument" SG_ 2633927678 EngAirToFuelDiffPress "J1939-71";
BA_ "SigType" SG_ 2633927678 EngFuelValveDiffPress 1;
BA_ "SPN" SG_ 2633927678 EngFuelValveDiffPress 1391;
BA_ "SAEDocument" SG_ 2633927678 EngFuelValveDiffPress "J1939-71";
BA_ "SigType" SG_ 2633927678 EngFuelValve1IntakeAbsPress 1;
BA_ "SPN" SG_ 2633927678 EngFuelValve1IntakeAbsPress 1390;
BA_ "SAEDocument" SG_ 2633927678 EngFuelValve1IntakeAbsPress "J1939-71";
BA_ "SPN" SG_ 2633925118 EngRequestedFuelValve2Pos 1766;
BA_ "SAEDocument" SG_ 2633925118 EngRequestedFuelValve2Pos "J1939-71";
BA_ "SPN" SG_ 2633925118 EngRequestedFuelValve1Pos 1765;
BA_ "SAEDocument" SG_ 2633925118 EngRequestedFuelValve1Pos "J1939-71";
BA_ "SigType" SG_ 2633925118 EngFuelValve2Pos 1;
BA_ "SPN" SG_ 2633925118 EngFuelValve2Pos 1443;
BA_ "SAEDocument" SG_ 2633925118 EngFuelValve2Pos "J1939-71";
BA_ "SigType" SG_ 2633925118 EngFuelValve1Pos 1;
BA_ "SPN" SG_ 2633925118 EngFuelValve1Pos 1442;
BA_ "SAEDocument" SG_ 2633925118 EngFuelValve1Pos "J1939-71";
BA_ "SigType" SG_ 2633925118 EngFuelFlowRate2 1;
BA_ "SPN" SG_ 2633925118 EngFuelFlowRate2 1441;
BA_ "SAEDocument" SG_ 2633925118 EngFuelFlowRate2 "J1939-71";
BA_ "SigType" SG_ 2633925118 EngFuelFlowRate1 1;
BA_ "SPN" SG_ 2633925118 EngFuelFlowRate1 1440;
BA_ "SAEDocument" SG_ 2633925118 EngFuelFlowRate1 "J1939-71";
BA_ "SPN" SG_ 2633937662 EngFuelSpecificGravity 1389;
BA_ "SAEDocument" SG_ 2633937662 EngFuelSpecificGravity "J1939-71";
BA_ "SigType" SG_ 2633937662 TripAverageFuelRate 1;
BA_ "SPN" SG_ 2633937662 TripAverageFuelRate 1031;
BA_ "SAEDocument" SG_ 2633937662 TripAverageFuelRate "J1939-71";
BA_ "SigType" SG_ 2633937662 TotalEngPTOGovernorFuelUsed 1;
BA_ "SPN" SG_ 2633937662 TotalEngPTOGovernorFuelUsed 1030;
BA_ "SAEDocument" SG_ 2633937662 TotalEngPTOGovernorFuelUsed "J1939-71";
BA_ "SPN" SG_ 2566804990 SpecificHeatRatio 1767;
BA_ "SAEDocument" SG_ 2566804990 SpecificHeatRatio "J1939-71";
BA_ "SigType" SG_ 2633936894 TotalFuelUsed 1;
BA_ "SPN" SG_ 2633936894 TotalFuelUsed 1040;
BA_ "SAEDocument" SG_ 2633936894 TotalFuelUsed "J1939-71";
BA_ "SigType" SG_ 2633936894 TripFuel 1;
BA_ "SPN" SG_ 2633936894 TripFuel 1039;
BA_ "SAEDocument" SG_ 2633936894 TripFuel "J1939-71";
BA_ "SigType" SG_ 2566757630 SensorSupplyVoltage6 1;
BA_ "SPN" SG_ 2566757630 SensorSupplyVoltage6 3514;
BA_ "SAEDocument" SG_ 2566757630 SensorSupplyVoltage6 "J1939-71";
BA_ "SigType" SG_ 2566757630 SensorSupplyVoltage5 1;
BA_ "SPN" SG_ 2566757630 SensorSupplyVoltage5 3513;
BA_ "SAEDocument" SG_ 2566757630 SensorSupplyVoltage5 "J1939-71";
BA_ "SigType" SG_ 2566757630 SensorSupplyVoltage8 1;
BA_ "SPN" SG_ 2566757630 SensorSupplyVoltage8 5126;
BA_ "SAEDocument" SG_ 2566757630 SensorSupplyVoltage8 "J1939-71";
BA_ "SigType" SG_ 2566757630 SensorSupplyVoltage7 1;
BA_ "SPN" SG_ 2566757630 SensorSupplyVoltage7 5125;
BA_ "SAEDocument" SG_ 2566757630 SensorSupplyVoltage7 "J1939-71";
BA_ "SigType" SG_ 2566757886 SensorSupplyVoltage4 1;
BA_ "SPN" SG_ 2566757886 SensorSupplyVoltage4 3512;
BA_ "SAEDocument" SG_ 2566757886 SensorSupplyVoltage4 "J1939-71";
BA_ "SigType" SG_ 2566757886 SensorSupplyVoltage3 1;
BA_ "SPN" SG_ 2566757886 SensorSupplyVoltage3 3511;
BA_ "SAEDocument" SG_ 2566757886 SensorSupplyVoltage3 "J1939-71";
BA_ "SigType" SG_ 2566757886 SensorSupplyVoltage2 1;
BA_ "SPN" SG_ 2566757886 SensorSupplyVoltage2 3510;
BA_ "SAEDocument" SG_ 2566757886 SensorSupplyVoltage2 "J1939-71";
BA_ "SigType" SG_ 2566757886 SensorSupplyVoltage1 1;
BA_ "SPN" SG_ 2566757886 SensorSupplyVoltage1 3509;
BA_ "SAEDocument" SG_ 2566757886 SensorSupplyVoltage1 "J1939-71";
BA_ "SigType" SG_ 2566759678 AtLeastOnePTOEngaged 5;
BA_ "SPN" SG_ 2566759678 AtLeastOnePTOEngaged 3948;
BA_ "SAEDocument" SG_ 2566759678 AtLeastOnePTOEngaged "J1939-71";
BA_ "SigType" SG_ 2566759678 EnggmntSttsPTOEngAccessoryDrive2 5;
BA_ "SPN" SG_ 2566759678 EnggmntSttsPTOEngAccessoryDrive2 3947;
BA_ "SAEDocument" SG_ 2566759678 EnggmntSttsPTOEngAccessoryDrive2 "J1939-71";
BA_ "SigType" SG_ 2566759678 EnggmntSttsPTOEngAccessoryDrive1 5;
BA_ "SPN" SG_ 2566759678 EnggmntSttsPTOEngAccessoryDrive1 3944;
BA_ "SAEDocument" SG_ 2566759678 EnggmntSttsPTOEngAccessoryDrive1 "J1939-71";
BA_ "SigType" SG_ 2566759678 EngagementStatusPTOEngFlywheel 5;
BA_ "SPN" SG_ 2566759678 EngagementStatusPTOEngFlywheel 3941;
BA_ "SAEDocument" SG_ 2566759678 EngagementStatusPTOEngFlywheel "J1939-71";
BA_ "SigType" SG_ 2566759678 EnggmntStatusTransInputShaftPTO1 5;
BA_ "SPN" SG_ 2566759678 EnggmntStatusTransInputShaftPTO1 3460;
BA_ "SAEDocument" SG_ 2566759678 EnggmntStatusTransInputShaftPTO1 "J1939-71";
BA_ "SigType" SG_ 2566759678 EnggmntStatusTransInputShaftPTO2 5;
BA_ "SPN" SG_ 2566759678 EnggmntStatusTransInputShaftPTO2 3461;
BA_ "SAEDocument" SG_ 2566759678 EnggmntStatusTransInputShaftPTO2 "J1939-71";
BA_ "SigType" SG_ 2566759678 EnggmntStatusTransOutputShaftPTO 5;
BA_ "SPN" SG_ 2566759678 EnggmntStatusTransOutputShaftPTO 3462;
BA_ "SAEDocument" SG_ 2566759678 EnggmntStatusTransOutputShaftPTO "J1939-71";
BA_ "SigType" SG_ 2566759678 EnggmntSttsTrnsfrCsOtputShaftPTO 5;
BA_ "SPN" SG_ 2566759678 EnggmntSttsTrnsfrCsOtputShaftPTO 3463;
BA_ "SAEDocument" SG_ 2566759678 EnggmntSttsTrnsfrCsOtputShaftPTO "J1939-71";
BA_ "SigType" SG_ 2566759678 EnggmntCnsntPTOEngAccssoryDrive2 5;
BA_ "SPN" SG_ 2566759678 EnggmntCnsntPTOEngAccssoryDrive2 3946;
BA_ "SAEDocument" SG_ 2566759678 EnggmntCnsntPTOEngAccssoryDrive2 "J1939-71";
BA_ "SigType" SG_ 2566759678 EnggmntCnsntPTOEngAccssoryDrive1 5;
BA_ "SPN" SG_ 2566759678 EnggmntCnsntPTOEngAccssoryDrive1 3943;
BA_ "SAEDocument" SG_ 2566759678 EnggmntCnsntPTOEngAccssoryDrive1 "J1939-71";
BA_ "SigType" SG_ 2566759678 EngagementConsentPTOEngFlywheel 5;
BA_ "SPN" SG_ 2566759678 EngagementConsentPTOEngFlywheel 3940;
BA_ "SAEDocument" SG_ 2566759678 EngagementConsentPTOEngFlywheel "J1939-71";
BA_ "SigType" SG_ 2566759678 EnggmntCnsentTransInputShaftPTO1 5;
BA_ "SPN" SG_ 2566759678 EnggmntCnsentTransInputShaftPTO1 3456;
BA_ "SAEDocument" SG_ 2566759678 EnggmntCnsentTransInputShaftPTO1 "J1939-71";
BA_ "SigType" SG_ 2566759678 EnggmntCnsentTransInputShaftPTO2 5;
BA_ "SPN" SG_ 2566759678 EnggmntCnsentTransInputShaftPTO2 3457;
BA_ "SAEDocument" SG_ 2566759678 EnggmntCnsentTransInputShaftPTO2 "J1939-71";
BA_ "SigType" SG_ 2566759678 EnggmntCnsentTransOutputShaftPTO 5;
BA_ "SPN" SG_ 2566759678 EnggmntCnsentTransOutputShaftPTO 3458;
BA_ "SAEDocument" SG_ 2566759678 EnggmntCnsentTransOutputShaftPTO "J1939-71";
BA_ "SigType" SG_ 2566759678 EnggmntCnsntTrnsfrCsOtptShaftPTO 5;
BA_ "SPN" SG_ 2566759678 EnggmntCnsntTrnsfrCsOtptShaftPTO 3459;
BA_ "SAEDocument" SG_ 2566759678 EnggmntCnsntTrnsfrCsOtptShaftPTO "J1939-71";
BA_ "SigType" SG_ 2566759678 EnbleSwitchPTOEngAccessoryDrive2 5;
BA_ "SPN" SG_ 2566759678 EnbleSwitchPTOEngAccessoryDrive2 3945;
BA_ "SAEDocument" SG_ 2566759678 EnbleSwitchPTOEngAccessoryDrive2 "J1939-71";
BA_ "SigType" SG_ 2566759678 EnbleSwitchPTOEngAccessoryDrive1 5;
BA_ "SPN" SG_ 2566759678 EnbleSwitchPTOEngAccessoryDrive1 3942;
BA_ "SAEDocument" SG_ 2566759678 EnbleSwitchPTOEngAccessoryDrive1 "J1939-71";
BA_ "SigType" SG_ 2566759678 EnableSwitchPTOEngFlywheel 5;
BA_ "SPN" SG_ 2566759678 EnableSwitchPTOEngFlywheel 3939;
BA_ "SAEDocument" SG_ 2566759678 EnableSwitchPTOEngFlywheel "J1939-71";
BA_ "SigType" SG_ 2566759678 EnableSwitchTransInputShaftPTO1 5;
BA_ "SPN" SG_ 2566759678 EnableSwitchTransInputShaftPTO1 3452;
BA_ "SAEDocument" SG_ 2566759678 EnableSwitchTransInputShaftPTO1 "J1939-71";
BA_ "SigType" SG_ 2566759678 EnableSwitchTransInputShaftPTO2 5;
BA_ "SPN" SG_ 2566759678 EnableSwitchTransInputShaftPTO2 3453;
BA_ "SAEDocument" SG_ 2566759678 EnableSwitchTransInputShaftPTO2 "J1939-71";
BA_ "SigType" SG_ 2566759678 EnableSwitchTransOutputShaftPTO 5;
BA_ "SPN" SG_ 2566759678 EnableSwitchTransOutputShaftPTO 3454;
BA_ "SAEDocument" SG_ 2566759678 EnableSwitchTransOutputShaftPTO "J1939-71";
BA_ "SigType" SG_ 2566759678 EnblSwtchTrnsfrCseOutputShaftPTO 5;
BA_ "SPN" SG_ 2566759678 EnblSwtchTrnsfrCseOutputShaftPTO 3455;
BA_ "SAEDocument" SG_ 2566759678 EnblSwtchTrnsfrCseOutputShaftPTO "J1939-71";
BA_ "SigType" SG_ 2432541438 EngFuelValve2OutletAbsPress 1;
BA_ "SPN" SG_ 2432541438 EngFuelValve2OutletAbsPress 3469;
BA_ "SAEDocument" SG_ 2432541438 EngFuelValve2OutletAbsPress "J1939-71";
BA_ "SigType" SG_ 2432541438 EngFuelTemp2 1;
BA_ "SPN" SG_ 2432541438 EngFuelTemp2 3468;
BA_ "SAEDocument" SG_ 2432541438 EngFuelTemp2 "J1939-71";
BA_ "SigType" SG_ 2432541438 EngGas2MassFlowRate 1;
BA_ "SPN" SG_ 2432541438 EngGas2MassFlowRate 3467;
BA_ "SAEDocument" SG_ 2432541438 EngGas2MassFlowRate "J1939-71";
BA_ "SigType" SG_ 2432541438 EngFuelValve2IntakeAbsPress 1;
BA_ "SPN" SG_ 2432541438 EngFuelValve2IntakeAbsPress 3466;
BA_ "SAEDocument" SG_ 2432541438 EngFuelValve2IntakeAbsPress "J1939-71";
BA_ "SigType" SG_ 2566761214 EngCentrifugalOilFilterSpeed 1;
BA_ "SPN" SG_ 2566761214 EngCentrifugalOilFilterSpeed 3343;
BA_ "SAEDocument" SG_ 2566761214 EngCentrifugalOilFilterSpeed "J1939-71";
BA_ "SigType" SG_ 2566761214 EngCoolantPumpDiffPress 1;
BA_ "SPN" SG_ 2566761214 EngCoolantPumpDiffPress 3342;
BA_ "SAEDocument" SG_ 2566761214 EngCoolantPumpDiffPress "J1939-71";
BA_ "SigType" SG_ 2566761214 EngChargeAirCooler2IntakePress 1;
BA_ "SPN" SG_ 2566761214 EngChargeAirCooler2IntakePress 3341;
BA_ "SAEDocument" SG_ 2566761214 EngChargeAirCooler2IntakePress "J1939-71";
BA_ "SigType" SG_ 2566761214 EngChargeAirCooler1IntakePress 1;
BA_ "SPN" SG_ 2566761214 EngChargeAirCooler1IntakePress 3340;
BA_ "SAEDocument" SG_ 2566761214 EngChargeAirCooler1IntakePress "J1939-71";
BA_ "SigType" SG_ 2566761214 EngIntercoolerCoolantLevel 1;
BA_ "SPN" SG_ 2566761214 EngIntercoolerCoolantLevel 3668;
BA_ "SAEDocument" SG_ 2566761214 EngIntercoolerCoolantLevel "J1939-71";
BA_ "SigType" SG_ 2566761214 EngChargeAirCoolerOutletPress 1;
BA_ "SPN" SG_ 2566761214 EngChargeAirCoolerOutletPress 2631;
BA_ "SAEDocument" SG_ 2566761214 EngChargeAirCoolerOutletPress "J1939-71";
BA_ "SigType" SG_ 2566761214 EngAftercoolerCoolantLevel 1;
BA_ "SPN" SG_ 2566761214 EngAftercoolerCoolantLevel 3676;
BA_ "SAEDocument" SG_ 2566761214 EngAftercoolerCoolantLevel "J1939-71";
BA_ "SPN" SG_ 2432541694 EngVriableGeometryTurboActuator1 641;
BA_ "SAEDocument" SG_ 2432541694 EngVriableGeometryTurboActuator1 "J1939-71";
BA_ "SPN" SG_ 2432541694 EngTrbCmprssrBypssActtr1TmpSttus 5368;
BA_ "SAEDocument" SG_ 2432541694 EngTrbCmprssrBypssActtr1TmpSttus "J1939-71";
BA_ "SPN" SG_ 2432541694 EngTrbCmprssrBypssActtr1PrlmnryF 5367;
BA_ "SAEDocument" SG_ 2432541694 EngTrbCmprssrBypssActtr1PrlmnryF "J1939-71";
BA_ "SPN" SG_ 2432541694 EngTrbCmprssorBypassActuator2Cmd 5369;
BA_ "SAEDocument" SG_ 2432541694 EngTrbCmprssorBypassActuator2Cmd "J1939-71";
BA_ "SigType" SG_ 2432541694 EngTrbCmprssorBypassActuator1Pos 1;
BA_ "SPN" SG_ 2432541694 EngTrbCmprssorBypassActuator1Pos 3675;
BA_ "SAEDocument" SG_ 2432541694 EngTrbCmprssorBypassActuator1Pos "J1939-71";
BA_ "SPN" SG_ 2432541694 EngTrbCmprssorBypassActuator1Cmd 3470;
BA_ "SAEDocument" SG_ 2432541694 EngTrbCmprssorBypassActuator1Cmd "J1939-71";
BA_ "SigType" SG_ 2432541694 EngDsrdTrbCmprssrBypssActtor1Pos 1;
BA_ "SPN" SG_ 2432541694 EngDsrdTrbCmprssrBypssActtor1Pos 5366;
BA_ "SAEDocument" SG_ 2432541694 EngDsrdTrbCmprssrBypssActtor1Pos "J1939-71";
BA_ "SigType" SG_ 2566759934 EnableStatusOfDoor10 4;
BA_ "SPN" SG_ 2566759934 EnableStatusOfDoor10 3441;
BA_ "SAEDocument" SG_ 2566759934 EnableStatusOfDoor10 "J1939-71";
BA_ "SigType" SG_ 2566759934 OpenStatusOfDoor10 4;
BA_ "SPN" SG_ 2566759934 OpenStatusOfDoor10 3440;
BA_ "SAEDocument" SG_ 2566759934 OpenStatusOfDoor10 "J1939-71";
BA_ "SigType" SG_ 2566759934 LockStatusOfDoor10 4;
BA_ "SPN" SG_ 2566759934 LockStatusOfDoor10 3439;
BA_ "SAEDocument" SG_ 2566759934 LockStatusOfDoor10 "J1939-71";
BA_ "SigType" SG_ 2566759934 EnableStatusOfDoor9 4;
BA_ "SPN" SG_ 2566759934 EnableStatusOfDoor9 3438;
BA_ "SAEDocument" SG_ 2566759934 EnableStatusOfDoor9 "J1939-71";
BA_ "SigType" SG_ 2566759934 OpenStatusOfDoor9 4;
BA_ "SPN" SG_ 2566759934 OpenStatusOfDoor9 3437;
BA_ "SAEDocument" SG_ 2566759934 OpenStatusOfDoor9 "J1939-71";
BA_ "SigType" SG_ 2566759934 LockStatusOfDoor9 4;
BA_ "SPN" SG_ 2566759934 LockStatusOfDoor9 3436;
BA_ "SAEDocument" SG_ 2566759934 LockStatusOfDoor9 "J1939-71";
BA_ "SigType" SG_ 2566759934 EnableStatusOfDoor8 4;
BA_ "SPN" SG_ 2566759934 EnableStatusOfDoor8 3435;
BA_ "SAEDocument" SG_ 2566759934 EnableStatusOfDoor8 "J1939-71";
BA_ "SigType" SG_ 2566759934 OpenStatusOfDoor8 4;
BA_ "SPN" SG_ 2566759934 OpenStatusOfDoor8 3434;
BA_ "SAEDocument" SG_ 2566759934 OpenStatusOfDoor8 "J1939-71";
BA_ "SigType" SG_ 2566759934 LockStatusOfDoor8 4;
BA_ "SPN" SG_ 2566759934 LockStatusOfDoor8 3433;
BA_ "SAEDocument" SG_ 2566759934 LockStatusOfDoor8 "J1939-71";
BA_ "SigType" SG_ 2566759934 EnableStatusOfDoor7 4;
BA_ "SPN" SG_ 2566759934 EnableStatusOfDoor7 3432;
BA_ "SAEDocument" SG_ 2566759934 EnableStatusOfDoor7 "J1939-71";
BA_ "SigType" SG_ 2566759934 OpenStatusOfDoor7 4;
BA_ "SPN" SG_ 2566759934 OpenStatusOfDoor7 3431;
BA_ "SAEDocument" SG_ 2566759934 OpenStatusOfDoor7 "J1939-71";
BA_ "SigType" SG_ 2566759934 LockStatusOfDoor7 4;
BA_ "SPN" SG_ 2566759934 LockStatusOfDoor7 3430;
BA_ "SAEDocument" SG_ 2566759934 LockStatusOfDoor7 "J1939-71";
BA_ "SigType" SG_ 2566759934 EnableStatusOfDoor6 4;
BA_ "SPN" SG_ 2566759934 EnableStatusOfDoor6 3429;
BA_ "SAEDocument" SG_ 2566759934 EnableStatusOfDoor6 "J1939-71";
BA_ "SigType" SG_ 2566759934 OpenStatusOfDoor6 4;
BA_ "SPN" SG_ 2566759934 OpenStatusOfDoor6 3428;
BA_ "SAEDocument" SG_ 2566759934 OpenStatusOfDoor6 "J1939-71";
BA_ "SigType" SG_ 2566759934 LockStatusOfDoor6 4;
BA_ "SPN" SG_ 2566759934 LockStatusOfDoor6 3427;
BA_ "SAEDocument" SG_ 2566759934 LockStatusOfDoor6 "J1939-71";
BA_ "SigType" SG_ 2566759934 EnableStatusOfDoor5 4;
BA_ "SPN" SG_ 2566759934 EnableStatusOfDoor5 3426;
BA_ "SAEDocument" SG_ 2566759934 EnableStatusOfDoor5 "J1939-71";
BA_ "SigType" SG_ 2566759934 OpenStatusOfDoor5 4;
BA_ "SPN" SG_ 2566759934 OpenStatusOfDoor5 3425;
BA_ "SAEDocument" SG_ 2566759934 OpenStatusOfDoor5 "J1939-71";
BA_ "SigType" SG_ 2566759934 LockStatusOfDoor5 4;
BA_ "SPN" SG_ 2566759934 LockStatusOfDoor5 3424;
BA_ "SAEDocument" SG_ 2566759934 LockStatusOfDoor5 "J1939-71";
BA_ "SigType" SG_ 2566759934 EnableStatusOfDoor4 4;
BA_ "SPN" SG_ 2566759934 EnableStatusOfDoor4 3423;
BA_ "SAEDocument" SG_ 2566759934 EnableStatusOfDoor4 "J1939-71";
BA_ "SigType" SG_ 2566759934 OpenStatusOfDoor4 4;
BA_ "SPN" SG_ 2566759934 OpenStatusOfDoor4 3422;
BA_ "SAEDocument" SG_ 2566759934 OpenStatusOfDoor4 "J1939-71";
BA_ "SigType" SG_ 2566759934 LockStatusOfDoor4 4;
BA_ "SPN" SG_ 2566759934 LockStatusOfDoor4 3421;
BA_ "SAEDocument" SG_ 2566759934 LockStatusOfDoor4 "J1939-71";
BA_ "SigType" SG_ 2566759934 EnableStatusOfDoor3 4;
BA_ "SPN" SG_ 2566759934 EnableStatusOfDoor3 3420;
BA_ "SAEDocument" SG_ 2566759934 EnableStatusOfDoor3 "J1939-71";
BA_ "SigType" SG_ 2566759934 OpenStatusOfDoor3 4;
BA_ "SPN" SG_ 2566759934 OpenStatusOfDoor3 3419;
BA_ "SAEDocument" SG_ 2566759934 OpenStatusOfDoor3 "J1939-71";
BA_ "SigType" SG_ 2566759934 LockStatusOfDoor3 4;
BA_ "SPN" SG_ 2566759934 LockStatusOfDoor3 3418;
BA_ "SAEDocument" SG_ 2566759934 LockStatusOfDoor3 "J1939-71";
BA_ "SigType" SG_ 2566759934 EnableStatusOfDoor2 4;
BA_ "SPN" SG_ 2566759934 EnableStatusOfDoor2 3417;
BA_ "SAEDocument" SG_ 2566759934 EnableStatusOfDoor2 "J1939-71";
BA_ "SigType" SG_ 2566759934 OpenStatusOfDoor2 4;
BA_ "SPN" SG_ 2566759934 OpenStatusOfDoor2 3416;
BA_ "SAEDocument" SG_ 2566759934 OpenStatusOfDoor2 "J1939-71";
BA_ "SigType" SG_ 2566759934 LockStatusOfDoor2 4;
BA_ "SPN" SG_ 2566759934 LockStatusOfDoor2 3415;
BA_ "SAEDocument" SG_ 2566759934 LockStatusOfDoor2 "J1939-71";
BA_ "SigType" SG_ 2566759934 EnableStatusOfDoor1 4;
BA_ "SPN" SG_ 2566759934 EnableStatusOfDoor1 3414;
BA_ "SAEDocument" SG_ 2566759934 EnableStatusOfDoor1 "J1939-71";
BA_ "SigType" SG_ 2566759934 OpenStatusOfDoor1 4;
BA_ "SPN" SG_ 2566759934 OpenStatusOfDoor1 3413;
BA_ "SAEDocument" SG_ 2566759934 OpenStatusOfDoor1 "J1939-71";
BA_ "SigType" SG_ 2566759934 LockStatusOfDoor1 4;
BA_ "SPN" SG_ 2566759934 LockStatusOfDoor1 3412;
BA_ "SAEDocument" SG_ 2566759934 LockStatusOfDoor1 "J1939-71";
BA_ "SPN" SG_ 2566757374 Aftrtrtmnt1SCRCtlystRgntTmp2Prlm 3519;
BA_ "SAEDocument" SG_ 2566757374 Aftrtrtmnt1SCRCtlystRgntTmp2Prlm "J1939-71";
BA_ "SPN" SG_ 2566757374 Aftrtrtmnt1SCRCtlystRgntPrprtsPr 3520;
BA_ "SAEDocument" SG_ 2566757374 Aftrtrtmnt1SCRCtlystRgntPrprtsPr "J1939-71";
BA_ "SigType" SG_ 2566757374 Aftrtrtmnt1SCRCtlystRgntCndctvty 1;
BA_ "SPN" SG_ 2566757374 Aftrtrtmnt1SCRCtlystRgntCndctvty 3518;
BA_ "SAEDocument" SG_ 2566757374 Aftrtrtmnt1SCRCtlystRgntCndctvty "J1939-71";
BA_ "SigType" SG_ 2566757374 Aftrtrtmnt1SCRCtlystRgntCncntrtn 1;
BA_ "SPN" SG_ 2566757374 Aftrtrtmnt1SCRCtlystRgntCncntrtn 3516;
BA_ "SAEDocument" SG_ 2566757374 Aftrtrtmnt1SCRCtlystRgntCncntrtn "J1939-71";
BA_ "SPN" SG_ 2566757374 Aftrtrtmnt1SCRCtalystReagentType 3521;
BA_ "SAEDocument" SG_ 2566757374 Aftrtrtmnt1SCRCtalystReagentType "J1939-71";
BA_ "SigType" SG_ 2566757374 Aftrtrtmnt1SCRCtlystReagentTemp2 1;
BA_ "SPN" SG_ 2566757374 Aftrtrtmnt1SCRCtlystReagentTemp2 3515;
BA_ "SAEDocument" SG_ 2566757374 Aftrtrtmnt1SCRCtlystReagentTemp2 "J1939-71";
BA_ "SigType" SG_ 2364546302 RqdGnrtrAvrgLneLineACRMSVoltage 1;
BA_ "SPN" SG_ 2364546302 RqdGnrtrAvrgLneLineACRMSVoltage 3386;
BA_ "SAEDocument" SG_ 2364546302 RqdGnrtrAvrgLneLineACRMSVoltage "J1939-75";
BA_ "SPN" SG_ 2431654654 EngFuelActuator2CtrlCmd 1244;
BA_ "SAEDocument" SG_ 2431654654 EngFuelActuator2CtrlCmd "J1939-71";
BA_ "SPN" SG_ 2431654654 EngFuelActuator1CtrlCmd 633;
BA_ "SAEDocument" SG_ 2431654654 EngFuelActuator1CtrlCmd "J1939-71";
BA_ "SPN" SG_ 2431654654 EngThrottleActuator2CtrlCmd 3465;
BA_ "SAEDocument" SG_ 2431654654 EngThrottleActuator2CtrlCmd "J1939-71";
BA_ "SPN" SG_ 2431654654 EngThrottleActuator1CtrlCmd 3464;
BA_ "SAEDocument" SG_ 2431654654 EngThrottleActuator1CtrlCmd "J1939-71";
BA_ "SPN" SG_ 2364545534 EngCyl24KnockLevel 1375;
BA_ "SAEDocument" SG_ 2364545534 EngCyl24KnockLevel "J1939-71";
BA_ "SPN" SG_ 2364545534 EngCyl23KnockLevel 1374;
BA_ "SAEDocument" SG_ 2364545534 EngCyl23KnockLevel "J1939-71";
BA_ "SPN" SG_ 2364545534 EngCyl22KnockLevel 1373;
BA_ "SAEDocument" SG_ 2364545534 EngCyl22KnockLevel "J1939-71";
BA_ "SPN" SG_ 2364545534 EngCyl21KnockLevel 1372;
BA_ "SAEDocument" SG_ 2364545534 EngCyl21KnockLevel "J1939-71";
BA_ "SPN" SG_ 2364545534 EngCyl20KnockLevel 1371;
BA_ "SAEDocument" SG_ 2364545534 EngCyl20KnockLevel "J1939-71";
BA_ "SPN" SG_ 2364545534 EngCyl19KnockLevel 1370;
BA_ "SAEDocument" SG_ 2364545534 EngCyl19KnockLevel "J1939-71";
BA_ "SPN" SG_ 2364545534 EngCyl18KnockLevel 1369;
BA_ "SAEDocument" SG_ 2364545534 EngCyl18KnockLevel "J1939-71";
BA_ "SPN" SG_ 2364545534 EngCyl17KnockLevel 1368;
BA_ "SAEDocument" SG_ 2364545534 EngCyl17KnockLevel "J1939-71";
BA_ "SPN" SG_ 2364545278 EngCyl16KnockLevel 1367;
BA_ "SAEDocument" SG_ 2364545278 EngCyl16KnockLevel "J1939-71";
BA_ "SPN" SG_ 2364545278 EngCyl15KnockLevel 1366;
BA_ "SAEDocument" SG_ 2364545278 EngCyl15KnockLevel "J1939-71";
BA_ "SPN" SG_ 2364545278 EngCyl14KnockLevel 1365;
BA_ "SAEDocument" SG_ 2364545278 EngCyl14KnockLevel "J1939-71";
BA_ "SPN" SG_ 2364545278 EngCyl13KnockLevel 1364;
BA_ "SAEDocument" SG_ 2364545278 EngCyl13KnockLevel "J1939-71";
BA_ "SPN" SG_ 2364545278 EngCyl12KnockLevel 1363;
BA_ "SAEDocument" SG_ 2364545278 EngCyl12KnockLevel "J1939-71";
BA_ "SPN" SG_ 2364545278 EngCyl11KnockLevel 1362;
BA_ "SAEDocument" SG_ 2364545278 EngCyl11KnockLevel "J1939-71";
BA_ "SPN" SG_ 2364545278 EngCyl10KnockLevel 1361;
BA_ "SAEDocument" SG_ 2364545278 EngCyl10KnockLevel "J1939-71";
BA_ "SPN" SG_ 2364545278 EngCyl9KnockLevel 1360;
BA_ "SAEDocument" SG_ 2364545278 EngCyl9KnockLevel "J1939-71";
BA_ "SPN" SG_ 2364545022 EngCyl8KnockLevel 1359;
BA_ "SAEDocument" SG_ 2364545022 EngCyl8KnockLevel "J1939-71";
BA_ "SPN" SG_ 2364545022 EngCyl7KnockLevel 1358;
BA_ "SAEDocument" SG_ 2364545022 EngCyl7KnockLevel "J1939-71";
BA_ "SPN" SG_ 2364545022 EngCyl6KnockLevel 1357;
BA_ "SAEDocument" SG_ 2364545022 EngCyl6KnockLevel "J1939-71";
BA_ "SPN" SG_ 2364545022 EngCyl5KnockLevel 1356;
BA_ "SAEDocument" SG_ 2364545022 EngCyl5KnockLevel "J1939-71";
BA_ "SPN" SG_ 2364545022 EngCyl4KnockLevel 1355;
BA_ "SAEDocument" SG_ 2364545022 EngCyl4KnockLevel "J1939-71";
BA_ "SPN" SG_ 2364545022 EngCyl3KnockLevel 1354;
BA_ "SAEDocument" SG_ 2364545022 EngCyl3KnockLevel "J1939-71";
BA_ "SPN" SG_ 2364545022 EngCyl2KnockLevel 1353;
BA_ "SAEDocument" SG_ 2364545022 EngCyl2KnockLevel "J1939-71";
BA_ "SPN" SG_ 2364545022 EngCyl1KnockLevel 1352;
BA_ "SAEDocument" SG_ 2364545022 EngCyl1KnockLevel "J1939-71";
BA_ "SigType" SG_ 2364544766 EngCyl24CombustionStatus 5;
BA_ "SPN" SG_ 2364544766 EngCyl24CombustionStatus 3410;
BA_ "SAEDocument" SG_ 2364544766 EngCyl24CombustionStatus "J1939-71";
BA_ "SigType" SG_ 2364544766 EngCyl23CombustionStatus 5;
BA_ "SPN" SG_ 2364544766 EngCyl23CombustionStatus 3409;
BA_ "SAEDocument" SG_ 2364544766 EngCyl23CombustionStatus "J1939-71";
BA_ "SigType" SG_ 2364544766 EngCyl22CombustionStatus 5;
BA_ "SPN" SG_ 2364544766 EngCyl22CombustionStatus 3408;
BA_ "SAEDocument" SG_ 2364544766 EngCyl22CombustionStatus "J1939-71";
BA_ "SigType" SG_ 2364544766 EngCyl21CombustionStatus 5;
BA_ "SPN" SG_ 2364544766 EngCyl21CombustionStatus 3407;
BA_ "SAEDocument" SG_ 2364544766 EngCyl21CombustionStatus "J1939-71";
BA_ "SigType" SG_ 2364544766 EngCyl20CombustionStatus 5;
BA_ "SPN" SG_ 2364544766 EngCyl20CombustionStatus 3406;
BA_ "SAEDocument" SG_ 2364544766 EngCyl20CombustionStatus "J1939-71";
BA_ "SigType" SG_ 2364544766 EngCyl19CombustionStatus 5;
BA_ "SPN" SG_ 2364544766 EngCyl19CombustionStatus 3405;
BA_ "SAEDocument" SG_ 2364544766 EngCyl19CombustionStatus "J1939-71";
BA_ "SigType" SG_ 2364544766 EngCyl18CombustionStatus 5;
BA_ "SPN" SG_ 2364544766 EngCyl18CombustionStatus 3404;
BA_ "SAEDocument" SG_ 2364544766 EngCyl18CombustionStatus "J1939-71";
BA_ "SigType" SG_ 2364544766 EngCyl17CombustionStatus 5;
BA_ "SPN" SG_ 2364544766 EngCyl17CombustionStatus 3403;
BA_ "SAEDocument" SG_ 2364544766 EngCyl17CombustionStatus "J1939-71";
BA_ "SigType" SG_ 2364544766 EngCyl16CombustionStatus 5;
BA_ "SPN" SG_ 2364544766 EngCyl16CombustionStatus 3402;
BA_ "SAEDocument" SG_ 2364544766 EngCyl16CombustionStatus "J1939-71";
BA_ "SigType" SG_ 2364544766 EngCyl15CombustionStatus 5;
BA_ "SPN" SG_ 2364544766 EngCyl15CombustionStatus 3401;
BA_ "SAEDocument" SG_ 2364544766 EngCyl15CombustionStatus "J1939-71";
BA_ "SigType" SG_ 2364544766 EngCyl14CombustionStatus 5;
BA_ "SPN" SG_ 2364544766 EngCyl14CombustionStatus 3400;
BA_ "SAEDocument" SG_ 2364544766 EngCyl14CombustionStatus "J1939-71";
BA_ "SigType" SG_ 2364544766 EngCyl13CombustionStatus 5;
BA_ "SPN" SG_ 2364544766 EngCyl13CombustionStatus 3399;
BA_ "SAEDocument" SG_ 2364544766 EngCyl13CombustionStatus "J1939-71";
BA_ "SigType" SG_ 2364544766 EngCyl12CombustionStatus 5;
BA_ "SPN" SG_ 2364544766 EngCyl12CombustionStatus 3398;
BA_ "SAEDocument" SG_ 2364544766 EngCyl12CombustionStatus "J1939-71";
BA_ "SigType" SG_ 2364544766 EngCyl11CombustionStatus 5;
BA_ "SPN" SG_ 2364544766 EngCyl11CombustionStatus 3397;
BA_ "SAEDocument" SG_ 2364544766 EngCyl11CombustionStatus "J1939-71";
BA_ "SigType" SG_ 2364544766 EngCyl10CombustionStatus 5;
BA_ "SPN" SG_ 2364544766 EngCyl10CombustionStatus 3396;
BA_ "SAEDocument" SG_ 2364544766 EngCyl10CombustionStatus "J1939-71";
BA_ "SigType" SG_ 2364544766 EngCyl9CombustionStatus 5;
BA_ "SPN" SG_ 2364544766 EngCyl9CombustionStatus 3395;
BA_ "SAEDocument" SG_ 2364544766 EngCyl9CombustionStatus "J1939-71";
BA_ "SigType" SG_ 2364544766 EngCyl8CombustionStatus 5;
BA_ "SPN" SG_ 2364544766 EngCyl8CombustionStatus 3394;
BA_ "SAEDocument" SG_ 2364544766 EngCyl8CombustionStatus "J1939-71";
BA_ "SigType" SG_ 2364544766 EngCyl7CombustionStatus 5;
BA_ "SPN" SG_ 2364544766 EngCyl7CombustionStatus 3393;
BA_ "SAEDocument" SG_ 2364544766 EngCyl7CombustionStatus "J1939-71";
BA_ "SigType" SG_ 2364544766 EngCyl6CombustionStatus 5;
BA_ "SPN" SG_ 2364544766 EngCyl6CombustionStatus 3392;
BA_ "SAEDocument" SG_ 2364544766 EngCyl6CombustionStatus "J1939-71";
BA_ "SigType" SG_ 2364544766 EngCyl5CombustionStatus 5;
BA_ "SPN" SG_ 2364544766 EngCyl5CombustionStatus 3391;
BA_ "SAEDocument" SG_ 2364544766 EngCyl5CombustionStatus "J1939-71";
BA_ "SigType" SG_ 2364544766 EngCyl4CombustionStatus 5;
BA_ "SPN" SG_ 2364544766 EngCyl4CombustionStatus 3390;
BA_ "SAEDocument" SG_ 2364544766 EngCyl4CombustionStatus "J1939-71";
BA_ "SigType" SG_ 2364544766 EngCyl3CombustionStatus 5;
BA_ "SPN" SG_ 2364544766 EngCyl3CombustionStatus 3389;
BA_ "SAEDocument" SG_ 2364544766 EngCyl3CombustionStatus "J1939-71";
BA_ "SigType" SG_ 2364544766 EngCyl2CombustionStatus 5;
BA_ "SPN" SG_ 2364544766 EngCyl2CombustionStatus 3388;
BA_ "SAEDocument" SG_ 2364544766 EngCyl2CombustionStatus "J1939-71";
BA_ "SigType" SG_ 2364544766 EngCyl1CombustionStatus 5;
BA_ "SPN" SG_ 2364544766 EngCyl1CombustionStatus 3387;
BA_ "SAEDocument" SG_ 2364544766 EngCyl1CombustionStatus "J1939-71";
BA_ "SigType" SG_ 2364544510 RqGenOverallPowerFactorLagging 4;
BA_ "SPN" SG_ 2364544510 RqGenOverallPowerFactorLagging 3385;
BA_ "SAEDocument" SG_ 2364544510 RqGenOverallPowerFactorLagging "J1939-75";
BA_ "SigType" SG_ 2364544510 RqGeneratorOverallPowerFactor 1;
BA_ "SPN" SG_ 2364544510 RqGeneratorOverallPowerFactor 3384;
BA_ "SAEDocument" SG_ 2364544510 RqGeneratorOverallPowerFactor "J1939-75";
BA_ "SigType" SG_ 2364544510 RqGeneratorTotalACReactivePower 1;
BA_ "SPN" SG_ 2364544510 RqGeneratorTotalACReactivePower 3383;
BA_ "SAEDocument" SG_ 2364544510 RqGeneratorTotalACReactivePower "J1939-75";
BA_ "SigType" SG_ 2364544254 BladeRotationAngleFigureOfMerit 5;
BA_ "SPN" SG_ 2364544254 BladeRotationAngleFigureOfMerit 3332;
BA_ "SAEDocument" SG_ 2364544254 BladeRotationAngleFigureOfMerit "J1939-71";
BA_ "SigType" SG_ 2364544254 RelativeBladeHeightFigureOfMerit 5;
BA_ "SPN" SG_ 2364544254 RelativeBladeHeightFigureOfMerit 3367;
BA_ "SAEDocument" SG_ 2364544254 RelativeBladeHeightFigureOfMerit "J1939-71";
BA_ "SigType" SG_ 2364544254 RltvBldHghtAndBldRttnAnglMsrmntL 1;
BA_ "SPN" SG_ 2364544254 RltvBldHghtAndBldRttnAnglMsrmntL 3366;
BA_ "SAEDocument" SG_ 2364544254 RltvBldHghtAndBldRttnAnglMsrmntL "J1939-71";
BA_ "SigType" SG_ 2364544254 BladeRotationAngle 1;
BA_ "SPN" SG_ 2364544254 BladeRotationAngle 3331;
BA_ "SAEDocument" SG_ 2364544254 BladeRotationAngle "J1939-71";
BA_ "SigType" SG_ 2364544254 RelativeBladeHeight 1;
BA_ "SPN" SG_ 2364544254 RelativeBladeHeight 3365;
BA_ "SAEDocument" SG_ 2364544254 RelativeBladeHeight "J1939-71";
BA_ "SAEDocument" SG_ 2349006590 RetarderDemandValue "ISO11992";
BA_ "SAEDocument" SG_ 2349006590 ParkBrakeDemandValue "ISO11992";
BA_ "SAEDocument" SG_ 2349006590 ServiceBrakeDemandValue "ISO11992";
BA_ "SAEDocument" SG_ 2349006590 VehicleType "ISO11992";
BA_ "SigType" SG_ 2349006590 BrakeLightSwitch 4;
BA_ "SAEDocument" SG_ 2349006590 BrakeLightSwitch "ISO11992";
BA_ "SigType" SG_ 2349006590 ASREngineControlActive 4;
BA_ "SAEDocument" SG_ 2349006590 ASREngineControlActive "ISO11992";
BA_ "SigType" SG_ 2349006590 ASRBreakControlActive 4;
BA_ "SAEDocument" SG_ 2349006590 ASRBreakControlActive "ISO11992";
BA_ "SigType" SG_ 2349006590 VehicleRetarderCtrlActive 4;
BA_ "SAEDocument" SG_ 2349006590 VehicleRetarderCtrlActive "ISO11992";
BA_ "SigType" SG_ 2349006590 VehicleABSActive 4;
BA_ "SAEDocument" SG_ 2349006590 VehicleABSActive "ISO11992";
BA_ "SPN" SG_ 2566834686 RoadCurvature 1591;
BA_ "SAEDocument" SG_ 2566834686 RoadCurvature "J1939-71";
BA_ "SigType" SG_ 2566834686 PneumaticControlLine 4;
BA_ "SAEDocument" SG_ 2566834686 PneumaticControlLine "ISO11992";
BA_ "SigType" SG_ 2566834686 ABSOffroadRequest 4;
BA_ "SAEDocument" SG_ 2566834686 ABSOffroadRequest "ISO11992";
BA_ "SigType" SG_ 2566834686 TwoElCircuitsBrakeDemand 4;
BA_ "SAEDocument" SG_ 2566834686 TwoElCircuitsBrakeDemand "ISO11992";
BA_ "SigType" SG_ 2566834686 VehicleRetarderCtrlActive 4;
BA_ "SAEDocument" SG_ 2566834686 VehicleRetarderCtrlActive "ISO11992";
BA_ "SAEDocument" SG_ 2550398718 WheelSpeedDiffMainAxle "ISO11992";
BA_ "SigType" SG_ 2550398718 ActualRetarderPercTorque 1;
BA_ "SAEDocument" SG_ 2550398718 ActualRetarderPercTorque "ISO11992";
BA_ "SigType" SG_ 2550398718 Wheel_BasedVehicleSpeed 1;
BA_ "SAEDocument" SG_ 2550398718 Wheel_BasedVehicleSpeed "ISO11992";
BA_ "SigType" SG_ 2550398718 SupplyLineBrakingRequest 4;
BA_ "SAEDocument" SG_ 2550398718 SupplyLineBrakingRequest "ISO11992";
BA_ "SigType" SG_ 2550398718 VDCActive 4;
BA_ "SAEDocument" SG_ 2550398718 VDCActive "ISO11992";
BA_ "SigType" SG_ 2550398718 AutomTowedVehBreakActive 4;
BA_ "SAEDocument" SG_ 2550398718 AutomTowedVehBreakActive "ISO11992";
BA_ "SigType" SG_ 2550398718 VehicleServiceBrakeActive 4;
BA_ "SAEDocument" SG_ 2550398718 VehicleServiceBrakeActive "ISO11992";
BA_ "SigType" SG_ 2550398718 VehicleRetarderCtrlActive 4;
BA_ "SAEDocument" SG_ 2550398718 VehicleRetarderCtrlActive "ISO11992";
BA_ "SigType" SG_ 2550398718 VehicleABSActive 4;
BA_ "SAEDocument" SG_ 2550398718 VehicleABSActive "ISO11992";
BA_ "SigType" SG_ 2566833406 ReferenceRetarderTorque 1;
BA_ "SPN" SG_ 2566833406 ReferenceRetarderTorque 556;
BA_ "SAEDocument" SG_ 2566833406 ReferenceRetarderTorque "J1939-71";
BA_ "SAEDocument" SG_ 2566833406 AxleLoadSum "ISO11992";
BA_ "SigType" SG_ 2566833406 SupplyLineBrakingRequest 4;
BA_ "SAEDocument" SG_ 2566833406 SupplyLineBrakingRequest "ISO11992";
BA_ "SigType" SG_ 2566833406 LoadingRampApproachAssist 4;
BA_ "SAEDocument" SG_ 2566833406 LoadingRampApproachAssist "ISO11992";
BA_ "SigType" SG_ 2566833406 SpringBrakeEngaged 4;
BA_ "SAEDocument" SG_ 2566833406 SpringBrakeEngaged "ISO11992";
BA_ "SigType" SG_ 2566833406 ElectrLoadPropFunc 4;
BA_ "SAEDocument" SG_ 2566833406 ElectrLoadPropFunc "ISO11992";
BA_ "SigType" SG_ 2566833406 SpringBrakeInstalled 4;
BA_ "SAEDocument" SG_ 2566833406 SpringBrakeInstalled "ISO11992";
BA_ "SAEDocument" SG_ 2566833406 VehicleType "ISO11992";
BA_ "SigType" SG_ 2566833406 ElecSupplyOfNonBrakingSys 4;
BA_ "SAEDocument" SG_ 2566833406 ElecSupplyOfNonBrakingSys "ISO11992";
BA_ "SigType" SG_ 2566833406 AmberWarningSignalReq 4;
BA_ "SAEDocument" SG_ 2566833406 AmberWarningSignalReq "ISO11992";
BA_ "SigType" SG_ 2566833406 RedWarningSignalRequest 4;
BA_ "SAEDocument" SG_ 2566833406 RedWarningSignalRequest "ISO11992";
BA_ "SigType" SG_ 2566833406 VehicleElectrSupplySuff 4;
BA_ "SAEDocument" SG_ 2566833406 VehicleElectrSupplySuff "ISO11992";
BA_ "SigType" SG_ 2566833406 AutomTowedVehBreakActive 4;
BA_ "SAEDocument" SG_ 2566833406 AutomTowedVehBreakActive "ISO11992";
BA_ "SigType" SG_ 2566833406 VehicleServiceBrakeActive 4;
BA_ "SAEDocument" SG_ 2566833406 VehicleServiceBrakeActive "ISO11992";
BA_ "SigType" SG_ 2566833406 VehicleRetarderCtrlActive 4;
BA_ "SAEDocument" SG_ 2566833406 VehicleRetarderCtrlActive "ISO11992";
BA_ "SigType" SG_ 2566833406 VehicleABSActive 4;
BA_ "SAEDocument" SG_ 2566833406 VehicleABSActive "ISO11992";
BA_ "SAEDocument" SG_ 2365507326 PneumaticSupplyPressure "ISO11992";
BA_ "SAEDocument" SG_ 2365507326 BrakeTemperature "ISO11992";
BA_ "SAEDocument" SG_ 2365507326 BrakeLining "ISO11992";
BA_ "SAEDocument" SG_ 2365507326 TyrePressure "ISO11992";
BA_ "SAEDocument" SG_ 2365507326 TyreWheelIdentTemp2 "ISO11992";
BA_ "SAEDocument" SG_ 2365507326 TyreWheelIdentTemp1 "ISO11992";
BA_ "SAEDocument" SG_ 2365507326 TyreWheelIdentPressure2 "ISO11992";
BA_ "SAEDocument" SG_ 2365507326 TyreWheelIdentPressure1 "ISO11992";
BA_ "SAEDocument" SG_ 2365507326 TyreWheelIdentLining2 "ISO11992";
BA_ "SAEDocument" SG_ 2365507326 TyreWheelIdentLining1 "ISO11992";
BA_ "SigType" SG_ 2365507326 VehiclePneumSupplySuff 4;
BA_ "SAEDocument" SG_ 2365507326 VehiclePneumSupplySuff "ISO11992";
BA_ "SigType" SG_ 2365507326 BrakeTemperatureStatus 4;
BA_ "SAEDocument" SG_ 2365507326 BrakeTemperatureStatus "ISO11992";
BA_ "SigType" SG_ 2365507326 BrakeLiningSufficient 4;
BA_ "SAEDocument" SG_ 2365507326 BrakeLiningSufficient "ISO11992";
BA_ "SigType" SG_ 2365507326 TyrePressureSufficient 4;
BA_ "SAEDocument" SG_ 2365507326 TyrePressureSufficient "ISO11992";
BA_ "SigType" SG_ 2565013246 ODDRequest 4;
BA_ "SAEDocument" SG_ 2565013246 ODDRequest "ISO11992";
BA_ "SigType" SG_ 2565013246 AntiTheftDeviceReq 4;
BA_ "SAEDocument" SG_ 2565013246 AntiTheftDeviceReq "ISO11992";
BA_ "SAEDocument" SG_ 2565013246 VehicleType "ISO11992";
BA_ "SigType" SG_ 2566807038 MaxVehicleSpeedLimit 1;
BA_ "SPN" SG_ 2566807038 MaxVehicleSpeedLimit 74;
BA_ "SAEDocument" SG_ 2566807038 MaxVehicleSpeedLimit "J1939-71";
BA_ "SAEDocument" SG_ 2566807038 EngineSpeedUpperLimit "ISO11992";
BA_ "SAEDocument" SG_ 2566807038 EngineSpeedLowerLimit "ISO11992";
BA_ "SAEDocument" SG_ 2365480958 EngineTorqueMode "ISO11992";
BA_ "SigType" SG_ 2365480958 VehicleSpeed 1;
BA_ "SAEDocument" SG_ 2365480958 VehicleSpeed "ISO11992";
BA_ "SigType" SG_ 2365480958 PercentLoadAtCurrentSpeed 1;
BA_ "SAEDocument" SG_ 2365480958 PercentLoadAtCurrentSpeed "ISO11992";
BA_ "SigType" SG_ 2365480958 EngineSpeed 1;
BA_ "SAEDocument" SG_ 2365480958 EngineSpeed "ISO11992";
BA_ "SigType" SG_ 2365480958 ActualEngine_PercTorque 1;
BA_ "SAEDocument" SG_ 2365480958 ActualEngine_PercTorque "ISO11992";
BA_ "SigType" SG_ 2365480958 DriversDemandEngine_PercTorque 1;
BA_ "SAEDocument" SG_ 2365480958 DriversDemandEngine_PercTorque "ISO11992";
BA_ "SigType" SG_ 2365480958 EngineRunning 4;
BA_ "SAEDocument" SG_ 2365480958 EngineRunning "ISO11992";
BA_ "SigType" SG_ 2365480958 EngineControlAllowed 4;
BA_ "SAEDocument" SG_ 2365480958 EngineControlAllowed "ISO11992";
BA_ "SigType" SG_ 2566808062 ClutchIndptdPTOFeedback 4;
BA_ "SAEDocument" SG_ 2566808062 ClutchIndptdPTOFeedback "ISO11992";
BA_ "SigType" SG_ 2566808062 AccelPedalPosition 1;
BA_ "SAEDocument" SG_ 2566808062 AccelPedalPosition "ISO11992";
BA_ "SigType" SG_ 2566808062 AccelPedalLowIdleSwitch 4;
BA_ "SAEDocument" SG_ 2566808062 AccelPedalLowIdleSwitch "ISO11992";
BA_ "SigType" SG_ 2566808062 StarterActive 4;
BA_ "SAEDocument" SG_ 2566808062 StarterActive "ISO11992";
BA_ "SAEDocument" SG_ 2566808062 TorqueConvOilTemp "ISO11992";
BA_ "SAEDocument" SG_ 2566808062 TorqueConvtOilTempWarning "ISO11992";
BA_ "SigType" SG_ 2566808062 PTOControlAllowed 4;
BA_ "SAEDocument" SG_ 2566808062 PTOControlAllowed "ISO11992";
BA_ "SigType" SG_ 2566808062 SecEngineMtdPTOFeedback 4;
BA_ "SAEDocument" SG_ 2566808062 SecEngineMtdPTOFeedback "ISO11992";
BA_ "SigType" SG_ 2566808062 FirstEngineMtdPTOFeedback 4;
BA_ "SAEDocument" SG_ 2566808062 FirstEngineMtdPTOFeedback "ISO11992";
BA_ "SigType" SG_ 2566808062 SecClutchDptdPTOFeedback 4;
BA_ "SAEDocument" SG_ 2566808062 SecClutchDptdPTOFeedback "ISO11992";
BA_ "SigType" SG_ 2566808062 FirstClutchDpdtPTOFeedback 4;
BA_ "SAEDocument" SG_ 2566808062 FirstClutchDpdtPTOFeedback "ISO11992";
BA_ "SigType" SG_ 2566808062 CurrentGear 1;
BA_ "SAEDocument" SG_ 2566808062 CurrentGear "ISO11992";
BA_ "SigType" SG_ 2566808062 PercentClutchSlip 1;
BA_ "SPN" SG_ 2566808062 PercentClutchSlip 522;
BA_ "SAEDocument" SG_ 2566808062 PercentClutchSlip "J1939-71";
BA_ "SigType" SG_ 2566808574 ReferenceEngineTorque 1;
BA_ "SAEDocument" SG_ 2566808574 ReferenceEngineTorque "ISO11992";
BA_ "SigType" SG_ 2566808574 FuelLevelWarning 4;
BA_ "SAEDocument" SG_ 2566808574 FuelLevelWarning "ISO11992";
BA_ "SigType" SG_ 2566808574 EngineOilPressureWarning 4;
BA_ "SAEDocument" SG_ 2566808574 EngineOilPressureWarning "ISO11992";
BA_ "SAEDocument" SG_ 2566808574 EngineCoolantTempWarning "ISO11992";
BA_ "SigType" SG_ 2566808574 EngineOilPressure 1;
BA_ "SAEDocument" SG_ 2566808574 EngineOilPressure "ISO11992";
BA_ "SigType" SG_ 2566808574 EngCoolantTemp 1;
BA_ "SPN" SG_ 2566808574 EngCoolantTemp 110;
BA_ "SAEDocument" SG_ 2566808574 EngCoolantTemp "J1939-71";
BA_ "SigType" SG_ 2566808574 EngineOilTemperature 1;
BA_ "SAEDocument" SG_ 2566808574 EngineOilTemperature "ISO11992";
BA_ "SigType" SG_ 2566809086 AmbientAirTemperature 1;
BA_ "SAEDocument" SG_ 2566809086 AmbientAirTemperature "ISO11992";
BA_ "SAEDocument" SG_ 2564947710 VehicleType "ISO11992";
BA_ "SAEDocument" SG_ 2566834430 BodyPressure "ISO11992";
BA_ "SAEDocument" SG_ 2566834430 BodyFluidLevel "ISO11992";
BA_ "SAEDocument" SG_ 2566834430 ThermalBodyTemperature "ISO11992";
BA_ "SAEDocument" SG_ 2566834430 RearObstacleDistance "ISO11992";
BA_ "SigType" SG_ 2566834430 AntiTheftDeviceStatus 4;
BA_ "SAEDocument" SG_ 2566834430 AntiTheftDeviceStatus "ISO11992";
BA_ "SigType" SG_ 2566834430 ODDStatus 4;
BA_ "SAEDocument" SG_ 2566834430 ODDStatus "ISO11992";
BA_ "SAEDocument" SG_ 2365481214 ReqEngineSpeedUpperLim "ISO11992";
BA_ "SAEDocument" SG_ 2365481214 ReqEngineSpeedLowerLim "ISO11992";
BA_ "SAEDocument" SG_ 2365481214 ReqEngineTorqueLimit "ISO11992";
BA_ "SAEDocument" SG_ 2365481214 ReqEngineSpeedLimit "ISO11992";
BA_ "SAEDocument" SG_ 2365481214 ReqEngineSpeed "ISO11992";
BA_ "SigType" SG_ 2566808318 SecEngineMtdPTOSwitch 4;
BA_ "SAEDocument" SG_ 2566808318 SecEngineMtdPTOSwitch "ISO11992";
BA_ "SigType" SG_ 2566808318 SecClutchDpdtPTOSwitch 4;
BA_ "SAEDocument" SG_ 2566808318 SecClutchDpdtPTOSwitch "ISO11992";
BA_ "SigType" SG_ 2566808318 FirstClutchDpdtPTOSwitch 4;
BA_ "SAEDocument" SG_ 2566808318 FirstClutchDpdtPTOSwitch "ISO11992";
BA_ "SigType" SG_ 2566808318 OperatingPanelActive 4;
BA_ "SAEDocument" SG_ 2566808318 OperatingPanelActive "ISO11992";
BA_ "SigType" SG_ 2566808318 RefusePackerStepSwitch 4;
BA_ "SAEDocument" SG_ 2566808318 RefusePackerStepSwitch "ISO11992";
BA_ "SigType" SG_ 2566808318 EngineStopSwitch 4;
BA_ "SAEDocument" SG_ 2566808318 EngineStopSwitch "ISO11992";
BA_ "SigType" SG_ 2566808318 EngineStartSwitch 4;
BA_ "SAEDocument" SG_ 2566808318 EngineStartSwitch "ISO11992";
BA_ "SigType" SG_ 2566808318 StarterLockoutSwitch 4;
BA_ "SAEDocument" SG_ 2566808318 StarterLockoutSwitch "ISO11992";
BA_ "SigType" SG_ 2566808318 RqstedPercentClutchSlip 1;
BA_ "SAEDocument" SG_ 2566808318 RqstedPercentClutchSlip "ISO11992";
BA_ "SigType" SG_ 2566808318 FirstEngineMtdPTOSwitch 4;
BA_ "SAEDocument" SG_ 2566808318 FirstEngineMtdPTOSwitch "ISO11992";
BA_ "SigType" SG_ 2566808318 ClutchIndpdtPTOSwitch 4;
BA_ "SAEDocument" SG_ 2566808318 ClutchIndpdtPTOSwitch "ISO11992";
BA_ "SigType" SG_ 2566808830 TrailerLeftSideMarkerLight 4;
BA_ "SAEDocument" SG_ 2566808830 TrailerLeftSideMarkerLight "ISO11992";
BA_ "SigType" SG_ 2566808830 TrailerLeftReversingLight 4;
BA_ "SAEDocument" SG_ 2566808830 TrailerLeftReversingLight "ISO11992";
BA_ "SigType" SG_ 2566808830 TrailerLeftRearWidIndLight 4;
BA_ "SAEDocument" SG_ 2566808830 TrailerLeftRearWidIndLight "ISO11992";
BA_ "SigType" SG_ 2566808830 TrailerLeftRearRegPltLight 4;
BA_ "SAEDocument" SG_ 2566808830 TrailerLeftRearRegPltLight "ISO11992";
BA_ "SigType" SG_ 2566808830 TrailerLeftRearLight 4;
BA_ "SAEDocument" SG_ 2566808830 TrailerLeftRearLight "ISO11992";
BA_ "SigType" SG_ 2566808830 TrailerLeftRearFogLight 4;
BA_ "SAEDocument" SG_ 2566808830 TrailerLeftRearFogLight "ISO11992";
BA_ "SigType" SG_ 2566808830 TrailerLeftDirIndLight 4;
BA_ "SAEDocument" SG_ 2566808830 TrailerLeftDirIndLight "ISO11992";
BA_ "SigType" SG_ 2566808830 TrailerLeftCrnMarkerLight 4;
BA_ "SAEDocument" SG_ 2566808830 TrailerLeftCrnMarkerLight "ISO11992";
BA_ "SigType" SG_ 2566808830 TrailerInteriorLight 4;
BA_ "SAEDocument" SG_ 2566808830 TrailerInteriorLight "ISO11992";
BA_ "SigType" SG_ 2566808830 TrailerWorkLamp 4;
BA_ "SAEDocument" SG_ 2566808830 TrailerWorkLamp "ISO11992";
BA_ "SigType" SG_ 2566808830 TrailerRotatingIdentLight 4;
BA_ "SAEDocument" SG_ 2566808830 TrailerRotatingIdentLight "ISO11992";
BA_ "SigType" SG_ 2566808830 TrailerRightStopLight 4;
BA_ "SAEDocument" SG_ 2566808830 TrailerRightStopLight "ISO11992";
BA_ "SigType" SG_ 2566808830 TrailerRightSideMrkLight 4;
BA_ "SAEDocument" SG_ 2566808830 TrailerRightSideMrkLight "ISO11992";
BA_ "SigType" SG_ 2566808830 TrailerRightReversingLight 4;
BA_ "SAEDocument" SG_ 2566808830 TrailerRightReversingLight "ISO11992";
BA_ "SigType" SG_ 2566808830 TrailRightRearWidIndLight 4;
BA_ "SAEDocument" SG_ 2566808830 TrailRightRearWidIndLight "ISO11992";
BA_ "SigType" SG_ 2566808830 TrailerRightRearRegPltLight 4;
BA_ "SAEDocument" SG_ 2566808830 TrailerRightRearRegPltLight "ISO11992";
BA_ "SigType" SG_ 2566808830 TrailerRightRearLight 4;
BA_ "SAEDocument" SG_ 2566808830 TrailerRightRearLight "ISO11992";
BA_ "SigType" SG_ 2566808830 TrailerRightRearFogLight 4;
BA_ "SAEDocument" SG_ 2566808830 TrailerRightRearFogLight "ISO11992";
BA_ "SigType" SG_ 2566808830 TrailerRightDirIndLight 4;
BA_ "SAEDocument" SG_ 2566808830 TrailerRightDirIndLight "ISO11992";
BA_ "SigType" SG_ 2566808830 TrailerRightCrnMarkerLight 4;
BA_ "SAEDocument" SG_ 2566808830 TrailerRightCrnMarkerLight "ISO11992";
BA_ "SigType" SG_ 2566808830 TrailerRearWarningLight 4;
BA_ "SAEDocument" SG_ 2566808830 TrailerRearWarningLight "ISO11992";
BA_ "SigType" SG_ 2566808830 TrailerLeftStopLight 4;
BA_ "SAEDocument" SG_ 2566808830 TrailerLeftStopLight "ISO11992";
BA_ "SAEDocument" SG_ 2564554494 SN "ISO15765";
BA_ "SAEDocument" SG_ 2564554494 SeparationTime "ISO15765";
BA_ "SAEDocument" SG_ 2564554494 BlockSize "ISO15765";
BA_ "SAEDocument" SG_ 2564554494 FlowStatus "ISO15765";
BA_ "SAEDocument" SG_ 2564554494 FirstFrameDataLength "ISO15765";
BA_ "SAEDocument" SG_ 2564554494 SingleFrameDataLength "ISO15765";
BA_ "SAEDocument" SG_ 2564554494 ProtocolCtrlInformation "ISO15765";
BA_ "SAEDocument" SG_ 2564488958 SN "ISO15765";
BA_ "SAEDocument" SG_ 2564488958 SeparationTime "ISO15765";
BA_ "SAEDocument" SG_ 2564488958 BlockSize "ISO15765";
BA_ "SAEDocument" SG_ 2564488958 FlowStatus "ISO15765";
BA_ "SAEDocument" SG_ 2564488958 FirstFrameDataLength "ISO15765";
BA_ "SAEDocument" SG_ 2564488958 SingleFrameDataLength "ISO15765";
BA_ "SAEDocument" SG_ 2564488958 ProtocolCtrlInformation "ISO15765";
VAL_ 2365473278 ImplementRearWorkLightCmd 3 "Dont Care" 2 "Reserved" 1 "Activate" 0 "Deactivate" ;
VAL_ 2365473278 ImplementLeftForwardWorkLightCmd 3 "Dont Care" 2 "Reserved" 1 "Activate" 0 "Deactivate" ;
VAL_ 2365473278 ImplmentRightForwardWorkLightCmd 3 "Dont Care" 2 "Reserved" 1 "Activate" 0 "Deactivate" ;
VAL_ 2365473278 LightingDataRqCmd 3 "Dont Care" 2 "Reserved" 1 "Activate" 0 "Deactivate" ;
VAL_ 2365473278 ImplementLeftFacingWorkLightCmd 3 "Dont Care" 2 "Reserved" 1 "Activate" 0 "Deactivate" ;
VAL_ 2365473278 ImplementRightFacingWorkLightCmd 3 "Dont Care" 2 "Reserved" 1 "Activate" 0 "Deactivate" ;
VAL_ 2365473278 ImplementOEMOption1LightCmd 3 "Dont Care" 2 "Reserved" 1 "Activate" 0 "Deactivate" ;
VAL_ 2365473278 ImplementOEMOption2LightCmd 3 "Dont Care" 2 "Reserved" 1 "Activate" 0 "Deactivate" ;
VAL_ 2365473278 TrctrFrntHghMountedWorkLightsCmd 3 "Dont Care" 2 "Reserved" 1 "Activate" 0 "Deactivate" ;
VAL_ 2365473278 TrctrFrntLowMountedWorkLightsCmd 3 "Dont Care" 2 "Reserved" 1 "Activate" 0 "Deactivate" ;
VAL_ 2365473278 TrctrSdeHighMountedWorkLightsCmd 3 "Dont Care" 2 "Reserved" 1 "Activate" 0 "Deactivate" ;
VAL_ 2365473278 TrctrSideLowMountedWorkLightsCmd 3 "Dont Care" 2 "Reserved" 1 "Activate" 0 "Deactivate" ;
VAL_ 2365473278 TrctrRarHighMountedWorkLightsCmd 3 "Dont Care" 2 "Reserved" 1 "Activate" 0 "Deactivate" ;
VAL_ 2365473278 TrctrRearLowMountedWorkLightsCmd 3 "Dont Care" 2 "Reserved" 1 "Activate" 0 "Deactivate" ;
VAL_ 2365473278 TrctrUndrsdeMountedWorkLightsCmd 3 "Dont Care" 2 "Reserved" 1 "Activate" 0 "Deactivate" ;
VAL_ 2365473278 RearFogLightCmd 3 "Dont Care" 2 "Reserved" 1 "Activate" 0 "Deactivate" ;
VAL_ 2365473278 TractorMarkerLightCmd 3 "Dont Care" 2 "Reserved" 1 "Activate" 0 "Deactivate" ;
VAL_ 2365473278 ImplementMarkerLightCmd 3 "Dont Care" 2 "Reserved" 1 "Activate" 0 "Deactivate" ;
VAL_ 2365473278 TractorClearanceLightCmd 3 "Dont Care" 2 "Reserved" 1 "Activate" 0 "Deactivate" ;
VAL_ 2365473278 ImplementClearanceLightCmd 3 "Dont Care" 2 "Reserved" 1 "Activate" 0 "Deactivate" ;
VAL_ 2365473278 LeftStopLightCmd 3 "Dont Care" 2 "Reserved" 1 "Activate" 0 "Deactivate" ;
VAL_ 2365473278 RightStopLightCmd 3 "Dont Care" 2 "Reserved" 1 "Activate" 0 "Deactivate" ;
VAL_ 2365473278 CenterStopLightCmd 3 "Dont Care" 2 "Reserved" 1 "Activate" 0 "Deactivate" ;
VAL_ 2365473278 BackUpLightAndAlarmHornCmd 3 "Dont Care" 2 "Reserved" 1 "Activate" 0 "Deactivate" ;
VAL_ 2365473278 LeftTurnSignalLightsCmd 3 "Dont Care" 2 "Reserved" 1 "Activate" 0 "Deactivate" ;
VAL_ 2365473278 RightTurnSignalLightsCmd 3 "Dont Care" 2 "Reserved" 1 "Activate" 0 "Deactivate" ;
VAL_ 2365473278 RotatingBeaconLightCmd 3 "Dont Care" 2 "Reserved" 1 "Activate" 0 "Deactivate" ;
VAL_ 2365473278 TractorFrontFogLightsCmd 3 "Dont Care" 2 "Reserved" 1 "Activate" 0 "Deactivate" ;
VAL_ 2365473278 HighBeamHeadLightCmd 3 "Dont Care" 2 "Reserved" 1 "Activate" 0 "Deactivate" ;
VAL_ 2365473278 LowBeamHeadLightCmd 3 "Dont Care" 2 "Reserved" 1 "Activate" 0 "Deactivate" ;
VAL_ 2365473278 AltBeamHeadLightCmd 3 "Dont Care" 2 "Reserved" 1 "Activate" 0 "Deactivate" ;
VAL_ 2365473278 RunningLightCmd 3 "Dont Care" 2 "Reserved" 1 "Activate" 0 "Deactivate" ;
VAL_ 2365485822 LandLevelingSystemEnableStatus 3 "Not available / Not installed" 2 "Error" 0 "Disabled" ;
VAL_ 2365485822 BladeCtrlModeRight 15 "Not Available" 14 "Error" 2 "Inactive Auto" 1 "Auto" 0 "Manual" ;
VAL_ 2365485822 BladeCtrlModeLeft 15 "Not Available" 14 "Error" 2 "Inactive Auto" 1 "Auto" 0 "Manual" ;
VAL_ 2365485822 BladeCtrlMode 2 "Inactive automatic mode" 1 "Automatic mode" 0 "Manual mode" ;
VAL_ 2566768894 EngOprtrPrmryIntrmdtSpdSlctState 15 "not available" 14 "SAE reserved" 1 "thru 1101  Control state is ISC Setting 1 thru 13 in sequential order" 0 "Control state is ISC functionality is not requested engine operates normally" ;
VAL_ 2566769406 EngOprtrPrmryIntrmdteSpeedSelect 15 "not available" 14 "error condition" 1 "thru 1101  indicates that the ISC Setting 1 thru 13 in sequential order is selected" 0 "indicates that the ISC functionality is not requested engine operates normally" ;
VAL_ 2566811134 CabHeatingZone 3 "Not available" 2 "Reserved" 1 "Cab heating zone on" 0 "Cab heating zone off" ;
VAL_ 2566811134 EngHeatingZone 3 "Not available" 2 "Reserved" 1 "Engine heating zone on" 0 "Engine heating zone off" ;
VAL_ 2566811134 CabVentilation 3 "Not available" 2 "Reserved" 1 "Cab is ventilated" 0 "Cab not ventilated" ;
VAL_ 2566811134 AuxHeaterWaterPumpStatus 3 "Not available" 2 "Reserved" 1 "Water Pump is running" 0 "Water Pump is not running" ;
VAL_ 2566811134 AuxHeaterMode 15 "Not available" 14 "Error" 3 "Normal mode" 2 "Economy mode" 1 "Off due to ADR per European Regulations for Transport of hazardous materials" 0 "Heater not active" ;
VAL_ 2565867774 FireApparatusPumpEngagement 3 "Not available or not installed" 2 "Error" 1 "Pump engaged" 0 "Pump not engaged" ;
VAL_ 2565867774 EngHydPressGovernorSwitch 3 "Not Available" 2 "Error Indicator" 1 "Pressure Mode Active" 0 "Pressure Mode Inactive" ;
VAL_ 2565867774 EngHydPressGovernorModeIndicator 3 "Not Available" 2 "Error Indicator" 1 "Enabled" 0 "Disabled" ;
VAL_ 2365449982 HydBrakeFluidLevelSwitch 3 "Not available" 2 "Error indicator" 1 "Fluid level is sufficient" 0 "Fluid level is not sufficient" ;
VAL_ 2365449982 HydBrakeSystemAudibleWarningCmd 3 "Dont care" 2 "Reserved" 1 "Audible warning on" 0 "Audible warning off" ;
VAL_ 2365449982 HydBrakePressSupplyStateCircuit2 3 "Not available" 2 "Error indicator" 1 "Supply is reliable" 0 "Supply is not reliable" ;
VAL_ 2365449982 HydBrakePressSupplyStateCircuit1 3 "Not available" 2 "Error indicator" 1 "Supply is reliable" 0 "Supply is not reliable" ;
VAL_ 2365449982 HydBrkePressWarningStateCircuit2 3 "Not available" 2 "Error indicator" 1 "Pressure level below warning level" 0 "Pressure level sufficient" ;
VAL_ 2365449982 HydBrkePressWarningStateCircuit1 3 "Not available" 2 "Error indicator" 1 "Pressure level below warning level" 0 "Pressure level sufficient" ;
VAL_ 2566759678 AtLeastOnePTOEngaged 3 "Not available" 2 "Error" 1 "At least one PTO drive is engaged" 0 "No PTO drive is engaged" ;
VAL_ 2566759678 EnggmntSttsPTOEngAccessoryDrive2 3 "Not available" 2 "Error" 1 "Drive engaged" 0 "Drive not engaged" ;
VAL_ 2566759678 EnggmntSttsPTOEngAccessoryDrive1 3 "Not available" 2 "Error" 1 "Drive engaged" 0 "Drive not engaged" ;
VAL_ 2566759678 EngagementStatusPTOEngFlywheel 3 "Not available" 2 "Error" 1 "Drive engaged" 0 "Drive not engaged" ;
VAL_ 2566759678 EnggmntStatusTransInputShaftPTO1 3 "Not available" 2 "Error" 1 "Drive is engaged" 0 "Drive not engaged" ;
VAL_ 2566759678 EnggmntStatusTransInputShaftPTO2 3 "Not available" 2 "Error" 1 "Drive is engaged" 0 "Drive not engaged" ;
VAL_ 2566759678 EnggmntStatusTransOutputShaftPTO 3 "Not available" 2 "Error" 1 "Drive is engaged" 0 "Drive not engaged" ;
VAL_ 2566759678 EnggmntSttsTrnsfrCsOtputShaftPTO 3 "Not available" 2 "Error" 1 "Drive is engaged" 0 "Drive not engaged" ;
VAL_ 2566759678 EnggmntCnsntPTOEngAccssoryDrive2 3 "Not available" 2 "Error" 1 "Consent given  PTO drive may be engaged" 0 "Consent not given  PTO drive may not be engaged" ;
VAL_ 2566759678 EnggmntCnsntPTOEngAccssoryDrive1 3 "Not available" 2 "Error" 1 "Consent given  PTO drive may be engaged" 0 "Consent not given  PTO drive may not be engaged" ;
VAL_ 2566759678 EngagementConsentPTOEngFlywheel 3 "Not available" 2 "Error" 1 "Consent given  PTO drive may be engaged" 0 "Consent not given  PTO drive may not be engaged" ;
VAL_ 2566759678 EnggmntCnsentTransInputShaftPTO1 3 "Not available" 2 "Error" 1 "Consent given  PTO drive may be engaged" 0 "Consent not given  PTO drive should not be engaged" ;
VAL_ 2566759678 EnggmntCnsentTransInputShaftPTO2 3 "Not available" 2 "Error" 1 "Consent given  PTO drive may be engaged" 0 "Consent not given  PTO drive should not be engaged" ;
VAL_ 2566759678 EnggmntCnsentTransOutputShaftPTO 3 "Not available" 2 "Error" 1 "Consent given  PTO drive may be engaged" 0 "Consent not given  PTO drive should not be engaged" ;
VAL_ 2566759678 EnggmntCnsntTrnsfrCsOtptShaftPTO 3 "Not available" 2 "Error" 1 "Consent given  PTO drive may be engaged" 0 "Consent not given  PTO drive should not be engaged" ;
VAL_ 2566759678 EnbleSwitchPTOEngAccessoryDrive2 3 "Not available" 2 "Error" 1 "Enable switch on  PTO operation desired" 0 "Enable switch off  PTO operation not desired" ;
VAL_ 2566759678 EnbleSwitchPTOEngAccessoryDrive1 3 "Not available" 2 "Error" 1 "Enable switch on  PTO operation desired" 0 "Enable switch off  PTO operation not desired" ;
VAL_ 2566759678 EnableSwitchPTOEngFlywheel 3 "Not available" 2 "Error" 1 "Enable switch on  PTO operation desired" 0 "Enable switch off  PTO operation not desired" ;
VAL_ 2566759678 EnableSwitchTransInputShaftPTO1 3 "Not available" 2 "Error" 1 "Enable switch off  PTO operation desired" 0 "Enable switch off  PTO operation not desired" ;
VAL_ 2566759678 EnableSwitchTransInputShaftPTO2 3 "Not available" 2 "Error" 1 "Enable switch off  PTO operation desired" 0 "Enable switch off  PTO operation not desired" ;
VAL_ 2566759678 EnableSwitchTransOutputShaftPTO 3 "Not available" 2 "Error" 1 "Enable switch off  PTO operation desired" 0 "Enable switch off  PTO operation not desired" ;
VAL_ 2566759678 EnblSwtchTrnsfrCseOutputShaftPTO 3 "Not available" 2 "Error" 1 "Enable switch off  PTO operation desired" 0 "Enable switch off  PTO operation not desired" ;
VAL_ 2432541694 EngTrbCmprssrBypssActtr1TmpSttus 7 "Not available" 6 "Error" 5 "Not Defined" 4 "Low Most severe" 3 "Low Least severe" 2 "In Range" 1 "High Least severe" 0 "High Most severe" ;
VAL_ 2566759934 EnableStatusOfDoor10 3 "not available" 2 "error" 1 "door enabled" 0 "door disabled" ;
VAL_ 2566759934 OpenStatusOfDoor10 3 "not available" 2 "error" 1 "door opened" 0 "door closed" ;
VAL_ 2566759934 LockStatusOfDoor10 3 "not available" 2 "error" 1 "locked" 0 "unlocked" ;
VAL_ 2566759934 EnableStatusOfDoor9 3 "not available" 2 "error" 1 "door enabled" 0 "door disabled" ;
VAL_ 2566759934 OpenStatusOfDoor9 3 "not available" 2 "error" 1 "door opened" 0 "door closed" ;
VAL_ 2566759934 LockStatusOfDoor9 3 "not available" 2 "error" 1 "locked" 0 "unlocked" ;
VAL_ 2566759934 EnableStatusOfDoor8 3 "not available" 2 "error" 1 "door enabled" 0 "door disabled" ;
VAL_ 2566759934 OpenStatusOfDoor8 3 "not available" 2 "error" 1 "door opened" 0 "door closed" ;
VAL_ 2566759934 LockStatusOfDoor8 3 "not available" 2 "error" 1 "locked" 0 "unlocked" ;
VAL_ 2566759934 EnableStatusOfDoor7 3 "not available" 2 "error" 1 "door enabled" 0 "door disabled" ;
VAL_ 2566759934 OpenStatusOfDoor7 3 "not available" 2 "error" 1 "door opened" 0 "door closed" ;
VAL_ 2566759934 LockStatusOfDoor7 3 "not available" 2 "error" 1 "locked" 0 "unlocked" ;
VAL_ 2566759934 EnableStatusOfDoor6 3 "not available" 2 "error" 1 "door enabled" 0 "door disabled" ;
VAL_ 2566759934 OpenStatusOfDoor6 3 "not available" 2 "error" 1 "door opened" 0 "door closed" ;
VAL_ 2566759934 LockStatusOfDoor6 3 "not available" 2 "error" 1 "locked" 0 "unlocked" ;
VAL_ 2566759934 EnableStatusOfDoor5 3 "not available" 2 "error" 1 "door enabled" 0 "door disabled" ;
VAL_ 2566759934 OpenStatusOfDoor5 3 "not available" 2 "error" 1 "door opened" 0 "door closed" ;
VAL_ 2566759934 LockStatusOfDoor5 3 "not available" 2 "error" 1 "locked" 0 "unlocked" ;
VAL_ 2566759934 EnableStatusOfDoor4 3 "not available" 2 "error" 1 "door enabled" 0 "door disabled" ;
VAL_ 2566759934 OpenStatusOfDoor4 3 "not available" 2 "error" 1 "door opened" 0 "door closed" ;
VAL_ 2566759934 LockStatusOfDoor4 3 "not available" 2 "error" 1 "locked" 0 "unlocked" ;
VAL_ 2566759934 EnableStatusOfDoor3 3 "not available" 2 "error" 1 "door enabled" 0 "door disabled" ;
VAL_ 2566759934 OpenStatusOfDoor3 3 "not available" 2 "error" 1 "door opened" 0 "door closed" ;
VAL_ 2566759934 LockStatusOfDoor3 3 "not available" 2 "error" 1 "locked" 0 "unlocked" ;
VAL_ 2566759934 EnableStatusOfDoor2 3 "not available" 2 "error" 1 "door enabled" 0 "door disabled" ;
VAL_ 2566759934 OpenStatusOfDoor2 3 "not available" 2 "error" 1 "door opened" 0 "door closed" ;
VAL_ 2566759934 LockStatusOfDoor2 3 "not available" 2 "error" 1 "locked" 0 "unlocked" ;
VAL_ 2566759934 EnableStatusOfDoor1 3 "not available" 2 "error" 1 "door enabled" 0 "door disabled" ;
VAL_ 2566759934 OpenStatusOfDoor1 3 "not available" 2 "error" 1 "door opened" 0 "door closed" ;
VAL_ 2566759934 LockStatusOfDoor1 3 "not available" 2 "error" 1 "locked" 0 "unlocked" ;
VAL_ 2566757374 Aftrtrtmnt1SCRCtalystReagentType 15 "Not available" 14 "Error detected with urea reagent type detection" 13 "Not able to determine catalyst reagent type type unknown" 5 "to 1100  Reserved for SAE assignment" 3 "Catalyst reagent is proper mixture" 2 "Catalyst reagent is diesel" 1 "Catalyst reagent is urea concentration too low" 0 "Catalyst reagent is urea concentration too high" ;
VAL_ 2364544766 EngCyl24CombustionStatus 3 "Not available" 2 "Error" 1 "Combustion exists" 0 "No combustion" ;
VAL_ 2364544766 EngCyl23CombustionStatus 3 "Not available" 2 "Error" 1 "Combustion exists" 0 "No combustion" ;
VAL_ 2364544766 EngCyl22CombustionStatus 3 "Not available" 2 "Error" 1 "Combustion exists" 0 "No combustion" ;
VAL_ 2364544766 EngCyl21CombustionStatus 3 "Not available" 2 "Error" 1 "Combustion exists" 0 "No combustion" ;
VAL_ 2364544766 EngCyl20CombustionStatus 3 "Not available" 2 "Error" 1 "Combustion exists" 0 "No combustion" ;
VAL_ 2364544766 EngCyl19CombustionStatus 3 "Not available" 2 "Error" 1 "Combustion exists" 0 "No combustion" ;
VAL_ 2364544766 EngCyl18CombustionStatus 3 "Not available" 2 "Error" 1 "Combustion exists" 0 "No combustion" ;
VAL_ 2364544766 EngCyl17CombustionStatus 3 "Not available" 2 "Error" 1 "Combustion exists" 0 "No combustion" ;
VAL_ 2364544766 EngCyl16CombustionStatus 3 "Not available" 2 "Error" 1 "Combustion exists" 0 "No combustion" ;
VAL_ 2364544766 EngCyl15CombustionStatus 3 "Not available" 2 "Error" 1 "Combustion exists" 0 "No combustion" ;
VAL_ 2364544766 EngCyl14CombustionStatus 3 "Not available" 2 "Error" 1 "Combustion exists" 0 "No combustion" ;
VAL_ 2364544766 EngCyl13CombustionStatus 3 "Not available" 2 "Error" 1 "Combustion exists" 0 "No combustion" ;
VAL_ 2364544766 EngCyl12CombustionStatus 3 "Not available" 2 "Error" 1 "Combustion exists" 0 "No combustion" ;
VAL_ 2364544766 EngCyl11CombustionStatus 3 "Not available" 2 "Error" 1 "Combustion exists" 0 "No combustion" ;
VAL_ 2364544766 EngCyl10CombustionStatus 3 "Not available" 2 "Error" 1 "Combustion exists" 0 "No combustion" ;
VAL_ 2364544766 EngCyl9CombustionStatus 3 "Not available" 2 "Error" 1 "Combustion exists" 0 "No combustion" ;
VAL_ 2364544766 EngCyl8CombustionStatus 3 "Not available" 2 "Error" 1 "Combustion exists" 0 "No combustion" ;
VAL_ 2364544766 EngCyl7CombustionStatus 3 "Not available" 2 "Error" 1 "Combustion exists" 0 "No combustion" ;
VAL_ 2364544766 EngCyl6CombustionStatus 3 "Not available" 2 "Error" 1 "Combustion exists" 0 "No combustion" ;
VAL_ 2364544766 EngCyl5CombustionStatus 1 "Combustion exists" 0 "No combustion" 3 "Not available" 2 "Error" ;
VAL_ 2364544766 EngCyl4CombustionStatus 3 "Not available" 2 "Error" 1 "Combustion exists" 0 "No combustion" ;
VAL_ 2364544766 EngCyl3CombustionStatus 3 "Not available" 2 "Error" 1 "Combustion exists" 0 "No combustion" ;
VAL_ 2364544766 EngCyl2CombustionStatus 3 "Not available" 2 "Error" 1 "Combustion exists" 0 "No combustion" ;
VAL_ 2364544766 EngCyl1CombustionStatus 3 "Not available" 2 "Error" 1 "Combustion exists" 0 "No combustion" ;
VAL_ 2364544510 RqGenOverallPowerFactorLagging 3 "NotAvailable" 2 "Error" 1 "Lagging" 0 "Leading" ;
VAL_ 2364544254 BladeRotationAngleFigureOfMerit 3 "Blade Rotation Angle not available" 2 "Blade Rotation Angle failed Roll sensor failed to operate correctly" 1 "Blade Rotation Angle degraded Data is suspect due to environmental conditions" 0 "Blade Rotation Angle fully functional Data is within sensor specification" ;
VAL_ 2364544254 RelativeBladeHeightFigureOfMerit 3 "Relative Blade Height not available" 2 "Relative Blade Height failed" 1 "Relative Blade Height degraded Data is suspect due to environmental conditions" 0 "Relative Blade Height fully functional Data is within sensor specification" ;
VAL_ 2349006590 VehicleType 1 "Dolly axle" 0 "Towing or towed vehicle" ;
VAL_ 2349006590 BrakeLightSwitch 1 "Switch on" 0 "Switch off" ;
VAL_ 2349006590 ASREngineControlActive 3 "NotAvailable" 2 "Reserved" 1 "ASREngineControlActive" 0 "ASREngnCntrlPassiveButInstalled" ;
VAL_ 2349006590 ASRBreakControlActive 1 "Active" 0 "Passive, but installed" ;
VAL_ 2349006590 VehicleRetarderCtrlActive 1 "Active" 0 "Passive" ;
VAL_ 2349006590 VehicleABSActive 1 "Active" 0 "Passiv, but installed" ;
VAL_ 2566834686 PneumaticControlLine 1 "Towing veh with pn ctrl line" 0 "Towing veh without pn ctrl line" ;
VAL_ 2566834686 ABSOffroadRequest 1 "ABS off-road switch on" 0 "ABS off-road switch off" ;
VAL_ 2566834686 TwoElCircuitsBrakeDemand 1 "Two el. circuit brake available" 0 "One el. circuit brake available" ;
VAL_ 2566834686 VehicleRetarderCtrlActive 1 "Active" 0 "Passive" ;
VAL_ 2550398718 SupplyLineBrakingRequest 1 "Supply line braking request" 0 "No supply line braking request" ;
VAL_ 2550398718 VDCActive 1 "Active" 0 "Passive, but installed" ;
VAL_ 2550398718 AutomTowedVehBreakActive 1 "Active" 0 "Passive" ;
VAL_ 2550398718 VehicleServiceBrakeActive 1 "Active" 0 "Passive" ;
VAL_ 2550398718 VehicleRetarderCtrlActive 1 "Active" 0 "Passive" ;
VAL_ 2550398718 VehicleABSActive 1 "Active" 0 "Passiv, but installed" ;
VAL_ 2566833406 SupplyLineBrakingRequest 1 "Supply line braking request" 0 "No supply line braking request" ;
VAL_ 2566833406 LoadingRampApproachAssist 1 "Assistance active" 0 "Assistance not active" ;
VAL_ 2566833406 SpringBrakeEngaged 1 "Vehicle spring brake is engaged" 0 "Vehicle spring brake is released" ;
VAL_ 2566833406 ElectrLoadPropFunc 1 "Vehicle with el. load proportion" 0 "Vehicle without el. load proport" ;
VAL_ 2566833406 SpringBrakeInstalled 1 "Vehicle with spring brakes" 0 "Vehicle without spring brakes" ;
VAL_ 2566833406 VehicleType 1 "Dolly axle" 0 "Towing or towed vehicle" ;
VAL_ 2566833406 ElecSupplyOfNonBrakingSys 1 "Supply switched on" 0 "Supply switched off" ;
VAL_ 2566833406 AmberWarningSignalReq 1 "Towed vehicle failure indicated" 0 "No towed vehicle failure indicat" ;
VAL_ 2566833406 RedWarningSignalRequest 1 "Towed vehicle failure indicated" 0 "No towed vehicle failure indicat" ;
VAL_ 2566833406 VehicleElectrSupplySuff 1 "Vehicle el. supply sufficient" 0 "Vehicle el. supply insufficient" ;
VAL_ 2566833406 AutomTowedVehBreakActive 1 "Active" 0 "Passive" ;
VAL_ 2566833406 VehicleServiceBrakeActive 1 "Active" 0 "Passive" ;
VAL_ 2566833406 VehicleRetarderCtrlActive 1 "Active" 0 "Passive" ;
VAL_ 2566833406 VehicleABSActive 1 "Active" 0 "Passiv, but installed" ;
VAL_ 2365507326 TyreWheelIdentTemp2 15 "Axle position 15" 14 "Axle position 14" 13 "Axle position 13" 12 "Axle position 12" 11 "Axle position 11" 10 "Axle position 10" 9 "Axle position 9" 8 "Axle position 8" 7 "Axle position 7" 6 "Axle position 6" 5 "Axle position 5" 4 "Axle position 4" 3 "Axle position 3" 2 "Axle position 2" 1 "Axle position 1" 0 "Axle position not identified" ;
VAL_ 2365507326 TyreWheelIdentTemp1 15 "Wheel position 15" 14 "Wheel position 14" 13 "Wheel position 13" 12 "Wheel position 12" 11 "Wheel position 11" 10 "Wheel position 10" 9 "Wheel position 9" 8 "Wheel position 8" 7 "Wheel position 7" 6 "Wheel position 6" 5 "Wheel position 5" 4 "Wheel position 4" 3 "Wheel position 3" 2 "Wheel position 2" 1 "Wheel position 1" 0 "Wheel position not identified" ;
VAL_ 2365507326 TyreWheelIdentPressure2 15 "Axle position 15" 14 "Axle position 14" 13 "Axle position 13" 12 "Axle position 12" 11 "Axle position 11" 10 "Axle position 10" 9 "Axle position 9" 8 "Axle position 8" 7 "Axle position 7" 6 "Axle position 6" 5 "Axle position 5" 4 "Axle position 4" 3 "Axle position 3" 2 "Axle position 2" 1 "Axle position 1" 0 "Axle position not identified" ;
VAL_ 2365507326 TyreWheelIdentPressure1 15 "Wheel position 15" 14 "Wheel position 14" 13 "Wheel position 13" 12 "Wheel position 12" 11 "Wheel position 11" 10 "Wheel position 10" 9 "Wheel position 9" 8 "Wheel position 8" 7 "Wheel position 7" 6 "Wheel position 6" 5 "Wheel position 5" 4 "Wheel position 4" 3 "Wheel position 3" 2 "Wheel position 2" 1 "Wheel position 1" 0 "Wheel position not identified" ;
VAL_ 2365507326 TyreWheelIdentLining2 15 "Axle position 15" 14 "Axle position 14" 13 "Axle position 13" 12 "Axle position 12" 11 "Axle position 11" 10 "Axle position 10" 9 "Axle position 9" 8 "Axle position 8" 7 "Axle position 7" 6 "Axle position 6" 5 "Axle position 5" 4 "Axle position 4" 3 "Axle position 3" 2 "Axle position 2" 1 "Axle position 1" 0 "Axle position not identified" ;
VAL_ 2365507326 TyreWheelIdentLining1 15 "Wheel position 15" 14 "Wheel position 14" 13 "Wheel position 13" 12 "Wheel position 12" 11 "Wheel position 11" 10 "Wheel position 10" 9 "Wheel position 9" 8 "Wheel position 8" 7 "Wheel position 7" 6 "Wheel position 6" 5 "Wheel position 5" 4 "Wheel position 4" 3 "Wheel position 3" 2 "Wheel position 2" 1 "Wheel position 1" 0 "Wheel position not identified" ;
VAL_ 2365507326 VehiclePneumSupplySuff 1 "Pneumatic supply sufficient" 0 "Pneumatic supply insufficient" ;
VAL_ 2365507326 BrakeTemperatureStatus 1 "Brake temperature normal" 0 "Brake temperature out of range" ;
VAL_ 2365507326 BrakeLiningSufficient 1 "Brake linings sufficient" 0 "Brake linings insufficient" ;
VAL_ 2365507326 TyrePressureSufficient 1 "Tyre pressure sufficient" 0 "Tyre pressure insufficient" ;
VAL_ 2565013246 ODDRequest 3 "Take no action" 1 "ODD on" 0 "ODD off" ;
VAL_ 2565013246 AntiTheftDeviceReq 3 "Take no action" 1 "Anti-theft device on" 0 "Anti-theft device off" ;
VAL_ 2565013246 VehicleType 1 "Dolly axle" 0 "Towing or towed vehicle" ;
VAL_ 2365480958 EngineTorqueMode 15 "Not available" 11 "Remote accelerator" 10 "Braking system" 9 "High speed governor" 8 "Torque limiting" 7 "ABS control" 6 "Transmission control" 5 "ASR control" 4 "Road speed governor" 3 "PTO governor" 2 "Cruise control" 1 "Accelerator pedal/operator selec" 0 "Low idle governor/no request (de" ;
VAL_ 2365480958 EngineRunning 1 "Engine running" 0 "Engine not running" ;
VAL_ 2365480958 EngineControlAllowed 1 "Engine control allowed" 0 "Engine control not allowed" ;
VAL_ 2566808062 ClutchIndptdPTOFeedback 1 "Engaged" 0 "Not engaged" ;
VAL_ 2566808062 AccelPedalLowIdleSwitch 1 "In low idle condition" 0 "Not in low idle condition" ;
VAL_ 2566808062 StarterActive 1 "Starter active" 0 "Starter not active" ;
VAL_ 2566808062 TorqueConvtOilTempWarning 2 "Warning" 1 "Prewarning" 0 "No warning" ;
VAL_ 2566808062 PTOControlAllowed 1 "PTO control allowed" 0 "PTO control not allowed" ;
VAL_ 2566808062 SecEngineMtdPTOFeedback 1 "Limits activated" 0 "Limits not activated" ;
VAL_ 2566808062 FirstEngineMtdPTOFeedback 1 "Limits activated" 0 "Limits not activated" ;
VAL_ 2566808062 SecClutchDptdPTOFeedback 1 "Engaged" 0 "Not engaged" ;
VAL_ 2566808062 FirstClutchDpdtPTOFeedback 1 "Engaged" 0 "Not engaged" ;
VAL_ 2566808574 FuelLevelWarning 1 "Fuel level warning on" 0 "Fuel level warning off" ;
VAL_ 2566808574 EngineOilPressureWarning 1 "Warning" 0 "No warning" ;
VAL_ 2566808574 EngineCoolantTempWarning 2 "Warning" 1 "Prewarning" 0 "No warning" ;
VAL_ 2564947710 VehicleType 1 "Dolly axle" 0 "Towing or towed vehicle" ;
VAL_ 2566834430 AntiTheftDeviceStatus 1 "Anti-theft device on" 0 "Anti-theft device off" ;
VAL_ 2566834430 ODDStatus 1 "ODD active" 0 "ODD inactive" ;
VAL_ 2566808318 SecEngineMtdPTOSwitch 1 "Switched on" 0 "Switched off" ;
VAL_ 2566808318 SecClutchDpdtPTOSwitch 1 "Switched on" 0 "Switched off" ;
VAL_ 2566808318 FirstClutchDpdtPTOSwitch 1 "Switched on" 0 "Switched off" ;
VAL_ 2566808318 OperatingPanelActive 1 "Operating panel active" 0 "Operating panel not active" ;
VAL_ 2566808318 RefusePackerStepSwitch 1 "Switched on" 0 "Switched off" ;
VAL_ 2566808318 EngineStopSwitch 1 "Switched on" 0 "Switched off" ;
VAL_ 2566808318 EngineStartSwitch 1 "Switched on" 0 "Switched off" ;
VAL_ 2566808318 StarterLockoutSwitch 1 "Switched on" 0 "Switched off" ;
VAL_ 2566808318 FirstEngineMtdPTOSwitch 1 "Switched on" 0 "Switched off" ;
VAL_ 2566808318 ClutchIndpdtPTOSwitch 1 "Switched on" 0 "Switched off" ;
VAL_ 2566808830 TrailerLeftSideMarkerLight 1 "Lamp(s) lit" 0 "Lamp(s) not lit" ;
VAL_ 2566808830 TrailerLeftReversingLight 1 "Lamp(s) lit" 0 "Lamp(s) not lit" ;
VAL_ 2566808830 TrailerLeftRearWidIndLight 1 "Lamp(s) lit" 0 "Lamp(s) not lit" ;
VAL_ 2566808830 TrailerLeftRearRegPltLight 1 "Lamp(s) lit" 0 "Lamp(s) not lit" ;
VAL_ 2566808830 TrailerLeftRearLight 1 "Lamp(s) lit" 0 "Lamp(s) not lit" ;
VAL_ 2566808830 TrailerLeftRearFogLight 1 "Lamp(s) lit" 0 "Lamp(s) not lit" ;
VAL_ 2566808830 TrailerLeftDirIndLight 1 "Lamp(s) lit" 0 "Lamp(s) not lit" ;
VAL_ 2566808830 TrailerLeftCrnMarkerLight 1 "Lamp(s) lit" 0 "Lamp(s) not lit" ;
VAL_ 2566808830 TrailerInteriorLight 1 "Lamp(s) lit" 0 "Lamp(s) not lit" ;
VAL_ 2566808830 TrailerWorkLamp 1 "Lamp(s) lit" 0 "Lamp(s) not lit" ;
VAL_ 2566808830 TrailerRotatingIdentLight 1 "Lamp(s) lit" 0 "Lamp(s) not lit" ;
VAL_ 2566808830 TrailerRightStopLight 1 "Lamp(s) lit" 0 "Lamp(s) not lit" ;
VAL_ 2566808830 TrailerRightSideMrkLight 1 "Lamp(s) lit" 0 "Lamp(s) not lit" ;
VAL_ 2566808830 TrailerRightReversingLight 1 "Lamp(s) lit" 0 "Lamp(s) not lit" ;
VAL_ 2566808830 TrailRightRearWidIndLight 1 "Lamp(s) lit" 0 "Lamp(s) not lit" ;
VAL_ 2566808830 TrailerRightRearRegPltLight 1 "Lamp(s) lit" 0 "Lamp(s) not lit" ;
VAL_ 2566808830 TrailerRightRearLight 1 "Lamp(s) lit" 0 "Lamp(s) not lit" ;
VAL_ 2566808830 TrailerRightRearFogLight 1 "Lamp(s) lit" 0 "Lamp(s) not lit" ;
VAL_ 2566808830 TrailerRightDirIndLight 1 "Lamp(s) lit" 0 "Lamp(s) not lit" ;
VAL_ 2566808830 TrailerRightCrnMarkerLight 1 "Lamp(s) lit" 0 "Lamp(s) not lit" ;
VAL_ 2566808830 TrailerRearWarningLight 1 "Lamp(s) lit" 0 "Lamp(s) not lit" ;
VAL_ 2566808830 TrailerLeftStopLight 1 "Lamp(s) lit" 0 "Lamp(s) not lit" ;
VAL_ 2564554494 FlowStatus 2 "Overflow" 1 "Wait " 0 "Continue To Send" ;
VAL_ 2564554494 ProtocolCtrlInformation 3 "Flow control " 2 "Consecutive frame" 1 "First frame" 0 "Single frame" ;
VAL_ 2564488958 FlowStatus 2 "Overflow" 1 "Wait " 0 "Continue To Send" ;
VAL_ 2564488958 ProtocolCtrlInformation 3 "Flow control " 2 "Consecutive frame" 1 "First frame" 0 "Single frame" ;
